VERSION ""

NS_ :

BS_:

BU_: PowertrainControlModule AtmosphericSensor SafetyRestraintSystem2 Aftertreatment_2_GasOutlet Aftertreatment_2_GasIntake DieselParticulateFilterControl Turbocharger SafetyRestraintSystem1 CabDisplay2 Aftertreatment_1_GasOutlet Aftertreatment_1_GasIntake OnBoardDataLogger OffBoardDiagnosticTool2 OffBoardDiagnosticTool1 FileServer ParkingBrakeController SeatController2 FanDriveController SteeringColumnUnit CommunicationUnitRadio CommunicationUnitSatellite CommunicationUnitCellular PropulsionBatteryCharger ChassisController2 ChassisController1 EngineValveControl AuxiliaryHeater2 AuxiliaryHeater1 ClutchUnit RampControl InformationSystem1 SuspensionSystemController2 OilSensor VehicleDynamicStability ExhaustEmissionController TransmissionDisplay2 TransmissionDisplay1 ClimateControl2 WaterPumpController RearAxleSteeringController LightingOperatorControl SeatController1 IgnitionController2 IgnitionController1 TirePressureController CabController2 CabController1 PneumaticSystemController SuspensionSystemController1 HydraulicPumpController EnduranceBrakingSystem RetarderExhaustEngine2 OnBoardDiagnosticUnit HeadwayController RetarderExhaustEngine1 CabDisplay1 ManagementComputer VirtualTerminal OffVehicleGateway PowerTakeOffFront HitchControl AuxiliaryValveControl BodyController TractorTrailerBridge1 StarterSystem ElectricalSystem VehicleSecurity VehicleNavigation AerodynamicControl ElectricalChargingSystem ClimateControl1 TripRecorder InstrumentCluster SuspensionDriveAxle2 SuspensionDriveAxle1 SuspensionSteerAxle SteeringController FuelSystem CruiseControl RetarderDriveline RetarderEngine BrakesDriveAxle2 BrakesDriveAxle1 BrakesSystemController BrakesSteerAxle AxleDrive2 AxleDrive1 AxleSteering PowerTakeOff ShiftConsoleSecondary ShiftConsolePrimary Transmission2 Transmission1 Engine2 Engine1

BO_ 2566588926 NTEEV: 68 Vector__XXX
 SG_ Bin17 : 512|32@1+ (1,0) [0|4211081215] "kWh" Vector__XXX
 SG_ Bin16 : 480|32@1+ (1,0) [0|4211081215] "kWh" Vector__XXX
 SG_ Bin15 : 448|32@1+ (1,0) [0|4211081215] "kWh" Vector__XXX
 SG_ Bin14 : 416|32@1+ (1,0) [0|4211081215] "kWh" Vector__XXX
 SG_ Bin13 : 384|32@1+ (1,0) [0|4211081215] "kWh" Vector__XXX
 SG_ Bin12 : 352|32@1+ (1,0) [0|4211081215] "kWh" Vector__XXX
 SG_ Bin11 : 320|32@1+ (1,0) [0|4211081215] "kWh" Vector__XXX
 SG_ Bin10 : 288|32@1+ (1,0) [0|4211081215] "kWh" Vector__XXX
 SG_ Bin9 : 256|32@1+ (1,0) [0|4211081215] "kWh" Vector__XXX
 SG_ Bin8 : 224|32@1+ (1,0) [0|4211081215] "kWh" Vector__XXX
 SG_ Bin7 : 192|32@1+ (1,0) [0|4211081215] "kWh" Vector__XXX
 SG_ Bin6 : 160|32@1+ (1,0) [0|4211081215] "kWh" Vector__XXX
 SG_ Bin5 : 128|32@1+ (1,0) [0|4211081215] "kWh" Vector__XXX
 SG_ Bin4 : 96|32@1+ (1,0) [0|4211081215] "kWh" Vector__XXX
 SG_ Bin3 : 64|32@1+ (1,0) [0|4211081215] "kWh" Vector__XXX
 SG_ Bin2 : 32|32@1+ (1,0) [0|4211081215] "kWh" Vector__XXX
 SG_ Bin1 : 0|32@1+ (1,0) [0|4211081215] "kWh" Vector__XXX

BO_ 2566588670 NTVMV: 68 Vector__XXX
 SG_ Bin17 : 512|32@1+ (5,0) [0|21055406075] "m" Vector__XXX
 SG_ Bin16 : 480|32@1+ (5,0) [0|21055406075] "m" Vector__XXX
 SG_ Bin15 : 448|32@1+ (5,0) [0|21055406075] "m" Vector__XXX
 SG_ Bin14 : 416|32@1+ (5,0) [0|21055406075] "m" Vector__XXX
 SG_ Bin13 : 384|32@1+ (5,0) [0|21055406075] "m" Vector__XXX
 SG_ Bin12 : 352|32@1+ (5,0) [0|21055406075] "m" Vector__XXX
 SG_ Bin11 : 320|32@1+ (5,0) [0|21055406075] "m" Vector__XXX
 SG_ Bin10 : 288|32@1+ (5,0) [0|21055406075] "m" Vector__XXX
 SG_ Bin9 : 256|32@1+ (5,0) [0|21055406075] "m" Vector__XXX
 SG_ Bin8 : 224|32@1+ (5,0) [0|21055406075] "m" Vector__XXX
 SG_ Bin7 : 192|32@1+ (5,0) [0|21055406075] "m" Vector__XXX
 SG_ Bin6 : 160|32@1+ (5,0) [0|21055406075] "m" Vector__XXX
 SG_ Bin5 : 128|32@1+ (5,0) [0|21055406075] "m" Vector__XXX
 SG_ Bin4 : 96|32@1+ (5,0) [0|21055406075] "m" Vector__XXX
 SG_ Bin3 : 64|32@1+ (5,0) [0|21055406075] "m" Vector__XXX
 SG_ Bin2 : 32|32@1+ (5,0) [0|21055406075] "m" Vector__XXX
 SG_ Bin1 : 0|32@1+ (5,0) [0|21055406075] "m" Vector__XXX

BO_ 2566588414 NTEHV: 68 Vector__XXX
 SG_ Bin17 : 512|32@1+ (1,0) [0|4211081215] "s" Vector__XXX
 SG_ Bin16 : 480|32@1+ (1,0) [0|4211081215] "s" Vector__XXX
 SG_ Bin15 : 448|32@1+ (1,0) [0|4211081215] "s" Vector__XXX
 SG_ Bin14 : 416|32@1+ (1,0) [0|4211081215] "s" Vector__XXX
 SG_ Bin13 : 384|32@1+ (1,0) [0|4211081215] "s" Vector__XXX
 SG_ Bin12 : 352|32@1+ (1,0) [0|4211081215] "s" Vector__XXX
 SG_ Bin11 : 320|32@1+ (1,0) [0|4211081215] "s" Vector__XXX
 SG_ Bin10 : 288|32@1+ (1,0) [0|4211081215] "s" Vector__XXX
 SG_ Bin9 : 256|32@1+ (1,0) [0|4211081215] "s" Vector__XXX
 SG_ Bin8 : 224|32@1+ (1,0) [0|4211081215] "s" Vector__XXX
 SG_ Bin7 : 192|32@1+ (1,0) [0|4211081215] "s" Vector__XXX
 SG_ Bin6 : 160|32@1+ (1,0) [0|4211081215] "s" Vector__XXX
 SG_ Bin5 : 128|32@1+ (1,0) [0|4211081215] "s" Vector__XXX
 SG_ Bin4 : 96|32@1+ (1,0) [0|4211081215] "s" Vector__XXX
 SG_ Bin3 : 64|32@1+ (1,0) [0|4211081215] "s" Vector__XXX
 SG_ Bin2 : 32|32@1+ (1,0) [0|4211081215] "s" Vector__XXX
 SG_ Bin1 : 0|32@1+ (1,0) [0|4211081215] "s" Vector__XXX

BO_ 2566588158 NTFCV: 68 Vector__XXX
 SG_ Bin17 : 512|32@1+ (0.05,0) [0|210554060.75] "l" Vector__XXX
 SG_ Bin16 : 480|32@1+ (0.05,0) [0|210554060.75] "l" Vector__XXX
 SG_ Bin15 : 448|32@1+ (0.05,0) [0|210554060.75] "l" Vector__XXX
 SG_ Bin14 : 416|32@1+ (0.05,0) [0|210554060.75] "l" Vector__XXX
 SG_ Bin13 : 384|32@1+ (0.05,0) [0|210554060.75] "l" Vector__XXX
 SG_ Bin12 : 352|32@1+ (0.05,0) [0|210554060.75] "l" Vector__XXX
 SG_ Bin11 : 320|32@1+ (0.05,0) [0|210554060.75] "l" Vector__XXX
 SG_ Bin10 : 288|32@1+ (0.05,0) [0|210554060.75] "l" Vector__XXX
 SG_ Bin9 : 256|32@1+ (0.05,0) [0|210554060.75] "l" Vector__XXX
 SG_ Bin8 : 224|32@1+ (0.05,0) [0|210554060.75] "l" Vector__XXX
 SG_ Bin7 : 192|32@1+ (0.05,0) [0|210554060.75] "l" Vector__XXX
 SG_ Bin6 : 160|32@1+ (0.05,0) [0|210554060.75] "l" Vector__XXX
 SG_ Bin5 : 128|32@1+ (0.05,0) [0|210554060.75] "l" Vector__XXX
 SG_ Bin4 : 96|32@1+ (0.05,0) [0|210554060.75] "l" Vector__XXX
 SG_ Bin3 : 64|32@1+ (0.05,0) [0|210554060.75] "l" Vector__XXX
 SG_ Bin2 : 32|32@1+ (0.05,0) [0|210554060.75] "l" Vector__XXX
 SG_ Bin1 : 0|32@1+ (0.05,0) [0|210554060.75] "l" Vector__XXX

BO_ 2566587902 NTEEEA: 68 Vector__XXX
 SG_ Bin17 : 512|32@1+ (1,0) [0|4211081215] "kWh" Vector__XXX
 SG_ Bin16 : 480|32@1+ (1,0) [0|4211081215] "kWh" Vector__XXX
 SG_ Bin15 : 448|32@1+ (1,0) [0|4211081215] "kWh" Vector__XXX
 SG_ Bin14 : 416|32@1+ (1,0) [0|4211081215] "kWh" Vector__XXX
 SG_ Bin13 : 384|32@1+ (1,0) [0|4211081215] "kWh" Vector__XXX
 SG_ Bin12 : 352|32@1+ (1,0) [0|4211081215] "kWh" Vector__XXX
 SG_ Bin11 : 320|32@1+ (1,0) [0|4211081215] "kWh" Vector__XXX
 SG_ Bin10 : 288|32@1+ (1,0) [0|4211081215] "kWh" Vector__XXX
 SG_ Bin9 : 256|32@1+ (1,0) [0|4211081215] "kWh" Vector__XXX
 SG_ Bin8 : 224|32@1+ (1,0) [0|4211081215] "kWh" Vector__XXX
 SG_ Bin7 : 192|32@1+ (1,0) [0|4211081215] "kWh" Vector__XXX
 SG_ Bin6 : 160|32@1+ (1,0) [0|4211081215] "kWh" Vector__XXX
 SG_ Bin5 : 128|32@1+ (1,0) [0|4211081215] "kWh" Vector__XXX
 SG_ Bin4 : 96|32@1+ (1,0) [0|4211081215] "kWh" Vector__XXX
 SG_ Bin3 : 64|32@1+ (1,0) [0|4211081215] "kWh" Vector__XXX
 SG_ Bin2 : 32|32@1+ (1,0) [0|4211081215] "kWh" Vector__XXX
 SG_ Bin1 : 0|32@1+ (1,0) [0|4211081215] "kWh" Vector__XXX

BO_ 2566587646 NTVMEA: 68 Vector__XXX
 SG_ Bin17 : 512|32@1+ (5,0) [0|21055406075] "m" Vector__XXX
 SG_ Bin16 : 480|32@1+ (5,0) [0|21055406075] "m" Vector__XXX
 SG_ Bin15 : 448|32@1+ (5,0) [0|21055406075] "m" Vector__XXX
 SG_ Bin14 : 416|32@1+ (5,0) [0|21055406075] "m" Vector__XXX
 SG_ Bin13 : 384|32@1+ (5,0) [0|21055406075] "m" Vector__XXX
 SG_ Bin12 : 352|32@1+ (5,0) [0|21055406075] "m" Vector__XXX
 SG_ Bin11 : 320|32@1+ (5,0) [0|21055406075] "m" Vector__XXX
 SG_ Bin10 : 288|32@1+ (5,0) [0|21055406075] "m" Vector__XXX
 SG_ Bin9 : 256|32@1+ (5,0) [0|21055406075] "m" Vector__XXX
 SG_ Bin8 : 224|32@1+ (5,0) [0|21055406075] "m" Vector__XXX
 SG_ Bin7 : 192|32@1+ (5,0) [0|21055406075] "m" Vector__XXX
 SG_ Bin6 : 160|32@1+ (5,0) [0|21055406075] "m" Vector__XXX
 SG_ Bin5 : 128|32@1+ (5,0) [0|21055406075] "m" Vector__XXX
 SG_ Bin4 : 96|32@1+ (5,0) [0|21055406075] "m" Vector__XXX
 SG_ Bin3 : 64|32@1+ (5,0) [0|21055406075] "m" Vector__XXX
 SG_ Bin2 : 32|32@1+ (5,0) [0|21055406075] "m" Vector__XXX
 SG_ Bin1 : 0|32@1+ (5,0) [0|21055406075] "m" Vector__XXX

BO_ 2566587390 NTEHEA: 68 Vector__XXX
 SG_ Bin17 : 512|32@1+ (1,0) [0|4211081215] "s" Vector__XXX
 SG_ Bin16 : 480|32@1+ (1,0) [0|4211081215] "s" Vector__XXX
 SG_ Bin15 : 448|32@1+ (1,0) [0|4211081215] "s" Vector__XXX
 SG_ Bin14 : 416|32@1+ (1,0) [0|4211081215] "s" Vector__XXX
 SG_ Bin13 : 384|32@1+ (1,0) [0|4211081215] "s" Vector__XXX
 SG_ Bin12 : 352|32@1+ (1,0) [0|4211081215] "s" Vector__XXX
 SG_ Bin11 : 320|32@1+ (1,0) [0|4211081215] "s" Vector__XXX
 SG_ Bin10 : 288|32@1+ (1,0) [0|4211081215] "s" Vector__XXX
 SG_ Bin9 : 256|32@1+ (1,0) [0|4211081215] "s" Vector__XXX
 SG_ Bin8 : 224|32@1+ (1,0) [0|4211081215] "s" Vector__XXX
 SG_ Bin7 : 192|32@1+ (1,0) [0|4211081215] "s" Vector__XXX
 SG_ Bin6 : 160|32@1+ (1,0) [0|4211081215] "s" Vector__XXX
 SG_ Bin5 : 128|32@1+ (1,0) [0|4211081215] "s" Vector__XXX
 SG_ Bin4 : 96|32@1+ (1,0) [0|4211081215] "s" Vector__XXX
 SG_ Bin3 : 64|32@1+ (1,0) [0|4211081215] "s" Vector__XXX
 SG_ Bin2 : 32|32@1+ (1,0) [0|4211081215] "s" Vector__XXX
 SG_ Bin1 : 0|32@1+ (1,0) [0|4211081215] "s" Vector__XXX

BO_ 2566587134 NTFCEA: 68 Vector__XXX
 SG_ Bin17 : 512|32@1+ (0.05,0) [0|210554060.75] "l" Vector__XXX
 SG_ Bin16 : 480|32@1+ (0.05,0) [0|210554060.75] "l" Vector__XXX
 SG_ Bin15 : 448|32@1+ (0.05,0) [0|210554060.75] "l" Vector__XXX
 SG_ Bin14 : 416|32@1+ (0.05,0) [0|210554060.75] "l" Vector__XXX
 SG_ Bin13 : 384|32@1+ (0.05,0) [0|210554060.75] "l" Vector__XXX
 SG_ Bin12 : 352|32@1+ (0.05,0) [0|210554060.75] "l" Vector__XXX
 SG_ Bin11 : 320|32@1+ (0.05,0) [0|210554060.75] "l" Vector__XXX
 SG_ Bin10 : 288|32@1+ (0.05,0) [0|210554060.75] "l" Vector__XXX
 SG_ Bin9 : 256|32@1+ (0.05,0) [0|210554060.75] "l" Vector__XXX
 SG_ Bin8 : 224|32@1+ (0.05,0) [0|210554060.75] "l" Vector__XXX
 SG_ Bin7 : 192|32@1+ (0.05,0) [0|210554060.75] "l" Vector__XXX
 SG_ Bin6 : 160|32@1+ (0.05,0) [0|210554060.75] "l" Vector__XXX
 SG_ Bin5 : 128|32@1+ (0.05,0) [0|210554060.75] "l" Vector__XXX
 SG_ Bin4 : 96|32@1+ (0.05,0) [0|210554060.75] "l" Vector__XXX
 SG_ Bin3 : 64|32@1+ (0.05,0) [0|210554060.75] "l" Vector__XXX
 SG_ Bin2 : 32|32@1+ (0.05,0) [0|210554060.75] "l" Vector__XXX
 SG_ Bin1 : 0|32@1+ (0.05,0) [0|210554060.75] "l" Vector__XXX

BO_ 2566586878 GHGTTL: 8 Vector__XXX
 SG_ GHGTrackingActiveTechVehDist : 16|32@1+ (5,0) [0|21055406075] "m" Vector__XXX
 SG_ GHGTrackingActiveTechTime : 8|32@1+ (1,0) [0|4211081215] "s" Vector__XXX
 SG_ GHGTrackingActiveTechIndex : 0|8@1+ (1,0) [0|255] "" Vector__XXX

BO_ 2566586622 GHGTTA: 8 Vector__XXX
 SG_ GHGTrackingActiveTechVehDist : 16|16@1+ (0.25,0) [0|16063.75] "km" Vector__XXX
 SG_ GHGTrackingActiveTechTime : 8|16@1+ (10,0) [0|642550] "s" Vector__XXX
 SG_ GHGTrackingActiveTechIndex : 0|8@1+ (1,0) [0|255] "" Vector__XXX

BO_ 2566586366 GHGTTS: 8 Vector__XXX
 SG_ GHGTrackingActiveTechVehDist : 16|16@1+ (0.25,0) [0|16063.75] "km" Vector__XXX
 SG_ GHGTrackingActiveTechTime : 8|16@1+ (10,0) [0|642550] "s" Vector__XXX
 SG_ GHGTrackingActiveTechIndex : 0|8@1+ (1,0) [0|255] "" Vector__XXX

BO_ 2566586110 GHGTA: 28 Vector__XXX
 SG_ StopStartTechRunTime : 208|16@1+ (10,0) [0|642550] "s" Vector__XXX
 SG_ AutoEngShutdownTechActCount : 192|16@1+ (1,0) [0|64255] "" Vector__XXX
 SG_ EngPwrTakeOffFuelConsumption : 176|16@1+ (0.5,0) [0|32127.5] "l" Vector__XXX
 SG_ EngPwrTakeOffRunTime : 160|16@1+ (10,0) [0|642550] "s" Vector__XXX
 SG_ EngIdleFuelConsumption : 144|16@1+ (0.5,0) [0|32127.5] "l" Vector__XXX
 SG_ IdleRunTime : 128|16@1+ (10,0) [0|642550] "s" Vector__XXX
 SG_ UrbanSpdRunTime : 112|16@1+ (10,0) [0|642550] "s" Vector__XXX
 SG_ PosKineticEnergyNumerator : 80|32@1+ (1,0) [0|4211081215] "km²/h²" Vector__XXX
 SG_ EngOutEnergy : 64|16@1+ (1,0) [0|64255] "kWh" Vector__XXX
 SG_ EngFuelConsumption : 48|16@1+ (0.5,0) [0|32127.5] "l" Vector__XXX
 SG_ VehFuelConsumption : 32|16@1+ (0.5,0) [0|32127.5] "l" Vector__XXX
 SG_ VehDist : 16|16@1+ (0.25,0) [0|16063.75] "km" Vector__XXX
 SG_ EngRunTime : 0|16@1+ (10,0) [0|642550] "s" Vector__XXX

BO_ 2566585854 GHGTS: 28 Vector__XXX
 SG_ StopStartTechRunTime : 208|16@1+ (10,0) [0|642550] "s" Vector__XXX
 SG_ AutoEngShutdownTechActCount : 192|16@1+ (1,0) [0|64255] "" Vector__XXX
 SG_ EngPwrTakeOffFuelConsumption : 176|16@1+ (0.5,0) [0|32127.5] "l" Vector__XXX
 SG_ EngPwrTakeOffRunTime : 160|16@1+ (10,0) [0|642550] "s" Vector__XXX
 SG_ EngIdleFuelConsumption : 144|16@1+ (0.5,0) [0|32127.5] "l" Vector__XXX
 SG_ IdleRunTime : 128|16@1+ (10,0) [0|642550] "s" Vector__XXX
 SG_ UrbanSpdRunTime : 112|16@1+ (10,0) [0|642550] "s" Vector__XXX
 SG_ PosKineticEnergyNumerator : 80|32@1+ (1,0) [0|4211081215] "km²/h²" Vector__XXX
 SG_ EngOutEnergy : 64|16@1+ (1,0) [0|64255] "kWh" Vector__XXX
 SG_ EngFuelConsumption : 48|16@1+ (0.5,0) [0|32127.5] "l" Vector__XXX
 SG_ VehFuelConsumption : 32|16@1+ (0.5,0) [0|32127.5] "l" Vector__XXX
 SG_ VehDist : 16|16@1+ (0.25,0) [0|16063.75] "km" Vector__XXX
 SG_ EngRunTime : 0|16@1+ (10,0) [0|642550] "s" Vector__XXX

BO_ 2566585598 GHGTL: 52 Vector__XXX
 SG_ StopStartTechRunTime : 384|32@1+ (1,0) [0|4211081215] "s" Vector__XXX
 SG_ AutoEngShutdownTechActCount : 352|32@1+ (1,0) [0|4294967295] "" Vector__XXX
 SG_ EngPwrTakeOffFuelConsumption : 320|32@1+ (0.05,0) [0|210554060.75] "l" Vector__XXX
 SG_ EngPwrTakeOffRunTime : 288|32@1+ (1,0) [0|4211081215] "s" Vector__XXX
 SG_ EngIdleFuelConsumption : 256|32@1+ (0.05,0) [0|210554060.75] "l" Vector__XXX
 SG_ IdleRunTime : 224|32@1+ (1,0) [0|4211081215] "s" Vector__XXX
 SG_ UrbanSpdRunTime : 192|32@1+ (1,0) [0|4211081215] "s" Vector__XXX
 SG_ PosKineticEnergyNumerator : 160|32@1+ (5,0) [0|21055406075] "km²/h²" Vector__XXX
 SG_ EngOutEnergy : 128|32@1+ (1,0) [0|4211081215] "kWh" Vector__XXX
 SG_ EngFuelConsumption : 96|32@1+ (0.05,0) [0|210554060.75] "l" Vector__XXX
 SG_ VehFuelConsumption : 64|32@1+ (0.05,0) [0|210554060.75] "l" Vector__XXX
 SG_ VehDist : 32|32@1+ (5,0) [0|21055406075] "m" Vector__XXX
 SG_ EngRunTime : 0|32@1+ (1,0) [0|4211081215] "s" Vector__XXX

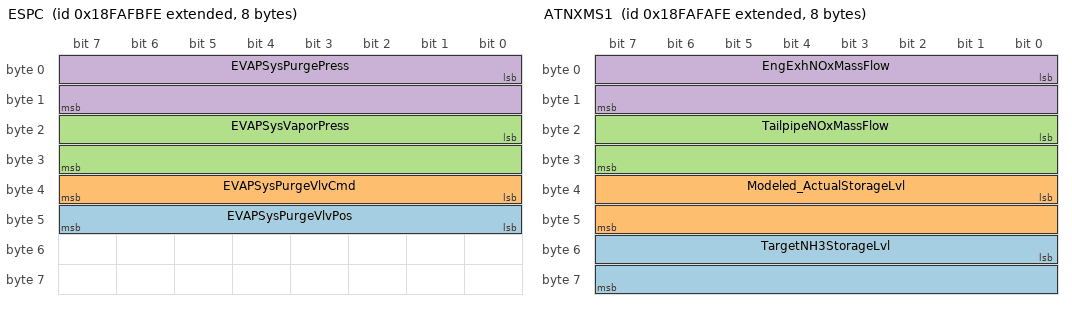
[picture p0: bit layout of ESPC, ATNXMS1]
BO_ 2566585342 ESPC: 8 Vector__XXX
 SG_ EVAPSysPurgeVlvPos : 40|8@1+ (0.4,0) [0|100] "%" Vector__XXX
 SG_ EVAPSysPurgeVlvCmd : 32|8@1+ (0.4,0) [0|100] "%" Vector__XXX
 SG_ EVAPSysVaporPress : 16|16@1+ (4,0) [0|257020] "Pa" Vector__XXX
 SG_ EVAPSysPurgePress : 0|16@1+ (4,0) [0|257020] "Pa" Vector__XXX

BO_ 2566585086 ATNXMS1: 8 Vector__XXX
 SG_ TargetNH3StorageLvl : 48|16@1+ (1,0) [0|64255] "mg/l" Vector__XXX
 SG_ Modeled_ActualStorageLvl : 32|16@1+ (1,0) [0|64255] "mg/l" Vector__XXX
 SG_ TailpipeNOxMassFlow : 16|16@1+ (0.0001,0) [0|6.4255] "g/s" Vector__XXX
 SG_ EngExhNOxMassFlow : 0|16@1+ (0.0001,0) [0|6.4255] "g/s" Vector__XXX

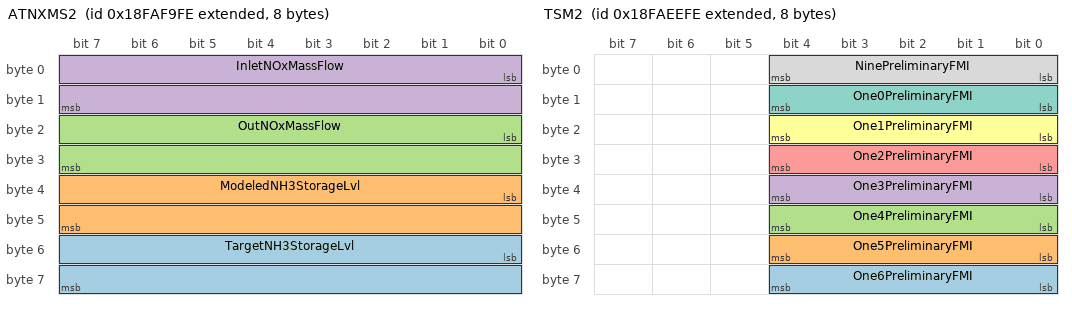
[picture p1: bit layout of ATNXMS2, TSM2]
BO_ 2566584830 ATNXMS2: 8 Vector__XXX
 SG_ TargetNH3StorageLvl : 48|16@1+ (1,0) [0|64255] "mg/l" Vector__XXX
 SG_ ModeledNH3StorageLvl : 32|16@1+ (1,0) [0|64255] "mg/l" Vector__XXX
 SG_ OutNOxMassFlow : 16|16@1+ (0.0001,0) [0|6.4255] "g/s" Vector__XXX
 SG_ InletNOxMassFlow : 0|16@1+ (0.0001,0) [0|6.4255] "g/s" Vector__XXX

BO_ 2566584318 AT1HI3: 32 Vector__XXX
 SG_ TotalTimeSCRInletTempBelow200Cel : 224|32@1+ (1,0) [0|4211081215] "s" Vector__XXX
 SG_ TotalEngRuntimeWithNoDEFDel : 192|32@1+ (1,0) [0|4211081215] "s" Vector__XXX
 SG_ EndingEngVehDist3 : 160|32@1+ (5,0) [0|21055406075] "m" Vector__XXX
 SG_ StartingEngVehDist3 : 128|32@1+ (5,0) [0|21055406075] "m" Vector__XXX
 SG_ EndingEngVehDist2 : 96|32@1+ (0.125,0) [0|526385151.875] "km" Vector__XXX
 SG_ StartingEngVehDist2 : 64|32@1+ (5,0) [0|21055406075] "m" Vector__XXX
 SG_ EndingEngVehDist1 : 32|32@1+ (5,0) [0|21055406075] "m" Vector__XXX
 SG_ StartingEngVehDist1 : 0|32@1+ (5,0) [0|21055406075] "m" Vector__XXX

BO_ 2566584062 HCDIOA: 16 Vector__XXX
 SG_ GridEnergyIntoTheBat : 112|16@1+ (1,0) [0|64255] "kWh" Vector__XXX
 SG_ GridEnergyChargeDepletingEngRun : 96|16@1+ (1,0) [0|64255] "kWh" Vector__XXX
 SG_ GridEnergyChargeDepletingEngOff : 80|16@1+ (1,0) [0|64255] "kWh" Vector__XXX
 SG_ FuelInDriverSelChargeIncOp : 64|16@1+ (0.5,0) [0|32127.5] "l" Vector__XXX
 SG_ FuelInChargeDepletingOp : 48|16@1+ (0.5,0) [0|32127.5] "l" Vector__XXX
 SG_ DistInDriverSelChargeIncOp : 32|16@1+ (0.25,0) [0|16063.75] "km" Vector__XXX
 SG_ DistInChargeDepletingEngRun : 16|16@1+ (0.25,0) [0|16063.75] "km" Vector__XXX
 SG_ DistInChargeDepletingEngOff : 0|16@1+ (0.25,0) [0|16063.75] "km" Vector__XXX

BO_ 2566583806 HCDIOS: 16 Vector__XXX
 SG_ GridEnergyIntoTheBat : 112|16@1+ (1,0) [0|64255] "kWh" Vector__XXX
 SG_ GridEnergyChargeDepletingEngRun : 96|16@1+ (1,0) [0|64255] "kWh" Vector__XXX
 SG_ GridEnergyChargeDepletingEngOff : 80|16@1+ (1,0) [0|64255] "kWh" Vector__XXX
 SG_ FuelInDriverSelChargeIncOp : 64|16@1+ (0.5,0) [0|32127.5] "l" Vector__XXX
 SG_ FuelInChargeDepletingOp : 48|16@1+ (0.5,0) [0|32127.5] "l" Vector__XXX
 SG_ DistInDriverSelChargeIncOp : 32|16@1+ (0.25,0) [0|16063.75] "km" Vector__XXX
 SG_ DistInChargeDepletingEngRun : 16|16@1+ (0.25,0) [0|16063.75] "km" Vector__XXX
 SG_ DistInChargeDepletingEngOff : 0|16@1+ (0.25,0) [0|16063.75] "km" Vector__XXX

BO_ 2566583550 HCDIOL: 32 Vector__XXX
 SG_ GridEnergyIntoTheBat : 224|32@1+ (1,0) [0|4211081215] "kWh" Vector__XXX
 SG_ GridEnergyChargeDepletingEngRun : 192|32@1+ (1,0) [0|4211081215] "kWh" Vector__XXX
 SG_ GridEnergyChargeDepletingEngOff : 160|32@1+ (1,0) [0|4211081215] "kWh" Vector__XXX
 SG_ FuelInDriverSelChargeIncOp : 128|32@1+ (0.5,0) [0|2105540607.5] "l" Vector__XXX
 SG_ FuelInChargeDepletingOp : 96|32@1+ (0.5,0) [0|2105540607.5] "l" Vector__XXX
 SG_ DistInDriverSelChargeIncOp : 64|32@1+ (5,0) [0|21055406075] "m" Vector__XXX
 SG_ DistInChargeDepletingEngRun : 32|32@1+ (5,0) [0|21055406075] "m" Vector__XXX
 SG_ DistInChargeDepletingEngOff : 0|32@1+ (5,0) [0|21055406075] "m" Vector__XXX

BO_ 2566583294 PSATA: 8 Vector__XXX
 SG_ UrbanPropulsionSysActiveTime : 32|16@1+ (10,0) [0|642550] "s" Vector__XXX
 SG_ IdlePropulsionSysActiveTime : 16|16@1+ (10,0) [0|642550] "s" Vector__XXX
 SG_ PropulsionSysActiveTime : 0|16@1+ (10,0) [0|642550] "s" Vector__XXX

BO_ 2566583038 PSATS: 8 Vector__XXX
 SG_ UrbanPropulsionSysActiveTime : 32|16@1+ (10,0) [0|642550] "s" Vector__XXX
 SG_ IdlePropulsionSysActiveTime : 16|16@1+ (10,0) [0|642550] "s" Vector__XXX
 SG_ RecentPropulsionSysActiveTime : 0|16@1+ (10,0) [0|642550] "s" Vector__XXX

BO_ 2566582782 PSATL: 12 Vector__XXX
 SG_ UrbanPropulsionSysActiveTime : 64|32@1+ (1,0) [0|4211081215] "s" Vector__XXX
 SG_ IdlePropulsionSysActiveTime : 32|32@1+ (1,0) [0|4211081215] "s" Vector__XXX
 SG_ PropulsionSysActiveTime : 0|32@1+ (1,0) [0|4211081215] "s" Vector__XXX

BO_ 2566582526 A1SCRSI3: 8 Vector__XXX
 SG_ DEFUsedThisOperatingCycle : 8|16@1+ (0.1,0) [0|6425.5] "l" Vector__XXX
 SG_ NormalizedConversionEfficiency : 0|8@1+ (0.4,0) [0|100] "%" Vector__XXX

BO_ 2566582270 A2SCRSI3: 8 Vector__XXX
 SG_ NormalizedConversionEfficiency : 0|8@1+ (0.4,0) [0|100] "%" Vector__XXX

BO_ 2566582014 TSM2: 8 Vector__XXX
 SG_ One6PreliminaryFMI : 56|5@1+ (1,0) [0|31] "" Vector__XXX
 SG_ One5PreliminaryFMI : 48|5@1+ (1,0) [0|31] "" Vector__XXX
 SG_ One4PreliminaryFMI : 40|5@1+ (1,0) [0|31] "" Vector__XXX
 SG_ One3PreliminaryFMI : 32|5@1+ (1,0) [0|31] "" Vector__XXX
 SG_ One2PreliminaryFMI : 24|5@1+ (1,0) [0|31] "" Vector__XXX
 SG_ One1PreliminaryFMI : 16|5@1+ (1,0) [0|31] "" Vector__XXX
 SG_ One0PreliminaryFMI : 8|5@1+ (1,0) [0|31] "" Vector__XXX
 SG_ NinePreliminaryFMI : 0|5@1+ (1,0) [0|31] "" Vector__XXX

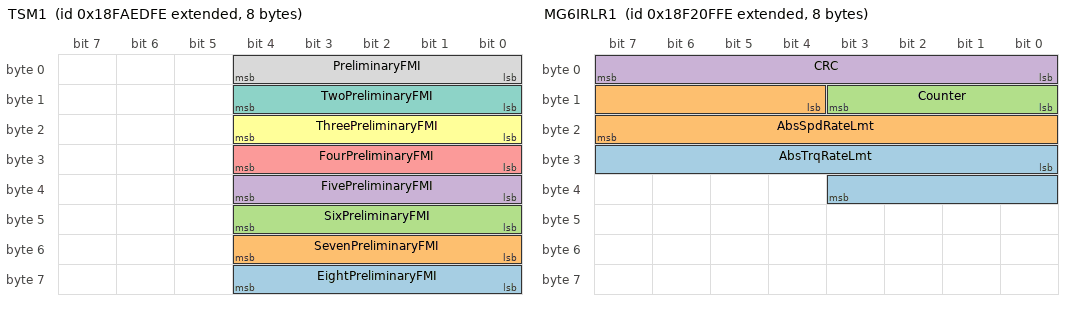
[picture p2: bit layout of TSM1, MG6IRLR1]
BO_ 2566581758 TSM1: 8 Vector__XXX
 SG_ EightPreliminaryFMI : 56|5@1+ (1,0) [0|31] "" Vector__XXX
 SG_ SevenPreliminaryFMI : 48|5@1+ (1,0) [0|31] "" Vector__XXX
 SG_ SixPreliminaryFMI : 40|5@1+ (1,0) [0|31] "" Vector__XXX
 SG_ FivePreliminaryFMI : 32|5@1+ (1,0) [0|31] "" Vector__XXX
 SG_ FourPreliminaryFMI : 24|5@1+ (1,0) [0|31] "" Vector__XXX
 SG_ ThreePreliminaryFMI : 16|5@1+ (1,0) [0|31] "" Vector__XXX
 SG_ TwoPreliminaryFMI : 8|5@1+ (1,0) [0|31] "" Vector__XXX
 SG_ PreliminaryFMI : 0|5@1+ (1,0) [0|31] "" Vector__XXX

BO_ 2566000638 MG6IRLR1: 8 Vector__XXX
 SG_ AbsTrqRateLmt : 24|12@1+ (2,0) [0|8030] "%/s" Vector__XXX
 SG_ AbsSpdRateLmt : 12|12@1+ (0.25,0) [0|1003.75] "%/s" Vector__XXX
 SG_ Counter : 8|4@1+ (1,0) [0|15] "" Vector__XXX
 SG_ CRC : 0|8@1+ (1,0) [0|255] "" Vector__XXX

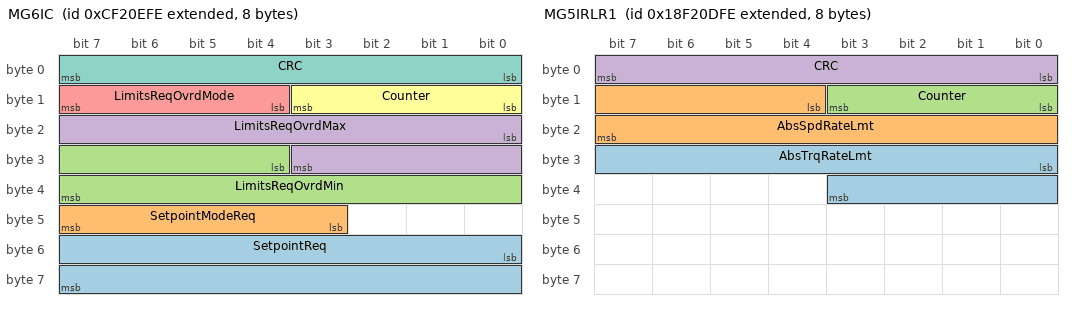
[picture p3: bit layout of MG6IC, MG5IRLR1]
BO_ 2364673790 MG6IC: 8 Vector__XXX
 SG_ SetpointReq : 48|16@1+ (0.00390625,-125) [-125|125.99609375] "%" Vector__XXX
 SG_ SetpointModeReq : 43|5@1+ (1,0) [0|31] "" Vector__XXX
 SG_ LimitsReqOvrdMin : 28|12@1+ (0.0625,-125) [-125|125.9375] "%" Vector__XXX
 SG_ LimitsReqOvrdMax : 16|12@1+ (0.0625,-125) [-125|125.9375] "%" Vector__XXX
 SG_ LimitsReqOvrdMode : 12|4@1+ (1,0) [0|15] "" Vector__XXX
 SG_ Counter : 8|4@1+ (1,0) [0|15] "" Vector__XXX
 SG_ CRC : 0|8@1+ (1,0) [0|255] "" Vector__XXX

BO_ 2566000126 MG5IRLR1: 8 Vector__XXX
 SG_ AbsTrqRateLmt : 24|12@1+ (2,0) [0|8030] "%/s" Vector__XXX
 SG_ AbsSpdRateLmt : 12|12@1+ (0.25,0) [0|1003.75] "%/s" Vector__XXX
 SG_ Counter : 8|4@1+ (1,0) [0|15] "" Vector__XXX
 SG_ CRC : 0|8@1+ (1,0) [0|255] "" Vector__XXX

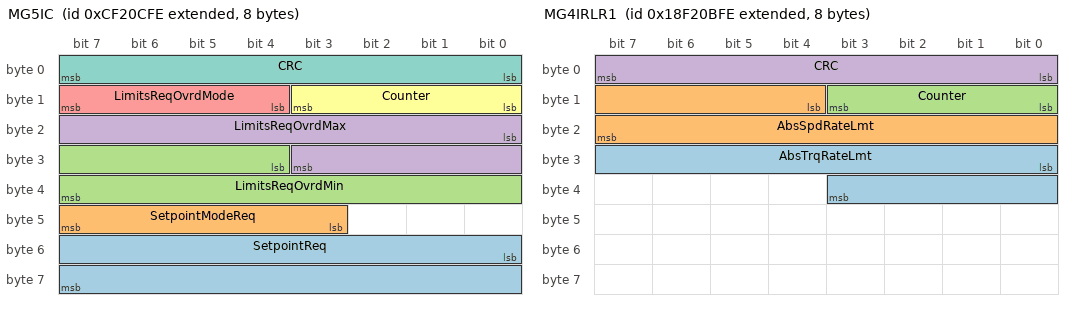
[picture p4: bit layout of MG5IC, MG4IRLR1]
BO_ 2364673278 MG5IC: 8 Vector__XXX
 SG_ SetpointReq : 48|16@1+ (0.00390625,-125) [-125|125.99609375] "%" Vector__XXX
 SG_ SetpointModeReq : 43|5@1+ (1,0) [0|31] "" Vector__XXX
 SG_ LimitsReqOvrdMin : 28|12@1+ (0.0625,-125) [-125|125.9375] "%" Vector__XXX
 SG_ LimitsReqOvrdMax : 16|12@1+ (0.0625,-125) [-125|125.9375] "%" Vector__XXX
 SG_ LimitsReqOvrdMode : 12|4@1+ (1,0) [0|15] "" Vector__XXX
 SG_ Counter : 8|4@1+ (1,0) [0|15] "" Vector__XXX
 SG_ CRC : 0|8@1+ (1,0) [0|255] "" Vector__XXX

BO_ 2565999614 MG4IRLR1: 8 Vector__XXX
 SG_ AbsTrqRateLmt : 24|12@1+ (2,0) [0|8030] "%/s" Vector__XXX
 SG_ AbsSpdRateLmt : 12|12@1+ (0.25,0) [0|1003.75] "%/s" Vector__XXX
 SG_ Counter : 8|4@1+ (1,0) [0|15] "" Vector__XXX
 SG_ CRC : 0|8@1+ (1,0) [0|255] "" Vector__XXX

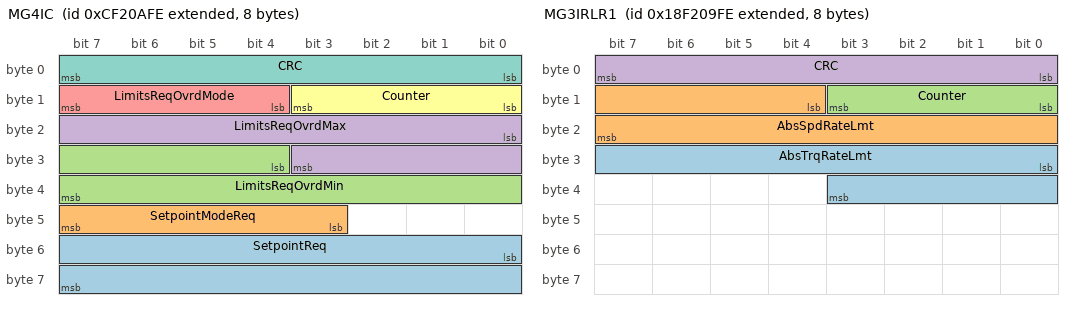
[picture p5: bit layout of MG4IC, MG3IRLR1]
BO_ 2364672766 MG4IC: 8 Vector__XXX
 SG_ SetpointReq : 48|16@1+ (0.00390625,-125) [-125|125.99609375] "%" Vector__XXX
 SG_ SetpointModeReq : 43|5@1+ (1,0) [0|31] "" Vector__XXX
 SG_ LimitsReqOvrdMin : 28|12@1+ (0.0625,-125) [-125|125.9375] "%" Vector__XXX
 SG_ LimitsReqOvrdMax : 16|12@1+ (0.0625,-125) [-125|125.9375] "%" Vector__XXX
 SG_ LimitsReqOvrdMode : 12|4@1+ (1,0) [0|15] "" Vector__XXX
 SG_ Counter : 8|4@1+ (1,0) [0|15] "" Vector__XXX
 SG_ CRC : 0|8@1+ (1,0) [0|255] "" Vector__XXX

BO_ 2565999102 MG3IRLR1: 8 Vector__XXX
 SG_ AbsTrqRateLmt : 24|12@1+ (2,0) [0|8030] "%/s" Vector__XXX
 SG_ AbsSpdRateLmt : 12|12@1+ (0.25,0) [0|1003.75] "%/s" Vector__XXX
 SG_ Counter : 8|4@1+ (1,0) [0|15] "" Vector__XXX
 SG_ CRC : 0|8@1+ (1,0) [0|255] "" Vector__XXX

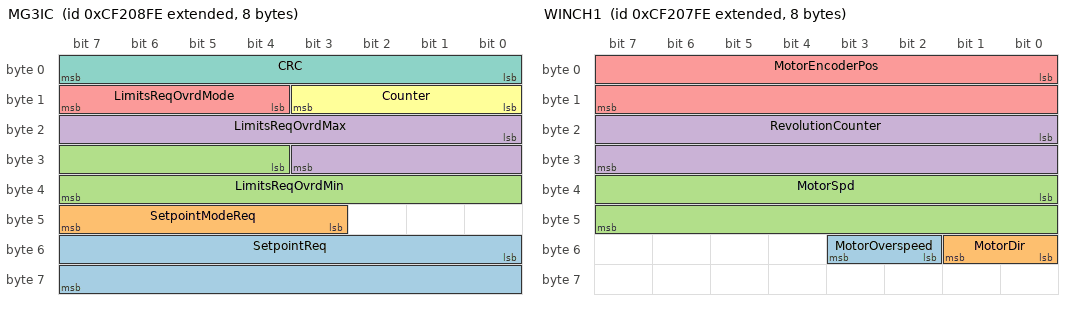
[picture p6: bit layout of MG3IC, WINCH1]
BO_ 2364672254 MG3IC: 8 Vector__XXX
 SG_ SetpointReq : 48|16@1+ (0.00390625,-125) [-125|125.99609375] "%" Vector__XXX
 SG_ SetpointModeReq : 43|5@1+ (1,0) [0|31] "" Vector__XXX
 SG_ LimitsReqOvrdMin : 28|12@1+ (0.0625,-125) [-125|125.9375] "%" Vector__XXX
 SG_ LimitsReqOvrdMax : 16|12@1+ (0.0625,-125) [-125|125.9375] "%" Vector__XXX
 SG_ LimitsReqOvrdMode : 12|4@1+ (1,0) [0|15] "" Vector__XXX
 SG_ Counter : 8|4@1+ (1,0) [0|15] "" Vector__XXX
 SG_ CRC : 0|8@1+ (1,0) [0|255] "" Vector__XXX

BO_ 2364671998 WINCH1: 8 Vector__XXX
 SG_ MotorOverspeed : 50|2@1+ (1,0) [0|3] "" Vector__XXX
 SG_ MotorDir : 48|2@1+ (1,0) [0|3] "" Vector__XXX
 SG_ MotorSpd : 32|16@1+ (0.125,0) [0|8031.875] "rpm" Vector__XXX
 SG_ RevolutionCounter : 16|16@1+ (1,-32128) [-32128|32127] "" Vector__XXX
 SG_ MotorEncoderPos : 0|16@1+ (1,0) [0|32767] "" Vector__XXX

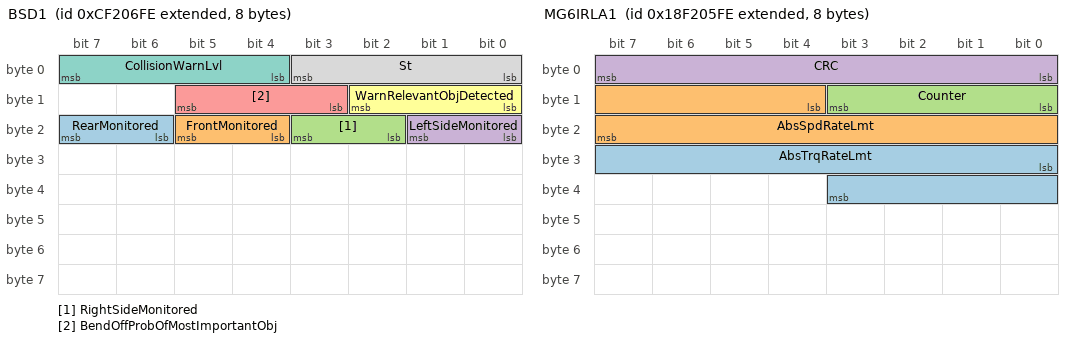
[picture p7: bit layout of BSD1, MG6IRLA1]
BO_ 2364671742 BSD1: 8 Vector__XXX
 SG_ RearMonitored : 22|2@1+ (1,0) [0|3] "" Vector__XXX
 SG_ FrontMonitored : 20|2@1+ (1,0) [0|3] "" Vector__XXX
 SG_ RightSideMonitored : 18|2@1+ (1,0) [0|3] "" Vector__XXX
 SG_ LeftSideMonitored : 16|2@1+ (1,0) [0|3] "" Vector__XXX
 SG_ BendOffProbOfMostImportantObj : 11|3@1+ (1,0) [0|7] "" Vector__XXX
 SG_ WarnRelevantObjDetected : 8|3@1+ (1,0) [0|7] "" Vector__XXX
 SG_ CollisionWarnLvl : 4|4@1+ (1,0) [0|15] "" Vector__XXX
 SG_ St : 0|4@1+ (1,0) [0|15] "" Vector__XXX

BO_ 2565998078 MG6IRLA1: 8 Vector__XXX
 SG_ AbsTrqRateLmt : 24|12@1+ (2,0) [0|8030] "%/s" Vector__XXX
 SG_ AbsSpdRateLmt : 12|12@1+ (0.25,0) [0|1003.75] "%/s" Vector__XXX
 SG_ Counter : 8|4@1+ (1,0) [0|15] "" Vector__XXX
 SG_ CRC : 0|8@1+ (1,0) [0|255] "" Vector__XXX

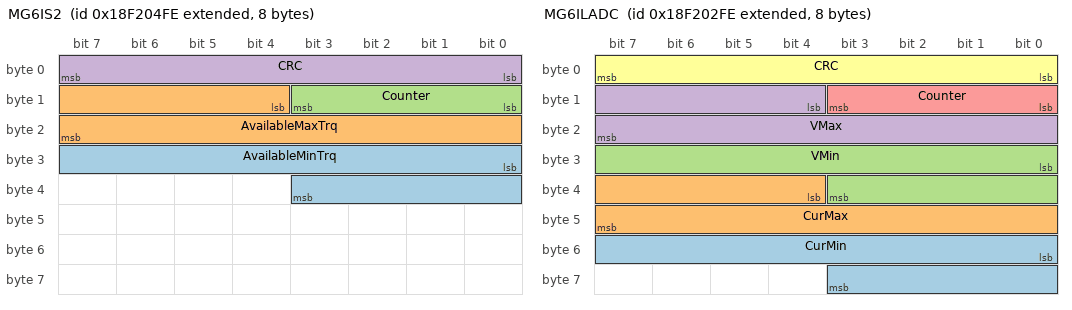
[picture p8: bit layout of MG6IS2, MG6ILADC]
BO_ 2565997822 MG6IS2: 8 Vector__XXX
 SG_ AvailableMinTrq : 24|12@1+ (0.0625,-125) [-125|125.9375] "%" Vector__XXX
 SG_ AvailableMaxTrq : 12|12@1+ (0.0625,-125) [-125|125.9375] "%" Vector__XXX
 SG_ Counter : 8|4@1+ (1,0) [0|15] "" Vector__XXX
 SG_ CRC : 0|8@1+ (1,0) [0|255] "" Vector__XXX

BO_ 2565997566 MG6ILV: 8 Vector__XXX
 SG_ UnswitchedSLIV : 16|16@1+ (0.05,0) [0|3212.75] "V" Vector__XXX
 SG_ SwitchedIgntV : 0|16@1+ (0.05,0) [0|3212.75] "V" Vector__XXX

BO_ 2565997310 MG6ILADC: 8 Vector__XXX
 SG_ CurMin : 48|12@1+ (0.0625,-125) [-125|125.9375] "%" Vector__XXX
 SG_ CurMax : 36|12@1+ (0.0625,-125) [-125|125.9375] "%" Vector__XXX
 SG_ VMin : 24|12@1+ (0.0625,-125) [-125|125.9375] "%" Vector__XXX
 SG_ VMax : 12|12@1+ (0.0625,-125) [-125|125.9375] "%" Vector__XXX
 SG_ Counter : 8|4@1+ (1,0) [0|15] "" Vector__XXX
 SG_ CRC : 0|8@1+ (1,0) [0|255] "" Vector__XXX

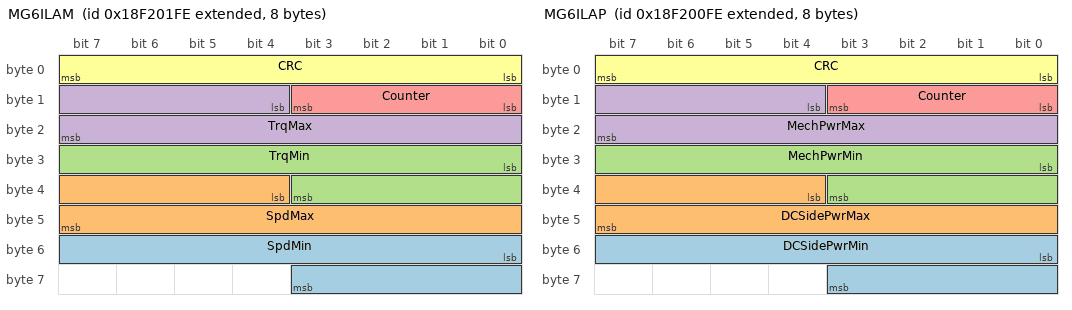
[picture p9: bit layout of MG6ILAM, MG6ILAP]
BO_ 2565997054 MG6ILAM: 8 Vector__XXX
 SG_ SpdMin : 48|12@1+ (0.0625,-125) [-125|125.9375] "%" Vector__XXX
 SG_ SpdMax : 36|12@1+ (0.0625,-125) [-125|125.9375] "%" Vector__XXX
 SG_ TrqMin : 24|12@1+ (0.0625,-125) [-125|125.9375] "%" Vector__XXX
 SG_ TrqMax : 12|12@1+ (0.0625,-125) [-125|125.9375] "%" Vector__XXX
 SG_ Counter : 8|4@1+ (1,0) [0|15] "" Vector__XXX
 SG_ CRC : 0|8@1+ (1,0) [0|255] "" Vector__XXX

BO_ 2565996798 MG6ILAP: 8 Vector__XXX
 SG_ DCSidePwrMin : 48|12@1+ (0.0625,-125) [-125|125.9375] "%" Vector__XXX
 SG_ DCSidePwrMax : 36|12@1+ (0.0625,-125) [-125|125.9375] "%" Vector__XXX
 SG_ MechPwrMin : 24|12@1+ (0.0625,-125) [-125|125.9375] "%" Vector__XXX
 SG_ MechPwrMax : 12|12@1+ (0.0625,-125) [-125|125.9375] "%" Vector__XXX
 SG_ Counter : 8|4@1+ (1,0) [0|15] "" Vector__XXX
 SG_ CRC : 0|8@1+ (1,0) [0|255] "" Vector__XXX

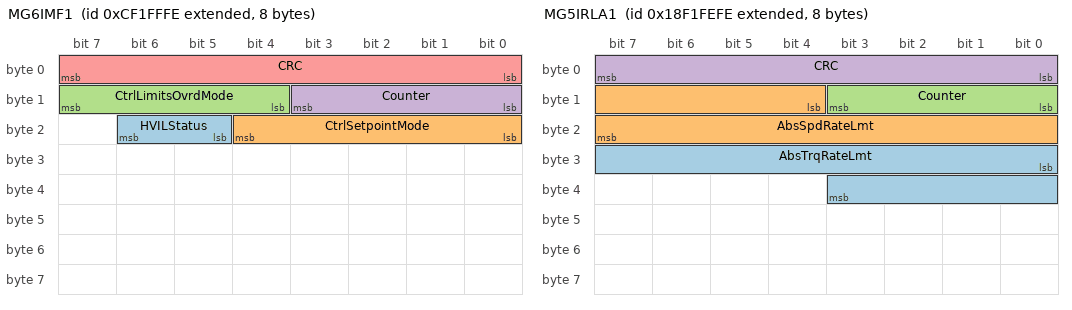
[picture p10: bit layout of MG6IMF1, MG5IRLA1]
BO_ 2364669950 MG6IMF1: 8 Vector__XXX
 SG_ HVILStatus : 21|2@1+ (1,0) [0|3] "" Vector__XXX
 SG_ CtrlSetpointMode : 16|5@1+ (1,0) [0|31] "" Vector__XXX
 SG_ CtrlLimitsOvrdMode : 12|4@1+ (1,0) [0|15] "" Vector__XXX
 SG_ Counter : 8|4@1+ (1,0) [0|15] "" Vector__XXX
 SG_ CRC : 0|8@1+ (1,0) [0|255] "" Vector__XXX

BO_ 2565996286 MG5IRLA1: 8 Vector__XXX
 SG_ AbsTrqRateLmt : 24|12@1+ (2,0) [0|8030] "%/s" Vector__XXX
 SG_ AbsSpdRateLmt : 12|12@1+ (0.25,0) [0|1003.75] "%/s" Vector__XXX
 SG_ Counter : 8|4@1+ (1,0) [0|15] "" Vector__XXX
 SG_ CRC : 0|8@1+ (1,0) [0|255] "" Vector__XXX

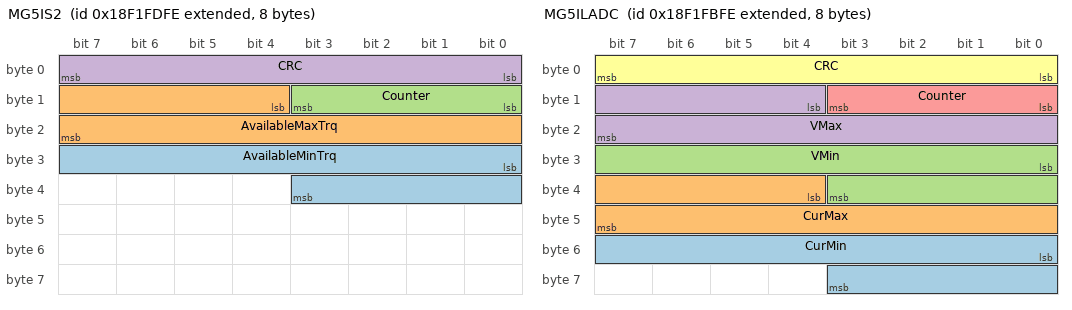
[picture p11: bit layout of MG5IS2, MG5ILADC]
BO_ 2565996030 MG5IS2: 8 Vector__XXX
 SG_ AvailableMinTrq : 24|12@1+ (0.0625,-125) [-125|125.9375] "%" Vector__XXX
 SG_ AvailableMaxTrq : 12|12@1+ (0.0625,-125) [-125|125.9375] "%" Vector__XXX
 SG_ Counter : 8|4@1+ (1,0) [0|15] "" Vector__XXX
 SG_ CRC : 0|8@1+ (1,0) [0|255] "" Vector__XXX

BO_ 2565995774 MG5ILV: 8 Vector__XXX
 SG_ UnswitchedSLIV : 16|16@1+ (0.05,0) [0|3212.75] "V" Vector__XXX
 SG_ SwitchedIgntV : 0|16@1+ (0.05,0) [0|3212.75] "V" Vector__XXX

BO_ 2565995518 MG5ILADC: 8 Vector__XXX
 SG_ CurMin : 48|12@1+ (0.0625,-125) [-125|125.9375] "%" Vector__XXX
 SG_ CurMax : 36|12@1+ (0.0625,-125) [-125|125.9375] "%" Vector__XXX
 SG_ VMin : 24|12@1+ (0.0625,-125) [-125|125.9375] "%" Vector__XXX
 SG_ VMax : 12|12@1+ (0.0625,-125) [-125|125.9375] "%" Vector__XXX
 SG_ Counter : 8|4@1+ (1,0) [0|15] "" Vector__XXX
 SG_ CRC : 0|8@1+ (1,0) [0|255] "" Vector__XXX

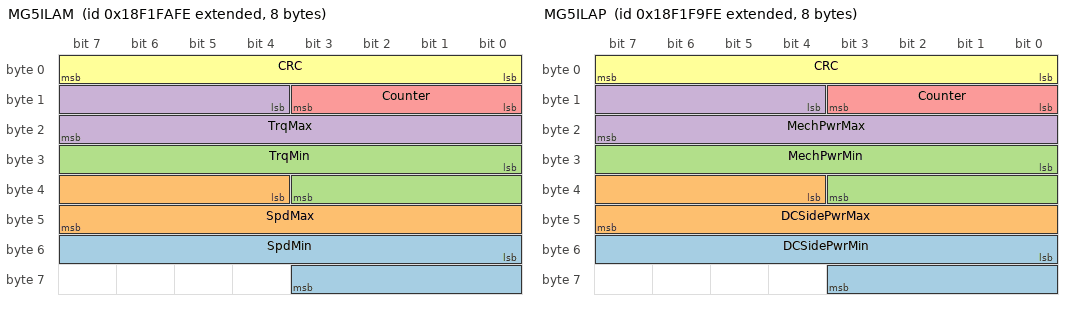
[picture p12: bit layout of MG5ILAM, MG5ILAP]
BO_ 2565995262 MG5ILAM: 8 Vector__XXX
 SG_ SpdMin : 48|12@1+ (0.0625,-125) [-125|125.9375] "%" Vector__XXX
 SG_ SpdMax : 36|12@1+ (0.0625,-125) [-125|125.9375] "%" Vector__XXX
 SG_ TrqMin : 24|12@1+ (0.0625,-125) [-125|125.9375] "%" Vector__XXX
 SG_ TrqMax : 12|12@1+ (0.0625,-125) [-125|125.9375] "%" Vector__XXX
 SG_ Counter : 8|4@1+ (1,0) [0|15] "" Vector__XXX
 SG_ CRC : 0|8@1+ (1,0) [0|255] "" Vector__XXX

BO_ 2565995006 MG5ILAP: 8 Vector__XXX
 SG_ DCSidePwrMin : 48|12@1+ (0.0625,-125) [-125|125.9375] "%" Vector__XXX
 SG_ DCSidePwrMax : 36|12@1+ (0.0625,-125) [-125|125.9375] "%" Vector__XXX
 SG_ MechPwrMin : 24|12@1+ (0.0625,-125) [-125|125.9375] "%" Vector__XXX
 SG_ MechPwrMax : 12|12@1+ (0.0625,-125) [-125|125.9375] "%" Vector__XXX
 SG_ Counter : 8|4@1+ (1,0) [0|15] "" Vector__XXX
 SG_ CRC : 0|8@1+ (1,0) [0|255] "" Vector__XXX

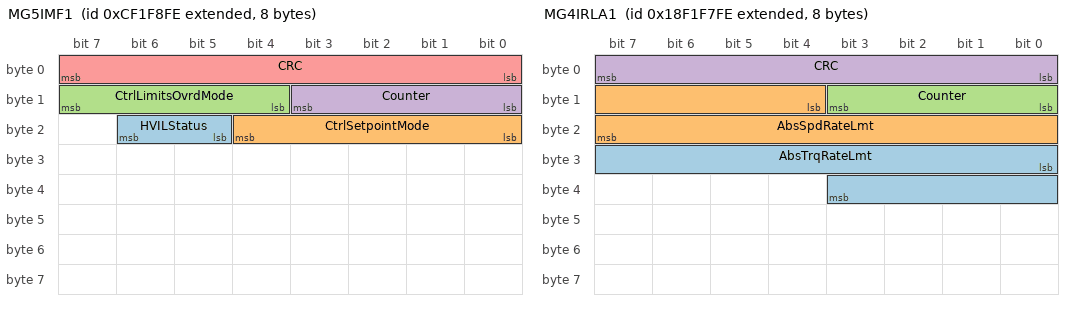
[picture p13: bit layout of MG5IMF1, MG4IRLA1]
BO_ 2364668158 MG5IMF1: 8 Vector__XXX
 SG_ HVILStatus : 21|2@1+ (1,0) [0|3] "" Vector__XXX
 SG_ CtrlSetpointMode : 16|5@1+ (1,0) [0|31] "" Vector__XXX
 SG_ CtrlLimitsOvrdMode : 12|4@1+ (1,0) [0|15] "" Vector__XXX
 SG_ Counter : 8|4@1+ (1,0) [0|15] "" Vector__XXX
 SG_ CRC : 0|8@1+ (1,0) [0|255] "" Vector__XXX

BO_ 2565994494 MG4IRLA1: 8 Vector__XXX
 SG_ AbsTrqRateLmt : 24|12@1+ (2,0) [0|8030] "%/s" Vector__XXX
 SG_ AbsSpdRateLmt : 12|12@1+ (0.25,0) [0|1003.75] "%/s" Vector__XXX
 SG_ Counter : 8|4@1+ (1,0) [0|15] "" Vector__XXX
 SG_ CRC : 0|8@1+ (1,0) [0|255] "" Vector__XXX

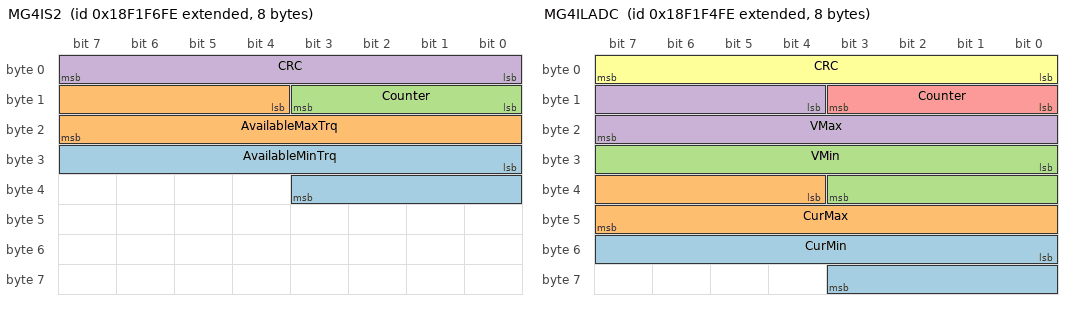
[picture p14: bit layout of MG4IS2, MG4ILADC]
BO_ 2565994238 MG4IS2: 8 Vector__XXX
 SG_ AvailableMinTrq : 24|12@1+ (0.0625,-125) [-125|125.9375] "%" Vector__XXX
 SG_ AvailableMaxTrq : 12|12@1+ (0.0625,-125) [-125|125.9375] "%" Vector__XXX
 SG_ Counter : 8|4@1+ (1,0) [0|15] "" Vector__XXX
 SG_ CRC : 0|8@1+ (1,0) [0|255] "" Vector__XXX

BO_ 2565993982 MG4ILV: 8 Vector__XXX
 SG_ UnswitchedSLIV : 16|16@1+ (0.05,0) [0|3212.75] "V" Vector__XXX
 SG_ SwitchedIgntV : 0|16@1+ (0.05,0) [0|3212.75] "V" Vector__XXX

BO_ 2565993726 MG4ILADC: 8 Vector__XXX
 SG_ CurMin : 48|12@1+ (0.0625,-125) [-125|125.9375] "%" Vector__XXX
 SG_ CurMax : 36|12@1+ (0.0625,-125) [-125|125.9375] "%" Vector__XXX
 SG_ VMin : 24|12@1+ (0.0625,-125) [-125|125.9375] "%" Vector__XXX
 SG_ VMax : 12|12@1+ (0.0625,-125) [-125|125.9375] "%" Vector__XXX
 SG_ Counter : 8|4@1+ (1,0) [0|15] "" Vector__XXX
 SG_ CRC : 0|8@1+ (1,0) [0|255] "" Vector__XXX

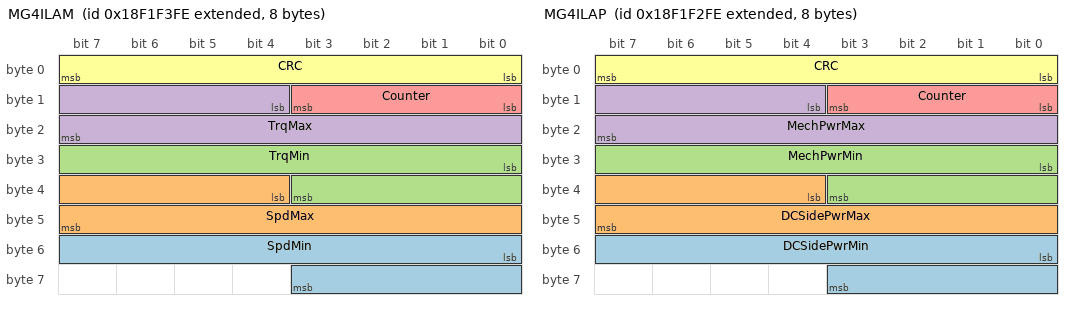
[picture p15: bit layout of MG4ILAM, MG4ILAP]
BO_ 2565993470 MG4ILAM: 8 Vector__XXX
 SG_ SpdMin : 48|12@1+ (0.0625,-125) [-125|125.9375] "%" Vector__XXX
 SG_ SpdMax : 36|12@1+ (0.0625,-125) [-125|125.9375] "%" Vector__XXX
 SG_ TrqMin : 24|12@1+ (0.0625,-125) [-125|125.9375] "%" Vector__XXX
 SG_ TrqMax : 12|12@1+ (0.0625,-125) [-125|125.9375] "%" Vector__XXX
 SG_ Counter : 8|4@1+ (1,0) [0|15] "" Vector__XXX
 SG_ CRC : 0|8@1+ (1,0) [0|255] "" Vector__XXX

BO_ 2565993214 MG4ILAP: 8 Vector__XXX
 SG_ DCSidePwrMin : 48|12@1+ (0.0625,-125) [-125|125.9375] "%" Vector__XXX
 SG_ DCSidePwrMax : 36|12@1+ (0.0625,-125) [-125|125.9375] "%" Vector__XXX
 SG_ MechPwrMin : 24|12@1+ (0.0625,-125) [-125|125.9375] "%" Vector__XXX
 SG_ MechPwrMax : 12|12@1+ (0.0625,-125) [-125|125.9375] "%" Vector__XXX
 SG_ Counter : 8|4@1+ (1,0) [0|15] "" Vector__XXX
 SG_ CRC : 0|8@1+ (1,0) [0|255] "" Vector__XXX

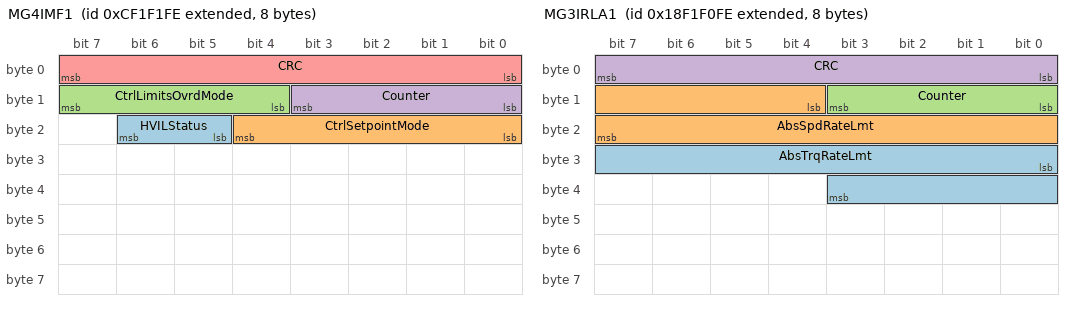
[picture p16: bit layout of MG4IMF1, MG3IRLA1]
BO_ 2364666366 MG4IMF1: 8 Vector__XXX
 SG_ HVILStatus : 21|2@1+ (1,0) [0|3] "" Vector__XXX
 SG_ CtrlSetpointMode : 16|5@1+ (1,0) [0|31] "" Vector__XXX
 SG_ CtrlLimitsOvrdMode : 12|4@1+ (1,0) [0|15] "" Vector__XXX
 SG_ Counter : 8|4@1+ (1,0) [0|15] "" Vector__XXX
 SG_ CRC : 0|8@1+ (1,0) [0|255] "" Vector__XXX

BO_ 2565992702 MG3IRLA1: 8 Vector__XXX
 SG_ AbsTrqRateLmt : 24|12@1+ (2,0) [0|8030] "%/s" Vector__XXX
 SG_ AbsSpdRateLmt : 12|12@1+ (0.25,0) [0|1003.75] "%/s" Vector__XXX
 SG_ Counter : 8|4@1+ (1,0) [0|15] "" Vector__XXX
 SG_ CRC : 0|8@1+ (1,0) [0|255] "" Vector__XXX

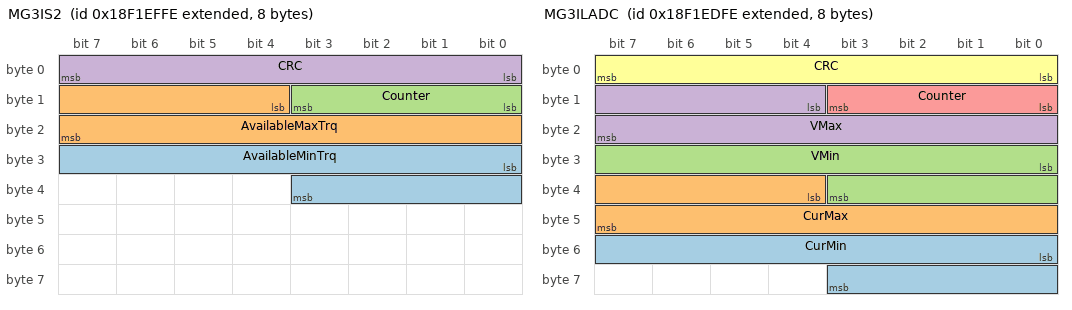
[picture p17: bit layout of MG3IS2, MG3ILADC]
BO_ 2565992446 MG3IS2: 8 Vector__XXX
 SG_ AvailableMinTrq : 24|12@1+ (0.0625,-125) [-125|125.9375] "%" Vector__XXX
 SG_ AvailableMaxTrq : 12|12@1+ (0.0625,-125) [-125|125.9375] "%" Vector__XXX
 SG_ Counter : 8|4@1+ (1,0) [0|15] "" Vector__XXX
 SG_ CRC : 0|8@1+ (1,0) [0|255] "" Vector__XXX

BO_ 2565992190 MG3ILV: 8 Vector__XXX
 SG_ UnswitchedSLIV : 16|16@1+ (0.05,0) [0|3212.75] "V" Vector__XXX
 SG_ SwitchedIgntV : 0|16@1+ (0.05,0) [0|3212.75] "V" Vector__XXX

BO_ 2565991934 MG3ILADC: 8 Vector__XXX
 SG_ CurMin : 48|12@1+ (0.0625,-125) [-125|125.9375] "%" Vector__XXX
 SG_ CurMax : 36|12@1+ (0.0625,-125) [-125|125.9375] "%" Vector__XXX
 SG_ VMin : 24|12@1+ (0.0625,-125) [-125|125.9375] "%" Vector__XXX
 SG_ VMax : 12|12@1+ (0.0625,-125) [-125|125.9375] "%" Vector__XXX
 SG_ Counter : 8|4@1+ (1,0) [0|15] "" Vector__XXX
 SG_ CRC : 0|8@1+ (1,0) [0|255] "" Vector__XXX

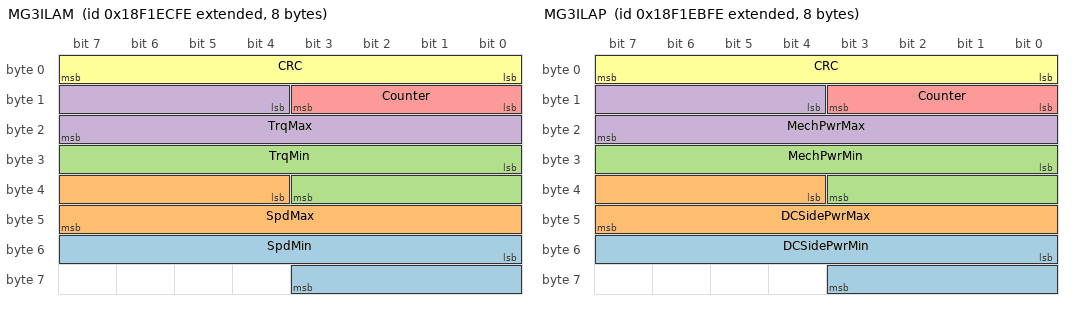
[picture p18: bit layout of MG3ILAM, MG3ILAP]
BO_ 2565991678 MG3ILAM: 8 Vector__XXX
 SG_ SpdMin : 48|12@1+ (0.0625,-125) [-125|125.9375] "%" Vector__XXX
 SG_ SpdMax : 36|12@1+ (0.0625,-125) [-125|125.9375] "%" Vector__XXX
 SG_ TrqMin : 24|12@1+ (0.0625,-125) [-125|125.9375] "%" Vector__XXX
 SG_ TrqMax : 12|12@1+ (0.0625,-125) [-125|125.9375] "%" Vector__XXX
 SG_ Counter : 8|4@1+ (1,0) [0|15] "" Vector__XXX
 SG_ CRC : 0|8@1+ (1,0) [0|255] "" Vector__XXX

BO_ 2565991422 MG3ILAP: 8 Vector__XXX
 SG_ DCSidePwrMin : 48|12@1+ (0.0625,-125) [-125|125.9375] "%" Vector__XXX
 SG_ DCSidePwrMax : 36|12@1+ (0.0625,-125) [-125|125.9375] "%" Vector__XXX
 SG_ MechPwrMin : 24|12@1+ (0.0625,-125) [-125|125.9375] "%" Vector__XXX
 SG_ MechPwrMax : 12|12@1+ (0.0625,-125) [-125|125.9375] "%" Vector__XXX
 SG_ Counter : 8|4@1+ (1,0) [0|15] "" Vector__XXX
 SG_ CRC : 0|8@1+ (1,0) [0|255] "" Vector__XXX

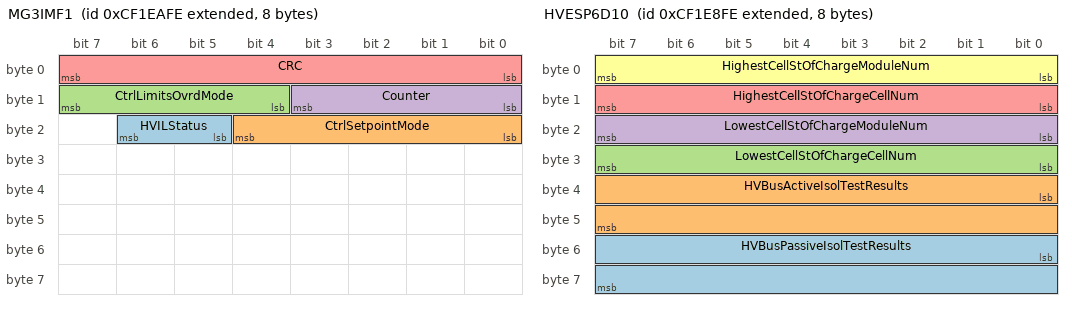
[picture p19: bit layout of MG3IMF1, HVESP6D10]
BO_ 2364664574 MG3IMF1: 8 Vector__XXX
 SG_ HVILStatus : 21|2@1+ (1,0) [0|3] "" Vector__XXX
 SG_ CtrlSetpointMode : 16|5@1+ (1,0) [0|31] "" Vector__XXX
 SG_ CtrlLimitsOvrdMode : 12|4@1+ (1,0) [0|15] "" Vector__XXX
 SG_ Counter : 8|4@1+ (1,0) [0|15] "" Vector__XXX
 SG_ CRC : 0|8@1+ (1,0) [0|255] "" Vector__XXX

BO_ 2364664318 HVESP6D11: 8 Vector__XXX
 SG_ ActualChargeRate : 32|16@1+ (0.05,0) [0|3212.75] "kW" Vector__XXX
 SG_ LvlNegToChassisGroundV : 16|16@1+ (0.05,0) [0|3212.75] "V" Vector__XXX
 SG_ BusVNegToChassisGroundV : 0|16@1+ (0.05,0) [0|3212.75] "V" Vector__XXX

BO_ 2364664062 HVESP6D10: 8 Vector__XXX
 SG_ HVBusPassiveIsolTestResults : 48|16@1+ (0.1,0) [0|6425.5] "Ohm/V" Vector__XXX
 SG_ HVBusActiveIsolTestResults : 32|16@1+ (0.1,0) [0|6425.5] "Ohm/V" Vector__XXX
 SG_ LowestCellStOfChargeCellNum : 24|8@1+ (1,0) [0|250] "" Vector__XXX
 SG_ LowestCellStOfChargeModuleNum : 16|8@1+ (1,0) [0|250] "" Vector__XXX
 SG_ HighestCellStOfChargeCellNum : 8|8@1+ (1,0) [0|250] "" Vector__XXX
 SG_ HighestCellStOfChargeModuleNum : 0|8@1+ (1,0) [0|250] "" Vector__XXX

CM_ BO_ 2566588926 "NOx Tracking Valid NOx Lifetime Engine Output Energy Bins 
Cumulative Engine Output Energy sorted into bins over the lifetime of the vehicle while the NOx sensors are Valid";
CM_ SG_ 2566588926 Bin17 "Accumulated Engine output energy while all NOx sensors are active over the lifetime of the vehicle for Bin 17 [Note Bin 17 is the MIL On Bin]";
CM_ SG_ 2566588926 Bin16 "Accumulated Engine output energy while all NOx sensors are active over the lifetime of the vehicle for Bin 16 [Note Bin 16 is the Regen Bin]";
CM_ SG_ 2566588926 Bin15 "Accumulated Engine output energy while all NOx sensors are active over the lifetime of the vehicle for Bin 15 [Note Bin 15 is the NTE Bin]";
CM_ SG_ 2566588926 Bin14 "Accumulated Engine output energy while all NOx sensors are active over the lifetime of the vehicle for Bin 14";
CM_ SG_ 2566588926 Bin13 "Accumulated Engine output energy while all NOx sensors are active over the lifetime of the vehicle for Bin 13";
CM_ SG_ 2566588926 Bin12 "Accumulated Engine output energy while all NOx sensors are active over the lifetime of the vehicle for Bin 12";
CM_ SG_ 2566588926 Bin11 "Accumulated Engine output energy while all NOx sensors are active over the lifetime of the vehicle for Bin 11";
CM_ SG_ 2566588926 Bin10 "Accumulated Engine output energy while all NOx sensors are active over the lifetime of the vehicle for Bin 10";
CM_ SG_ 2566588926 Bin9 "Accumulated Engine output energy while all NOx sensors are active over the lifetime of the vehicle for Bin 9";
CM_ SG_ 2566588926 Bin8 "Accumulated Engine output energy while all NOx sensors are active over the lifetime of the vehicle for Bin 8.";
CM_ SG_ 2566588926 Bin7 "Accumulated Engine output energy while all NOx sensors are active over the lifetime of the vehicle for Bin 7.";
CM_ SG_ 2566588926 Bin6 "Accumulated Engine output energy while all NOx sensors are active over the lifetime of the vehicle for Bin 6.";
CM_ SG_ 2566588926 Bin5 "Accumulated Engine output energy while all NOx sensors are active over the lifetime of the vehicle for Bin 5.";
CM_ SG_ 2566588926 Bin4 "Accumulated Engine output energy while all NOx sensors are active over the lifetime of the vehicle for Bin 4.";
CM_ SG_ 2566588926 Bin3 "Accumulated Engine output energy while all NOx sensors are active over the lifetime of the vehicle for Bin 3.";
CM_ SG_ 2566588926 Bin2 "Accumulated Engine output energy while all NOx sensors are active over the lifetime of the vehicle for Bin 2 [Note Bin 2 is the 'idle' bin]";
CM_ SG_ 2566588926 Bin1 "Accumulated Engine output energy while all NOx sensors are active over the lifetime of the vehicle for Bin 1 [Note Bin 1 is the total of Bins 2-14]";
CM_ BO_ 2566588670 "NOx Tracking Valid NOx Lifetime Vehicle Distance Bins 
Cumulative Vehicle Distance sorted into bins over the lifetime of the vehicle while the NOx sensors are Valid";
CM_ SG_ 2566588670 Bin17 "Accumulated Vehicle distance while all NOx sensors are active over the lifetime of the vehicle for Bin 17 [Note Bin 17 is the MIL On Bin]";
CM_ SG_ 2566588670 Bin16 "Accumulated Vehicle distance while all NOx sensors are active over the lifetime of the vehicle for Bin 16 [Note Bin 16 is the Regen Bin]";
CM_ SG_ 2566588670 Bin15 "Accumulated Vehicle distance while all NOx sensors are active over the lifetime of the vehicle for Bin 15 [Note Bin 15 is the NTE Bin]";
CM_ SG_ 2566588670 Bin14 "Accumulated Vehicle distance while all NOx sensors are active over the lifetime of the vehicle for Bin 14";
CM_ SG_ 2566588670 Bin13 "Accumulated Vehicle distance while all NOx sensors are active over the lifetime of the vehicle for Bin 13";
CM_ SG_ 2566588670 Bin12 "Accumulated Vehicle distance while all NOx sensors are active over the lifetime of the vehicle for Bin 12";
CM_ SG_ 2566588670 Bin11 "Accumulated Vehicle distance while all NOx sensors are active over the lifetime of the vehicle for Bin 11";
CM_ SG_ 2566588670 Bin10 "Accumulated Vehicle distance while all NOx sensors are active over the lifetime of the vehicle for Bin 10";
CM_ SG_ 2566588670 Bin9 "Accumulated Vehicle distance while all NOx sensors are active over the lifetime of the vehicle for Bin 9";
CM_ SG_ 2566588670 Bin8 "Accumulated Vehicle distance while all NOx sensors are active over the lifetime of the vehicle for Bin 8.";
CM_ SG_ 2566588670 Bin7 "Accumulated Vehicle distance while all NOx sensors are active over the lifetime of the vehicle for Bin 7.";
CM_ SG_ 2566588670 Bin6 "Accumulated Vehicle distance while all NOx sensors are active over the lifetime of the vehicle for Bin 6.";
CM_ SG_ 2566588670 Bin5 "Accumulated Vehicle distance while all NOx sensors are active over the lifetime of the vehicle for Bin 5.";
CM_ SG_ 2566588670 Bin4 "Accumulated Vehicle distance while all NOx sensors are active over the lifetime of the vehicle for Bin 4.";
CM_ SG_ 2566588670 Bin3 "Accumulated Vehicle distance while all NOx sensors are active over the lifetime of the vehicle for Bin 3.";
CM_ SG_ 2566588670 Bin2 "Accumulated Vehicle distance while all NOx sensors are active over the lifetime of the vehicle for Bin 2 [Note Bin 2 is the 'idle' bin]";
CM_ SG_ 2566588670 Bin1 "Accumulated Vehicle distance while all NOx sensors are active over the lifetime of the vehicle for Bin 1 [Note Bin 1 is the total of Bins 2-14]";
CM_ BO_ 2566588414 "NOx Tracking Valid NOx Lifetime Engine Run Time Bins 
Cumulative Engine Hours sorted into bins over the lifetime of the vehicle while the NOx sensors are Valid";
CM_ SG_ 2566588414 Bin17 "Accumulated Engine run time while all NOx sensors are active over the lifetime of the vehicle for Bin 17 [Note Bin 17 is the MIL On Bin]";
CM_ SG_ 2566588414 Bin16 "Accumulated Engine run time while all NOx sensors are active over the lifetime of the vehicle for Bin 16 [Note Bin 16 is the Regen Bin]";
CM_ SG_ 2566588414 Bin15 "Accumulated Engine run time while all NOx sensors are active over the lifetime of the vehicle for Bin 15 [Note Bin 15 is the NTE Bin]";
CM_ SG_ 2566588414 Bin14 "Accumulated Engine run time while all NOx sensors are active over the lifetime of the vehicle for Bin 14";
CM_ SG_ 2566588414 Bin13 "Accumulated Engine run time while all NOx sensors are active over the lifetime of the vehicle for Bin 13";
CM_ SG_ 2566588414 Bin12 "Accumulated Engine run time while all NOx sensors are active over the lifetime of the vehicle for Bin 12";
CM_ SG_ 2566588414 Bin11 "Accumulated Engine run time while all NOx sensors are active over the lifetime of the vehicle for Bin 11";
CM_ SG_ 2566588414 Bin10 "Accumulated Engine run time while all NOx sensors are active over the lifetime of the vehicle for Bin 10";
CM_ SG_ 2566588414 Bin9 "Accumulated Engine run time while all NOx sensors are active over the lifetime of the vehicle for Bin 9";
CM_ SG_ 2566588414 Bin8 "Accumulated Engine run time while all NOx sensors are active over the lifetime of the vehicle for Bin 8.";
CM_ SG_ 2566588414 Bin7 "Accumulated Engine run time while all NOx sensors are active over the lifetime of the vehicle for Bin 7.";
CM_ SG_ 2566588414 Bin6 "Accumulated Engine run time while all NOx sensors are active over the lifetime of the vehicle for Bin 6.";
CM_ SG_ 2566588414 Bin5 "Accumulated Engine run time while all NOx sensors are active over the lifetime of the vehicle for Bin 5.";
CM_ SG_ 2566588414 Bin4 "Accumulated Engine run time while all NOx sensors are active over the lifetime of the vehicle for Bin 4.";
CM_ SG_ 2566588414 Bin3 "Accumulated Engine run time while all NOx sensors are active over the lifetime of the vehicle for Bin 3.";
CM_ SG_ 2566588414 Bin2 "Accumulated Engine run time while all NOx sensors are active over the lifetime of the vehicle for Bin 2 [Note Bin 2 is the 'idle' bin]";
CM_ SG_ 2566588414 Bin1 "Accumulated Engine run time while all NOx sensors are active over the lifetime of the vehicle for Bin 1 [Note Bin 1 is the total of Bins 2-14]";
CM_ BO_ 2566588158 "NOx Tracking Valid NOx Lifetime Fuel Consumption Bins 
Cumulative Fuel Consumption sorted into bins over the lifetime of the vehicle while the NOx sensors are Valid";
CM_ SG_ 2566588158 Bin17 "Accumulated Fuel consumption while all NOx sensors are active over the lifetime of the vehicle for Bin 17 [Note Bin 17 is the MIL On Bin]";
CM_ SG_ 2566588158 Bin16 "Accumulated Fuel consumption while all NOx sensors are active over the lifetime of the vehicle for Bin 16 [Note Bin 16 is the Regen Bin]";
CM_ SG_ 2566588158 Bin15 "Accumulated Fuel consumption while all NOx sensors are active over the lifetime of the vehicle for Bin 15 [Note Bin 15 is the NTE Bin]";
CM_ SG_ 2566588158 Bin14 "Accumulated Fuel consumption while all NOx sensors are active over the lifetime of the vehicle for Bin 14";
CM_ SG_ 2566588158 Bin13 "Accumulated Fuel consumption while all NOx sensors are active over the lifetime of the vehicle for Bin 13";
CM_ SG_ 2566588158 Bin12 "Accumulated Fuel consumption while all NOx sensors are active over the lifetime of the vehicle for Bin 12";
CM_ SG_ 2566588158 Bin11 "Accumulated Fuel consumption while all NOx sensors are active over the lifetime of the vehicle for Bin 11";
CM_ SG_ 2566588158 Bin10 "Accumulated Fuel consumption while all NOx sensors are active over the lifetime of the vehicle for Bin 10";
CM_ SG_ 2566588158 Bin9 "Accumulated Fuel consumption while all NOx sensors are active over the lifetime of the vehicle for Bin 9";
CM_ SG_ 2566588158 Bin8 "Accumulated Fuel consumption while all NOx sensors are active over the lifetime of the vehicle for Bin 8.";
CM_ SG_ 2566588158 Bin7 "Accumulated Fuel consumption while all NOx sensors are active over the lifetime of the vehicle for Bin 7.";
CM_ SG_ 2566588158 Bin6 "Accumulated Fuel consumption while all NOx sensors are active over the lifetime of the vehicle for Bin 6.";
CM_ SG_ 2566588158 Bin5 "Accumulated Fuel consumption while all NOx sensors are active over the lifetime of the vehicle for Bin 5.";
CM_ SG_ 2566588158 Bin4 "Accumulated Fuel consumption while all NOx sensors are active over the lifetime of the vehicle for Bin 4.";
CM_ SG_ 2566588158 Bin3 "Accumulated Fuel consumption while all NOx sensors are active over the lifetime of the vehicle for Bin 3.";
CM_ SG_ 2566588158 Bin2 "Accumulated Fuel consumption while all NOx sensors are active over the lifetime of the vehicle for Bin 2 [Note Bin 2 is the 'idle' bin]";
CM_ SG_ 2566588158 Bin1 "Accumulated Fuel consumption while all NOx sensors are active over the lifetime of the vehicle for Bin 1 [Note Bin 1 is the total of Bins 2-14]";
CM_ BO_ 2566587902 "NOx Tracking Engine Activity Lifetime Engine Output Energy Bins 
Cumulative Engine Output Energy sorted into bins over the lifetime of the vehicle independent of NOx sensor status";
CM_ SG_ 2566587902 Bin17 "Accumulated Engine output energy regardless of NOx sensor status over the lifetime of the vehicle for Bin 17 [Note Bin 17 is the MIL On Bin].";
CM_ SG_ 2566587902 Bin16 "Accumulated Engine output energy regardless of NOx sensor status over the lifetime of the vehicle for Bin 16 [Note Bin 16 is the Regen Bin]";
CM_ SG_ 2566587902 Bin15 "Accumulated Engine output energy regardless of NOx sensor status over the lifetime of the vehicle for Bin 15 [Note Bin 15 is the NTE Bin]";
CM_ SG_ 2566587902 Bin14 "Accumulated Engine output energy regardless of NOx sensor status over the lifetime of the vehicle for Bin 14";
CM_ SG_ 2566587902 Bin13 "Accumulated Engine output energy regardless of NOx sensor status over the lifetime of the vehicle for Bin 13";
CM_ SG_ 2566587902 Bin12 "Accumulated Engine output energy regardless of NOx sensor status over the lifetime of the vehicle for Bin 12";
CM_ SG_ 2566587902 Bin11 "Accumulated Engine output energy regardless of NOx sensor status over the lifetime of the vehicle for Bin 11";
CM_ SG_ 2566587902 Bin10 "Accumulated Engine output energy regardless of NOx sensor status over the lifetime of the vehicle for Bin 10";
CM_ SG_ 2566587902 Bin9 "Accumulated Engine output energy regardless of NOx sensor status over the lifetime of the vehicle for Bin 9";
CM_ SG_ 2566587902 Bin8 "Accumulated Engine output energy regardless of NOx sensor status over the lifetime of the vehicle for Bin 8.";
CM_ SG_ 2566587902 Bin7 "Accumulated Engine output energy regardless of NOx sensor status over the lifetime of the vehicle for Bin 7.";
CM_ SG_ 2566587902 Bin6 "Accumulated Engine output energy regardless of NOx sensor status over the lifetime of the vehicle for Bin 6.";
CM_ SG_ 2566587902 Bin5 "Accumulated Engine output energy regardless of NOx sensor status over the lifetime of the vehicle for Bin 5.";
CM_ SG_ 2566587902 Bin4 "Accumulated Engine output energy regardless of NOx sensor status over the lifetime of the vehicle for Bin 4.";
CM_ SG_ 2566587902 Bin3 "Accumulated Engine output energy regardless of NOx sensor status over the lifetime of the vehicle for Bin 3.";
CM_ SG_ 2566587902 Bin2 "Accumulated Engine output energy regardless of NOx sensor status over the lifetime of the vehicle for Bin 2 [Note Bin 2 is the 'idle' bin]";
CM_ SG_ 2566587902 Bin1 "Accumulated Engine output energy regardless of NOx sensor status over the lifetime of the vehicle for Bin 1 [Note Bin 1 is the total of bins 2-14]";
CM_ BO_ 2566587646 "NOx Tracking Engine Activity Lifetime Vehicle Distance Bins 
Cumulative Vehicle Distance sorted into bins over the lifetime of the vehicle independent of NOx sensor status";
CM_ SG_ 2566587646 Bin17 "Accumulated Vehicle distance regardless of NOx sensor status over the lifetime of the vehicle for Bin 17 [Note Bin 17 is the MIL On Bin].";
CM_ SG_ 2566587646 Bin16 "Accumulated Vehicle distance regardless of NOx sensor status over the lifetime of the vehicle for Bin 16 [Note Bin 16 is the Regen Bin]";
CM_ SG_ 2566587646 Bin15 "Accumulated Vehicle distance regardless of NOx sensor status over the lifetime of the vehicle for Bin 15 [Note Bin 15 is the NTE Bin]";
CM_ SG_ 2566587646 Bin14 "Accumulated Vehicle distance regardless of NOx sensor status over the lifetime of the vehicle for Bin 14";
CM_ SG_ 2566587646 Bin13 "Accumulated Vehicle distance regardless of NOx sensor status over the lifetime of the vehicle for Bin 13";
CM_ SG_ 2566587646 Bin12 "Accumulated Vehicle distance regardless of NOx sensor status over the lifetime of the vehicle for Bin 12";
CM_ SG_ 2566587646 Bin11 "Accumulated Vehicle distance regardless of NOx sensor status over the lifetime of the vehicle for Bin 11";
CM_ SG_ 2566587646 Bin10 "Accumulated Vehicle distance regardless of NOx sensor status over the lifetime of the vehicle for Bin 10";
CM_ SG_ 2566587646 Bin9 "Accumulated Vehicle distance regardless of NOx sensor status over the lifetime of the vehicle for Bin 9";
CM_ SG_ 2566587646 Bin8 "Accumulated Vehicle distance regardless of NOx sensor status over the lifetime of the vehicle for Bin 8.";
CM_ SG_ 2566587646 Bin7 "Accumulated Vehicle distance regardless of NOx sensor status over the lifetime of the vehicle for Bin 7.";
CM_ SG_ 2566587646 Bin6 "Accumulated Vehicle distance regardless of NOx sensor status over the lifetime of the vehicle for Bin 6.";
CM_ SG_ 2566587646 Bin5 "Accumulated Vehicle distance regardless of NOx sensor status over the lifetime of the vehicle for Bin 5.";
CM_ SG_ 2566587646 Bin4 "Accumulated Vehicle distance regardless of NOx sensor status over the lifetime of the vehicle for Bin 4.";
CM_ SG_ 2566587646 Bin3 "Accumulated Vehicle distance regardless of NOx sensor status over the lifetime of the vehicle for Bin 3.";
CM_ SG_ 2566587646 Bin2 "Accumulated Vehicle distance regardless of NOx sensor status over the lifetime of the vehicle for Bin 2 [Note Bin 2 is the 'idle' bin]";
CM_ SG_ 2566587646 Bin1 "Accumulated Vehicle distance regardless of NOx sensor status over the lifetime of the vehicle for Bin 1 [Note Bin 1 is the total of Bins 2-14]";
CM_ BO_ 2566587390 "NOx Tracking Engine Activity Lifetime Engine Run Time Bins 
Cumulative Engine Hours sorted into bins over the lifetime of the vehicle independent of NOx sensor status";
CM_ SG_ 2566587390 Bin17 "Accumulated Engine run time regardless of NOx sensor status over the lifetime of the vehicle for Bin 17 [Note Bin 17 is the MIL On Bin].";
CM_ SG_ 2566587390 Bin16 "Accumulated Engine run time regardless of NOx sensor status over the lifetime of the vehicle for Bin 16 [Note Bin 16 is the Regen Bin]";
CM_ SG_ 2566587390 Bin15 "Accumulated Engine run time regardless of NOx sensor status over the lifetime of the vehicle for Bin 15 [Note Bin 15 is the NTE Bin]";
CM_ SG_ 2566587390 Bin14 "Accumulated Engine run time regardless of NOx sensor status over the lifetime of the vehicle for Bin 14";
CM_ SG_ 2566587390 Bin13 "Accumulated Engine run time regardless of NOx sensor status over the lifetime of the vehicle for Bin 13";
CM_ SG_ 2566587390 Bin12 "Accumulated Engine run time regardless of NOx sensor status over the lifetime of the vehicle for Bin 12";
CM_ SG_ 2566587390 Bin11 "Accumulated Engine run time regardless of NOx sensor status over the lifetime of the vehicle for Bin 11";
CM_ SG_ 2566587390 Bin10 "Accumulated Engine run time regardless of NOx sensor status over the lifetime of the vehicle for Bin 10";
CM_ SG_ 2566587390 Bin9 "Accumulated Engine run time regardless of NOx sensor status over the lifetime of the vehicle for Bin 9";
CM_ SG_ 2566587390 Bin8 "Accumulated Engine run time regardless of NOx sensor status over the lifetime of the vehicle for Bin 8.";
CM_ SG_ 2566587390 Bin7 "Accumulated Engine run time regardless of NOx sensor status over the lifetime of the vehicle for Bin 7.";
CM_ SG_ 2566587390 Bin6 "Accumulated Engine run time regardless of NOx sensor status over the lifetime of the vehicle for Bin 6.";
CM_ SG_ 2566587390 Bin5 "Accumulated Engine run time regardless of NOx sensor status over the lifetime of the vehicle for Bin 5.";
CM_ SG_ 2566587390 Bin4 "Accumulated Engine run time regardless of NOx sensor status over the lifetime of the vehicle for Bin 4.";
CM_ SG_ 2566587390 Bin3 "Accumulated Engine run time regardless of NOx sensor status over the lifetime of the vehicle for Bin 3.";
CM_ SG_ 2566587390 Bin2 "Accumulated Engine run time regardless of NOx sensor status over the lifetime of the vehicle for Bin 2 [Note Bin 2 is the 'idle' bin]";
CM_ SG_ 2566587390 Bin1 "Accumulated Engine run time regardless of NOx sensor status over the lifetime of the vehicle for Bin 1 [Note Bin 1 is the total of Bins 2-14]";
CM_ BO_ 2566587134 "NOx Tracking Engine Activity Lifetime Fuel Consumption Bins 
Cumulative Fuel Consumption sorted into bins over the lifetime of the vehicle independent of NOx sensor status";
CM_ SG_ 2566587134 Bin17 "Accumulated Fuel consumption regardless of NOx sensor status over the lifetime of the vehicle for Bin 17 [Note Bin 17 is the MIL On  bin].";
CM_ SG_ 2566587134 Bin16 "Accumulated Fuel consumption regardless of NOx sensor status over the lifetime of the vehicle for Bin 16 [Note Bin 16 is the Regen Bin]";
CM_ SG_ 2566587134 Bin15 "Accumulated Fuel consumption regardless of NOx sensor status over the lifetime of the vehicle for Bin 15 [Note Bin 15 is the NTE Bin]";
CM_ SG_ 2566587134 Bin14 "Accumulated Fuel consumption regardless of NOx sensor status over the lifetime of the vehicle for Bin 14";
CM_ SG_ 2566587134 Bin13 "Accumulated Fuel consumption regardless of NOx sensor status over the lifetime of the vehicle for Bin 13";
CM_ SG_ 2566587134 Bin12 "Accumulated Fuel consumption regardless of NOx sensor status over the lifetime of the vehicle for Bin 12";
CM_ SG_ 2566587134 Bin11 "Accumulated Fuel consumption regardless of NOx sensor status over the lifetime of the vehicle for Bin 11";
CM_ SG_ 2566587134 Bin10 "Accumulated Fuel consumption regardless of NOx sensor status over the lifetime of the vehicle for Bin 10";
CM_ SG_ 2566587134 Bin9 "Accumulated Fuel consumption regardless of NOx sensor status over the lifetime of the vehicle for Bin 9";
CM_ SG_ 2566587134 Bin8 "Accumulated Fuel consumption regardless of NOx sensor status over the lifetime of the vehicle for Bin 8.";
CM_ SG_ 2566587134 Bin7 "Accumulated Fuel consumption regardless of NOx sensor status over the lifetime of the vehicle for Bin 7.";
CM_ SG_ 2566587134 Bin6 "Accumulated Fuel consumption regardless of NOx sensor status over the lifetime of the vehicle for Bin 6.";
CM_ SG_ 2566587134 Bin5 "Accumulated Fuel consumption regardless of NOx sensor status over the lifetime of the vehicle for Bin 5.";
CM_ SG_ 2566587134 Bin4 "Accumulated Fuel consumption regardless of NOx sensor status over the lifetime of the vehicle for Bin 4.";
CM_ SG_ 2566587134 Bin3 "Accumulated Fuel consumption regardless of NOx sensor status over the lifetime of the vehicle for Bin 3.";
CM_ SG_ 2566587134 Bin2 "Accumulated Fuel consumption regardless of NOx sensor status over the lifetime of the vehicle for Bin 2 [Note Bin 2 is the 'idle' bin]";
CM_ SG_ 2566587134 Bin1 "Accumulated Fuel consumption regardless of NOx sensor status over the lifetime of the vehicle for Bin 1 [Note Bin 1 is the total of Bins 2-14]";
CM_ BO_ 2566586878 "Green House Gas Lifetime Active Technology Tracking 
Green House Gas [GHG] Tracking Lifetime utilization time and distance by indexed technology catagories.";
CM_ SG_ 2566586878 GHGTrackingActiveTechVehDist "Green house gas active technology utilization in kilometers for the preceding active technology index";
CM_ SG_ 2566586878 GHGTrackingActiveTechTime "Green house gas active technology utilization in hours for the preceding active technology index";
CM_ SG_ 2566586878 GHGTrackingActiveTechIndex "Green house gas active technology index number for the lifetime hours and distance in the next two SPs of this message.";
CM_ BO_ 2566586622 "Green House Gas Active 100 Hour Active Technology Tracking 
Green House Gas [GHG] Tracking Active 100 hour utilization time and distance by indexed technology catagories.";
CM_ SG_ 2566586622 GHGTrackingActiveTechVehDist "Green house gas active 100 hour active technology utilization in kilometers for the preceding active technology index";
CM_ SG_ 2566586622 GHGTrackingActiveTechTime "Green house gas active 100 hour active technology utilization in hours for the preceding active technology index";
CM_ SG_ 2566586622 GHGTrackingActiveTechIndex "Green house gas active 100 hour technology index number for the hours and distance in the next two SPs of this message.";
CM_ BO_ 2566586366 "Green House Gas Stored 100 Hour Active Technology Tracking 
Green House Gas [GHG] Tracking Stored 100 hour utilization time and distance by indexed technology catagories.";
CM_ SG_ 2566586366 GHGTrackingActiveTechVehDist "Green house gas stored 100 hour active technology utilization in kilometers for the preceding active technology index";
CM_ SG_ 2566586366 GHGTrackingActiveTechTime "Green house gas stored 100 hour active technology utilization in hours for the preceding active technology index";
CM_ SG_ 2566586366 GHGTrackingActiveTechIndex "Green house gas stored 100 hour technology index number for the hours and distance in the next two SPs of this message.";
CM_ BO_ 2566586110 "GHG Tracking Active 100 Hour Array Data
Green House Gas [GHG] Tracking cumulative data for the current 100 hour period";
CM_ SG_ 2566586110 StopStartTechRunTime "Accumulated time where the stop start system is commanding the engine off over the current 100 hour period for GHG Tracking.";
CM_ SG_ 2566586110 AutoEngShutdownTechActCount "Accumulated activation counts of the automatic engine [idle] shutdown (AES) system over the current 100 hour period for GHG Tracking.";
CM_ SG_ 2566586110 EngPwrTakeOffFuelConsumption "Accumulated fuel consumption under power take off [PTO] governor control over the current 100 hour period for GHG Tracking.";
CM_ SG_ 2566586110 EngPwrTakeOffRunTime "Accumulated engine runtime under power take off [PTO] governor control over the current 100 hour period for GHG Tracking.";
CM_ SG_ 2566586110 EngIdleFuelConsumption "Accumulated fuel consumption under idle conditions (v <= 1.6 km/h) over the current 100 hour period for GHG Tracking.";
CM_ SG_ 2566586110 IdleRunTime "Accumulated engine run time under idle conditions (v <= 1.6 km/h) over the current 100 hour period for GHG Tracking.";
CM_ SG_ 2566586110 UrbanSpdRunTime "Accumulated time at urban vehicle speeds (1.6 km/h < v <= 60 km/h) over the current 100 hour period for GHG Tracking.";
CM_ SG_ 2566586110 PosKineticEnergyNumerator "Accumulated positive kinetic energy numerator (as delta-V-squared) over the current 100 hour period for GHG Tracking.  The PKE denominator is GHG Tracking Active 100 Hour Vehicle Distance";
CM_ SG_ 2566586110 EngOutEnergy "Accumulated engine output energy over the current 100 hour period for GHG Tracking.";
CM_ SG_ 2566586110 EngFuelConsumption "Accumulated engine fuel consumption over the current 100 hour period for GHG Tracking.";
CM_ SG_ 2566586110 VehFuelConsumption "Accumulated vehicle fuel consumption over the current 100 hour period for GHG Tracking.";
CM_ SG_ 2566586110 VehDist "Accumulated vehicle distance over the current 100 hour period for GHG Tracking.";
CM_ SG_ 2566586110 EngRunTime "Accumulated engine run time over the current 100 hour period for GHG Tracking.";
CM_ BO_ 2566585854 "GHG Tracking Stored 100 Hour Array Data
Green House Gas [GHG] Tracking cumulative data for the prior 100 hour period";
CM_ SG_ 2566585854 StopStartTechRunTime "Accumulated time where the stop start system is commanding the engine off over the prior 100 hour period for GHG Tracking.";
CM_ SG_ 2566585854 AutoEngShutdownTechActCount "Accumulated activation counts of the automatic engine [idle] shutdown (AES) system over the prior 100 hour period for GHG Tracking.";
CM_ SG_ 2566585854 EngPwrTakeOffFuelConsumption "Accumulated fuel consumption under power take off [PTO] governor control over the prior 100 hour period for GHG Tracking.";
CM_ SG_ 2566585854 EngPwrTakeOffRunTime "Accumulated engine runtime under power take off [PTO] governor control over the prior 100 hour period for GHG Tracking.";
CM_ SG_ 2566585854 EngIdleFuelConsumption "Accumulated fuel consumption under idle conditions (v <= 1.6 km/h) over the prior 100 hour period for GHG Tracking.";
CM_ SG_ 2566585854 IdleRunTime "Accumulated engine run time under idle conditions (v <= 1.6 km/h) over the prior 100 hour period for GHG Tracking.";
CM_ SG_ 2566585854 UrbanSpdRunTime "Accumulated time at urban vehicle speeds (1.6 km/h < v <= 60 km/h) over the prior 100 hour period for GHG Tracking.";
CM_ SG_ 2566585854 PosKineticEnergyNumerator "Accumulated positive kinetic energy numerator (as delta-V-squared) over the prior 100 hour period for GHG Tracking.  The PKE denominator is GHG Tracking Stored 100 Hour Vehicle Distance.";
CM_ SG_ 2566585854 EngOutEnergy "Accumulated engine output energy over the prior 100 hour period for GHG Tracking.";
CM_ SG_ 2566585854 EngFuelConsumption "Accumulated engine fuel consumption over the prior 100 hour period for GHG Tracking.";
CM_ SG_ 2566585854 VehFuelConsumption "Accumulated vehicle fuel consumption over the prior 100 hour period for GHG Tracking.";
CM_ SG_ 2566585854 VehDist "Accumulated vehicle distance over the prior 100 hour period for GHG Tracking.";
CM_ SG_ 2566585854 EngRunTime "Accumulated engine run time over the prior 100 hour period for GHG Tracking.";
CM_ BO_ 2566585598 "GHG Tracking Lifetime Array Data
Green House Gas [GHG] Tracking cumulative data for the lifetime of the vehicle";
CM_ SG_ 2566585598 StopStartTechRunTime "Accumulated time where the stop start system is commanding the engine off over the lifetime of the vehicle for GHG Tracking.";
CM_ SG_ 2566585598 AutoEngShutdownTechActCount "Accumulated activation counts of the automatic engine [idle] shutdown (AES) system over the lifetime of the vehicle for GHG Tracking.  

[Ed note:  Change SLOT to SAEct07; PGN is correct]";
CM_ SG_ 2566585598 EngPwrTakeOffFuelConsumption "Accumulated fuel consumption under power take off [PTO] governor control over the lifetime of the vehicle for GHG Tracking.";
CM_ SG_ 2566585598 EngPwrTakeOffRunTime "Accumulated engine runtime under power take off [PTO] governor control over the lifetime of the vehicle for GHG Tracking.";
CM_ SG_ 2566585598 EngIdleFuelConsumption "Accumulated fuel consumption under idle conditions (v <= 1.6 km/h) over the lifetime of the vehicle for GHG Tracking.";
CM_ SG_ 2566585598 IdleRunTime "Accumulated engine run time under idle conditions (v <= 1.6 km/h) over the lifetime of the vehicle for GHG Tracking.";
CM_ SG_ 2566585598 UrbanSpdRunTime "Accumulated time at urban vehicle speeds (1.6 km/h < v <= 60 km/h) over the lifetime of the vehicle for GHG Tracking.";
CM_ SG_ 2566585598 PosKineticEnergyNumerator "Accumulated positive kinetic energy numerator (as delta-V-squared) over the lifetime of the vehicle for GHG Tracking.    The PKE Denominator is provided by GHG Tracking Lifetime Vehicle Distance";
CM_ SG_ 2566585598 EngOutEnergy "Accumulated engine output energy over the lifetime of the vehicle for GHG Tracking.";
CM_ SG_ 2566585598 EngFuelConsumption "Accumulated engine fuel consumption over the lifetime of the vehicle for GHG Tracking.";
CM_ SG_ 2566585598 VehFuelConsumption "Accumulated vehicle fuel consumption over the lifetime of the vehicle for GHG Tracking.";
CM_ SG_ 2566585598 VehDist "Accumulated vehicle distance over the lifetime of the vehicle for GHG Tracking.";
CM_ SG_ 2566585598 EngRunTime "Accumulated engine run time over the lifetime of the vehicle for GHG Tracking.";
CM_ BO_ 2566585342 "Evaporative System Pressure and Control
Evap Canister System Pressures and Purge Control Data";
CM_ SG_ 2566585342 EVAPSysPurgeVlvPos "Relative position of the EVAP System Purge Valve";
CM_ SG_ 2566585342 EVAPSysPurgeVlvCmd "Commanded relative position of the EVAP System Purge Valve";
CM_ SG_ 2566585342 EVAPSysVaporPress "Absolute pressure of the fuel vapor measured in the EVAP System.";
CM_ SG_ 2566585342 EVAPSysPurgePress "Absolute pressure of the purge element measured in the EVAP System.";
CM_ BO_ 2566585086 "Aftertreatment 1 SCR 1 NOx Mass and NH3 Storage
Aftertreatment 1 SCR 1 NOx Mass and NH3 Storage";
CM_ SG_ 2566585086 TargetNH3StorageLvl "The target NH3 storage level in the first SCR catalyst in aftertreatment 1.";
CM_ SG_ 2566585086 Modeled_ActualStorageLvl "The modeled or actual NH3 storage level in the first SCR catalyst in aftertreatment 1.";
CM_ SG_ 2566585086 TailpipeNOxMassFlow "The mass flow of the NOx in the engine exhaust stream after all NOx converting catalysts in aftertreatment 1.
For systems with a second, parallel flow SCR catalyst, SPN 12755 shall be used to provide the second tailpipe NOx mass flow, which shall ...";
CM_ SG_ 2566585086 EngExhNOxMassFlow "The mass flow of the NOx in the engine exhaust stream before the NOx converting catalyst in aftertreatment 1.
If there is only one sensor that provides the engine outlet NOx mass flow in a system with parallel flow SCR catalysts, it shall be ...";
CM_ BO_ 2566584830 "Aftertreatment 1 SCR 2 NOx Mass and NH3 Storage
Aftertreatment 1 SCR 2 NOx Mass and NH3 Storage";
CM_ SG_ 2566584830 TargetNH3StorageLvl "The target NH3 storage level in the second SCR catalyst in aftertreatment 1.";
CM_ SG_ 2566584830 ModeledNH3StorageLvl "The modeled or actual NH3 storage level in the second SCR catalyst in aftertreatment 1.";
CM_ SG_ 2566584830 OutNOxMassFlow "The mass flow of the NOx in the engine exhaust stream after the NOx converting catalyst in aftertreatment 1.
This SP shall be omitted for aftertreatment systems with exhaust flow through sequential SCR catalysts.  It shall be used for the outlet ...";
CM_ SG_ 2566584830 InletNOxMassFlow "The mass flow of the NOx in the engine exhaust stream before the second NOx converting catalyst in aftertreatment 1.
This SP provides the NOx mass flow for the outlet of the first SCR catalyst for systems with sequential SCR catalysts.  When ...";
CM_ BO_ 2566584318 "Aftertreatment 1 Historical Information 3
Contains information about the history of the aftertreatment 1 system";
CM_ SG_ 2566584318 TotalTimeSCRInletTempBelow200Cel "Total engine run time with exhaust temperature below 200 degrees Celsius as measured just upstream of the NOx converting catalyst.
Note: If an engine has more than one NOx converting catalyst, tracking shall be based on the temperature upstream of ...";
CM_ SG_ 2566584318 TotalEngRuntimeWithNoDEFDel "Total engine run time with no delivery of reductant (e.g., diesel exhaust fluid) used to control NOx emissions due to insufficient exhaust temperature.
Note: For dual SCR catalyst systems, time shall accumulate only when both catalysts are not ...";
CM_ SG_ 2566584318 EndingEngVehDist3 "The engine vehicle distance for the completion of instance three of the last 3 complete DPF regenerations.
Note: Engine vehicle distance data need not be presented in ascending order by starting engine vehicle distance.  The three instances may be ...";
CM_ SG_ 2566584318 StartingEngVehDist3 "The engine vehicle distance for the initiation of instance three of the last 3 complete DPF regenerations.
Note: Engine vehicle distance data need not be presented in ascending order by starting engine vehicle distance.  The three instances may be ...";
CM_ SG_ 2566584318 EndingEngVehDist2 "The engine vehicle distance for the completion of instance two of the last 3 complete DPF regenerations.
Note: Engine vehicle distance data need not be presented in ascending order by starting engine vehicle distance.  The three instances may be ...";
CM_ SG_ 2566584318 StartingEngVehDist2 "The engine vehicle distance for the initiation of instance two of the last 3 complete DPF regenerations.
Note: Engine vehicle distance data need not be presented in ascending order by starting engine vehicle distance.  The three instances may be ...";
CM_ SG_ 2566584318 EndingEngVehDist1 "The engine vehicle distance for the completion of instance one of the last 3 complete DPF regenerations.
Note: Engine vehicle distance data need not be presented in ascending order by starting engine vehicle distance.  The three instances may be ...";
CM_ SG_ 2566584318 StartingEngVehDist1 "The engine vehicle distance for the initiation of instance one of the last 3 complete DPF regenerations.
Note: Engine vehicle distance data need not be presented in ascending order by starting engine vehicle distance.  The three instances may be ...";
CM_ BO_ 2566584062 "Hybrid Charge Depleting or Increasing Operation Active 100 Hours
Cumulative distance traveled, fuel consumed, and energy dispositioned during the active <100 hour period. OBD requires hybrids that are plugin vehicles to support this message.";
CM_ SG_ 2566584062 GridEnergyIntoTheBat "Cumulative grid energy into the battery during recent operation (time < 100 hours). OBD requires hybrids that are plugin vehicles to support this parameter.";
CM_ SG_ 2566584062 GridEnergyChargeDepletingEngRun "Cumulative grid energy supplied by the battery pack in charge depleting operation with engine running during recent operation (time < 100 hours). OBD requires hybrids that are plugin vehicles to support this parameter.";
CM_ SG_ 2566584062 GridEnergyChargeDepletingEngOff "Cumulative grid energy supplied by the battery pack in charge depleting operation with engine off during recent operation (time < 100 hours). OBD requires hybrids that are plugin vehicles to support this parameter.";
CM_ SG_ 2566584062 FuelInDriverSelChargeIncOp "Cumulative fuel consumption during driver-selectable charge increasing operation during recent operation (time < 100 hours). OBD requires hybrids that are plugin vehicles to support this parameter.";
CM_ SG_ 2566584062 FuelInChargeDepletingOp "Cumulative fuel consumption during charge-depleting operation during recent operation (time < 100 hours). OBD requires hybrids that are plugin vehicles to support this parameter.";
CM_ SG_ 2566584062 DistInDriverSelChargeIncOp "Cumulative distance traveled while in driver-selectable charge increasing operation during recent operation (time < 100 hours). OBD requires hybrids that are plugin vehicles to support this parameter.";
CM_ SG_ 2566584062 DistInChargeDepletingEngRun "Cumulative distance traveled while in charge depleting operation with engine running during recent operation (time < 100 hours). OBD requires hybrids that are plugin vehicles to support this parameter.";
CM_ SG_ 2566584062 DistInChargeDepletingEngOff "Cumulative distance traveled while in charge depleting operation with engine off during recent operation (time < 100 hours). OBD requires hybrids that are plugin vehicles to support this parameter.";
CM_ BO_ 2566583806 "Hybrid Charge Depleting or Increasing Operation Stored 100 Hours
Cumulative distance traveled, fuel consumed, and energy dispositioned during the stored 100 hour period. OBD requires hybrids that are plugin vehicles to support this message.";
CM_ SG_ 2566583806 GridEnergyIntoTheBat "Most recent stored 100-hour cumulative grid energy into the Battery. OBD requires hybrids that are plugin vehicles to support this parameter.";
CM_ SG_ 2566583806 GridEnergyChargeDepletingEngRun "Most recent stored 100-hour cumulative grid energy consumed during charge depleting operation with engine running. OBD requires hybrids that are plugin vehicles to support this parameter.";
CM_ SG_ 2566583806 GridEnergyChargeDepletingEngOff "Most recent stored 100-hour cumulative grid energy consumed during charge depleting operation with engine off. OBD requires hybrids that are plugin vehicles to support this parameter.";
CM_ SG_ 2566583806 FuelInDriverSelChargeIncOp "Most recent stored 100-hour cumulative fuel consumed during charge-depleting operation. OBD requires hybrids that are plugin vehicles to support this parameter.";
CM_ SG_ 2566583806 FuelInChargeDepletingOp "Most recent stored 100-hour cumulative fuel consumed during charge-depleting operation. OBD requires hybrids that are plugin vehicles to support this parameter.";
CM_ SG_ 2566583806 DistInDriverSelChargeIncOp "Most recent stored 100-hour cumulative distance traveled while in driver-selectable charge increasing operation. OBD requires hybrids that are plugin vehicles to support this parameter.";
CM_ SG_ 2566583806 DistInChargeDepletingEngRun "Most recent stored 100-hour cumulative distance traveled while in charge depleting operation with engine running. OBD requires hybrids that are plugin vehicles to support this parameter.";
CM_ SG_ 2566583806 DistInChargeDepletingEngOff "Most recent stored 100-hour cumulative distance traveled while in charge depleting operation with engine off. OBD requires hybrids that are plugin vehicles to support this parameter.";
CM_ BO_ 2566583550 "Hybrid Charge Depleting or Increasing Operation Lifetime Hours
Cumulative distance traveled, fuel consumed, and energy dispositioned during the vehicle lifetime. OBD requires hybrids that are plugin vehicles to support this message.";
CM_ SG_ 2566583550 GridEnergyIntoTheBat "Total grid energy into the battery during the lifetime of the vehicle. OBD requires hybrids that are plugin vehicles to support this parameter.";
CM_ SG_ 2566583550 GridEnergyChargeDepletingEngRun "Total grid energy supplied by the battery pack in charge depleting operation with engine running during the lifetime of the vehicle. OBD requires hybrids that are plugin vehicles to support this parameter.";
CM_ SG_ 2566583550 GridEnergyChargeDepletingEngOff "Total grid energy supplied by the battery pack in charge depleting operation with engine off during the lifetime of the vehicle. OBD requires hybrids that are plugin vehicles to support this parameter.";
CM_ SG_ 2566583550 FuelInDriverSelChargeIncOp "Total fuel consumption during driver-selectable charge increasing operation during the lifetime of the vehicle. OBD requires hybrids that are plugin vehicles to support this parameter.";
CM_ SG_ 2566583550 FuelInChargeDepletingOp "Total fuel consumption during charge-depleting operation during the lifetime of the vehicle. OBD requires hybrids that are plugin vehicles to support this parameter.";
CM_ SG_ 2566583550 DistInDriverSelChargeIncOp "Total distance traveled while in driver-selectable charge increasing operation during the lifetime of the vehicle. OBD requires hybrids that are plugin vehicles to support this parameter.";
CM_ SG_ 2566583550 DistInChargeDepletingEngRun "Total distance traveled while in charge depleting operation with engine running during the lifetime of the vehicle. OBD requires hybrids that are plugin vehicles to support this parameter.";
CM_ SG_ 2566583550 DistInChargeDepletingEngOff "Total distance traveled while in charge depleting operation with engine off during the lifetime of the vehicle. OBD requires hybrids that are plugin vehicles to support this parameter.";
CM_ BO_ 2566583294 "PSA Times Active 100 Hours
Cumulative propulsion system active time during recent operation, active 100 hours (time < 100 hours). OBD requires all hybrids to support this message.";
CM_ SG_ 2566583294 UrbanPropulsionSysActiveTime "Cumulative urban  (1.6 km/h < v <= 60 km/h) propulsion system active time during recent operation (time < 100 hours). OBD requires all hybrids to support this parameter.";
CM_ SG_ 2566583294 IdlePropulsionSysActiveTime "Cumulative idle (v <= 1.6 km/h) propulsion system active time during recent operation (time < 100 hours). OBD requires all hybrids to support this parameter.";
CM_ SG_ 2566583294 PropulsionSysActiveTime "Cumulative propulsion system active time during recent operation (time < 100 hours). OBD requires all hybrids to support this parameter.";
CM_ BO_ 2566583038 "PSA Times Stored 100 Hours
Most recent stored cumulative propulsion system active time during 100 hours of vehicle operation (i.e. stored 100 hours). OBD requires all hybrids to support this message.";
CM_ SG_ 2566583038 UrbanPropulsionSysActiveTime "Most recent stored cumulative urban (1.6 km/h < v <= 60 km/h) propulsion system active time during 100 hours of vehicle operation. OBD requires all hybrids to support this parameter.";
CM_ SG_ 2566583038 IdlePropulsionSysActiveTime "Most recent stored cumulative idle (v <= 1.6 km/h) propulsion system active time during 100 hours of vehicle operation. OBD requires all hybrids to support this parameter.";
CM_ SG_ 2566583038 RecentPropulsionSysActiveTime "Most recent stored cumulative propulsion system active time during 100 hours of vehicle operation. OBD requires all hybrids to support this parameter.";
CM_ BO_ 2566582782 "PSA Times Lifetime Hours
Total propulsion system active time during the lifetime of the vehicle (i.e. lifetime hours). OBD requires all hybrids to support this message.";
CM_ SG_ 2566582782 UrbanPropulsionSysActiveTime "Total urban (1.6 km/h < v <= 60 km/h) propulsion system active time during the lifetime of the vehicle. OBD requires all hybrids to support this parameter.";
CM_ SG_ 2566582782 IdlePropulsionSysActiveTime "Total idle propulsion system active time (v <= 1.6 km/h) during the lifetime of the vehicle. OBD requires all hybrids to support this parameter.";
CM_ SG_ 2566582782 PropulsionSysActiveTime "Total propulsion system active time during the lifetime of the vehicle. OBD requires all hybrids to support this parameter.";
CM_ BO_ 2566582526 "Aftertreatment 1 SCR Service Information 3
This message contains SCR service information for aftertreatment system 1 (or bank 1).";
CM_ SG_ 2566582526 DEFUsedThisOperatingCycle "Total amount of DEF used by aftertreatment device 1 over the current operating cycle (from engine start to engine start).
Note: See SPN 12748 for total accumulation of aftertreatment device 1 and 2.  See SPN 5963 for total accumulation of ...";
CM_ SG_ 2566582526 NormalizedConversionEfficiency "The ratio of measured SCR Catalyst conversion efficiency to the estimated nominal SCR Catalyst conversion efficiency, represented as a percentage.";
CM_ BO_ 2566582270 "Aftertreatment 2 SCR Service Information 3
This message contains SCR service information for aftertreatment system 2 (or bank 2).";
CM_ SG_ 2566582270 NormalizedConversionEfficiency "The ratio of measured SCR Catalyst conversion efficiency to the estimated nominal SCR Catalyst conversion efficiency, represented as a percentage.";
CM_ BO_ 2566582014 "Temperature Sensing Module 2
Transmits information about the temperature sensing module on an engine or aftertreatment system.";
CM_ SG_ 2566582014 One6PreliminaryFMI "Used to identify the applicable J1939-73 FMI detected in the Temperature Sensing Module 16 by the manufacturer's software. When there are multiple failures, the most severe is transmitted.
A value of 31 is sent to indicate that no failure has been ...";
CM_ SG_ 2566582014 One5PreliminaryFMI "Used to identify the applicable J1939-73 FMI detected in the Temperature Sensing Module 15 by the manufacturer's software. When there are multiple failures, the most severe is transmitted.
A value of 31 is sent to indicate that no failure has been ...";
CM_ SG_ 2566582014 One4PreliminaryFMI "Used to identify the applicable J1939-73 FMI detected in the Temperature Sensing Module 14 by the manufacturer's software. When there are multiple failures, the most severe is transmitted.
A value of 31 is sent to indicate that no failure has been ...";
CM_ SG_ 2566582014 One3PreliminaryFMI "Used to identify the applicable J1939-73 FMI detected in the Temperature Sensing Module 13 by the manufacturer's software. When there are multiple failures, the most severe is transmitted.
A value of 31 is sent to indicate that no failure has been ...";
CM_ SG_ 2566582014 One2PreliminaryFMI "Used to identify the applicable J1939-73 FMI detected in the Temperature Sensing Module 12 by the manufacturer's software. When there are multiple failures, the most severe is transmitted.
A value of 31 is sent to indicate that no failure has been ...";
CM_ SG_ 2566582014 One1PreliminaryFMI "Used to identify the applicable J1939-73 FMI detected in the Temperature Sensing Module 11 by the manufacturer's software. When there are multiple failures, the most severe is transmitted.
A value of 31 is sent to indicate that no failure has been ...";
CM_ SG_ 2566582014 One0PreliminaryFMI "Used to identify the applicable J1939-73 FMI detected in the Temperature Sensing Module 10 by the manufacturer's software. When there are multiple failures, the most severe is transmitted.
A value of 31 is sent to indicate that no failure has been ...";
CM_ SG_ 2566582014 NinePreliminaryFMI "Used to identify the applicable J1939-73 FMI detected in the Temperature Sensing Module 9 by the manufacturer's software. When there are multiple failures, the most severe is transmitted.
A value of 31 is sent to indicate that no failure has been ...";
CM_ BO_ 2566581758 "Temperature Sensing Module 1
Transmits information about the temperature sensing module on an engine or aftertreatment system.";
CM_ SG_ 2566581758 EightPreliminaryFMI "Used to identify the applicable J1939-73 FMI detected in the Temperature Sensing Module 8 by the manufacturer's software. When there are multiple failures, the most severe is transmitted.
A value of 31 is sent to indicate that no failure has been ...";
CM_ SG_ 2566581758 SevenPreliminaryFMI "Used to identify the applicable J1939-73 FMI detected in the Temperature Sensing Module 7 by the manufacturer's software. When there are multiple failures, the most severe is transmitted.
A value of 31 is sent to indicate that no failure has been ...";
CM_ SG_ 2566581758 SixPreliminaryFMI "Used to identify the applicable J1939-73 FMI detected in the Temperature Sensing Module 6 by the manufacturer's software. When there are multiple failures, the most severe is transmitted.
A value of 31 is sent to indicate that no failure has been ...";
CM_ SG_ 2566581758 FivePreliminaryFMI "Used to identify the applicable J1939-73 FMI detected in the Temperature Sensing Module 5 by the manufacturer's software. When there are multiple failures, the most severe is transmitted.
A value of 31 is sent to indicate that no failure has been ...";
CM_ SG_ 2566581758 FourPreliminaryFMI "Used to identify the applicable J1939-73 FMI detected in the Temperature Sensing Module 4 by the manufacturer's software. When there are multiple failures, the most severe is transmitted.
A value of 31 is sent to indicate that no failure has been ...";
CM_ SG_ 2566581758 ThreePreliminaryFMI "Used to identify the applicable J1939-73 FMI detected in the Temperature Sensing Module 3 by the manufacturer's software. When there are multiple failures, the most severe is transmitted.
A value of 31 is sent to indicate that no failure has been ...";
CM_ SG_ 2566581758 TwoPreliminaryFMI "Used to identify the applicable J1939-73 FMI detected in the Temperature Sensing Module 2 by the manufacturer's software. When there are multiple failures, the most severe is transmitted.
A value of 31 is sent to indicate that no failure has been ...";
CM_ SG_ 2566581758 PreliminaryFMI "Used to identify the applicable J1939-73 FMI detected in the Temperature Sensing Module 1 by the manufacturer's software. When there are multiple failures, the most severe is transmitted.
A value of 31 is sent to indicate that no failure has been ...";
CM_ BO_ 2566000638 "Motor/Generator 6 Inverter Rate Limits Request 1
Requests the rate limits for this instance of inverter being controlled. Some examples of use would be for a hybrid or electric vehicle propulsion motor or generator.";
CM_ SG_ 2566000638 AbsTrqRateLmt "The maximum rate of change for the absolute motor torque (i.e. |d(torque)|/dt) in all control modes.
Refer to SPN 12175 [Reference Torque] to convert %/sec to Nm/sec.
Request a value of FBFh to instruct the inverter to use its default values.
 ...";
CM_ SG_ 2566000638 AbsSpdRateLmt "The maximum rate of change for the absolute motor speed  (i.e. |d(speed)|/dt) in all control modes.
This limit shall solely lead to reducing the absolute torque, not increasing it nor changing the torque direction. Therefore, when limits are ...";
CM_ SG_ 2566000638 Counter "The message counter is used to detect situations where the transmitting ECU malfunction repeats the same frame all the time. The receiver of the information may use the counter parameter to detect this situation. The transmitting device will ...";
CM_ SG_ 2566000638 CRC "The CRC is defined as follows:
• Length: 8 bits
• Polynomial: x^8+x^5+x^3+x^2+x+1
• Initial Value: FFh
• Input Data Reflection: Not reflected
• Result Data Reflection: Not reflected
• XOR value: FFh
SAE makes no claim of the functional safety ...";
CM_ BO_ 2364673790 "Motor/Generator 6 Inverter Control
Primary Control Message from this instance of Inverter.  Some examples of use would be for a hybrid or electric vehicle propulsion motor or generator.";
CM_ SG_ 2364673790 SetpointReq "Requests the set point for this inverter.  The type of set point requested by this parameter depends on the value of SPN 12167 [Control Setpoint Mode Request] as follows:
Passive Modes:
In any Passive Mode, a bit value of FBFFh shall be set.
 ...";
CM_ SG_ 2364673790 SetpointModeReq "Requests the modes for this instance of the inverter.  See SPN 12172 [Control Setpoint Mode] for the feedback to this request.
Passive modes:  Modes where the inverter does not actively control the motor torque, for example.
0 = Power On - the ...";
CM_ SG_ 2364673790 LimitsReqOvrdMin "The Minimum limit requested by this parameter depends on the value of SPN 12164 [Control Limits Request Override Mode].
In normal operating conditions, the inverter operating limits are based on internal settings or Limits Request parameters as ...";
CM_ SG_ 2364673790 LimitsReqOvrdMax "The Maximum limit requested by this parameter depends on the value of SPN 12164 [Control Limits Request Override Mode].
In normal operating conditions, the inverter operating limits are based on internal settings or Limits Request parameters as ...";
CM_ SG_ 2364673790 LimitsReqOvrdMode "This parameter provides a way to temporarily override limits that are being received by the inverter in other messages.  It allows a specific type of limit to be transmitted at a high rate or at the same moment as the set point for synchronization ...";
CM_ SG_ 2364673790 Counter "The message counter is used to detect situations where the transmitting ECU malfunction repeats the same frame all the time. The receiver of the information may use the counter parameter to detect this situation. The transmitting device will ...";
CM_ SG_ 2364673790 CRC "The CRC is defined as follows:
• Length: 8 bits
• Polynomial: x^8+x^5+x^3+x^2+x+1
• Initial Value: FFh
• Input Data Reflection: Not reflected
• Result Data Reflection: Not reflected
• XOR value: FFh
SAE makes no claim of the functional safety ...";
CM_ BO_ 2566000126 "Motor/Generator 5 Inverter Rate Limits Request 1
Requests the rate limits for this instance of inverter being controlled. Some examples of use would be for a hybrid or electric vehicle propulsion motor or generator.";
CM_ SG_ 2566000126 AbsTrqRateLmt "The maximum rate of change for the absolute motor torque (i.e. |d(torque)|/dt) in all control modes.
Refer to SPN 12057 [Reference Torque] to convert %/sec to Nm/sec.
Request a value of FBFh to instruct the inverter to use its default values.
 ...";
CM_ SG_ 2566000126 AbsSpdRateLmt "The maximum rate of change for the absolute motor speed  (i.e. |d(speed)|/dt) in all control modes.
This limit shall solely lead to reducing the absolute torque, not increasing it nor changing the torque direction. Therefore, when limits are ...";
CM_ SG_ 2566000126 Counter "The message counter is used to detect situations where the transmitting ECU malfunction repeats the same frame all the time. The receiver of the information may use the counter parameter to detect this situation. The transmitting device will ...";
CM_ SG_ 2566000126 CRC "The CRC is defined as follows:
• Length: 8 bits
• Polynomial: x^8+x^5+x^3+x^2+x+1
• Initial Value: FFh
• Input Data Reflection: Not reflected
• Result Data Reflection: Not reflected
• XOR value: FFh
SAE makes no claim of the functional safety ...";
CM_ BO_ 2364673278 "Motor/Generator 5 Inverter Control
Primary Control Message from this instance of Inverter.  Some examples of use would be for a hybrid or electric vehicle propulsion motor or generator.";
CM_ SG_ 2364673278 SetpointReq "Requests the set point for this inverter.  The type of set point requested by this parameter depends on the value of SPN 12049 [Control Setpoint Mode Request] as follows:
Passive Modes:
In any Passive Mode, a bit value of FBFFh shall be set.
 ...";
CM_ SG_ 2364673278 SetpointModeReq "Requests the modes for this instance of the inverter.  See SPN 12054 [Control Setpoint Mode] for the feedback to this request.
Passive modes:  Modes where the inverter does not actively control the motor torque, for example.
0 = Power On - the ...";
CM_ SG_ 2364673278 LimitsReqOvrdMin "The Minimum limit requested by this parameter depends on the value of SPN 12046 [Control Limits Request Override Mode].
In normal operating conditions, the inverter operating limits are based on internal settings or Limits Request parameters as ...";
CM_ SG_ 2364673278 LimitsReqOvrdMax "The Maximum limit requested by this parameter depends on the value of SPN 12046 [Control Limits Request Override Mode].
In normal operating conditions, the inverter operating limits are based on internal settings or Limits Request parameters as ...";
CM_ SG_ 2364673278 LimitsReqOvrdMode "This parameter provides a way to temporarily override limits that are being received by the inverter in other messages.  It allows a specific type of limit to be transmitted at a high rate or at the same moment as the set point for synchronization ...";
CM_ SG_ 2364673278 Counter "The message counter is used to detect situations where the transmitting ECU malfunction repeats the same frame all the time. The receiver of the information may use the counter parameter to detect this situation. The transmitting device will ...";
CM_ SG_ 2364673278 CRC "The CRC is defined as follows:
• Length: 8 bits
• Polynomial: x^8+x^5+x^3+x^2+x+1
• Initial Value: FFh
• Input Data Reflection: Not reflected
• Result Data Reflection: Not reflected
• XOR value: FFh
SAE makes no claim of the functional safety ...";
CM_ BO_ 2565999614 "Motor/Generator 4 Inverter Rate Limits Request 1
Requests the rate limits for this instance of inverter being controlled. Some examples of use would be for a hybrid or electric vehicle propulsion motor or generator.";
CM_ SG_ 2565999614 AbsTrqRateLmt "The maximum rate of change for the absolute motor torque (i.e. |d(torque)|/dt) in all control modes.
Refer to SPN 11939 [Reference Torque] to convert %/sec to Nm/sec.
Request a value of FBFh to instruct the inverter to use its default values.
 ...";
CM_ SG_ 2565999614 AbsSpdRateLmt "The maximum rate of change for the absolute motor speed  (i.e. |d(speed)|/dt) in all control modes.
This limit shall solely lead to reducing the absolute torque, not increasing it nor changing the torque direction. Therefore, when limits are ...";
CM_ SG_ 2565999614 Counter "The message counter is used to detect situations where the transmitting ECU malfunction repeats the same frame all the time. The receiver of the information may use the counter parameter to detect this situation. The transmitting device will ...";
CM_ SG_ 2565999614 CRC "The CRC is defined as follows:
• Length: 8 bits
• Polynomial: x^8+x^5+x^3+x^2+x+1
• Initial Value: FFh
• Input Data Reflection: Not reflected
• Result Data Reflection: Not reflected
• XOR value: FFh
SAE makes no claim of the functional safety ...";
CM_ BO_ 2364672766 "Motor/Generator 4 Inverter Control
Primary Control Message from this instance of Inverter.  Some examples of use would be for a hybrid or electric vehicle propulsion motor or generator.";
CM_ SG_ 2364672766 SetpointReq "Requests the set point for this inverter.  The type of set point requested by this parameter depends on the value of SPN 11931 [Control Setpoint Mode Request] as follows:
Passive Modes:
In any Passive Mode, a bit value of FBFFh shall be set.
 ...";
CM_ SG_ 2364672766 SetpointModeReq "Requests the modes for this instance of the inverter.  See SPN 11936 [Control Setpoint Mode] for the feedback to this request.
Passive modes:  Modes where the inverter does not actively control the motor torque, for example.
0 = Power On - the ...";
CM_ SG_ 2364672766 LimitsReqOvrdMin "The Minimum limit requested by this parameter depends on the value of SPN 11928 [Control Limits Request Override Mode].
In normal operating conditions, the inverter operating limits are based on internal settings or Limits Request parameters as ...";
CM_ SG_ 2364672766 LimitsReqOvrdMax "The Maximum limit requested by this parameter depends on the value of SPN 11928 [Control Limits Request Override Mode].
In normal operating conditions, the inverter operating limits are based on internal settings or Limits Request parameters as ...";
CM_ SG_ 2364672766 LimitsReqOvrdMode "This parameter provides a way to temporarily override limits that are being received by the inverter in other messages.  It allows a specific type of limit to be transmitted at a high rate or at the same moment as the set point for synchronization ...";
CM_ SG_ 2364672766 Counter "The message counter is used to detect situations where the transmitting ECU malfunction repeats the same frame all the time. The receiver of the information may use the counter parameter to detect this situation. The transmitting device will ...";
CM_ SG_ 2364672766 CRC "The CRC is defined as follows:
• Length: 8 bits
• Polynomial: x^8+x^5+x^3+x^2+x+1
• Initial Value: FFh
• Input Data Reflection: Not reflected
• Result Data Reflection: Not reflected
• XOR value: FFh
SAE makes no claim of the functional safety ...";
CM_ BO_ 2565999102 "Motor/Generator 3 Inverter Rate Limits Request 1
Requests the rate limits for this instance of inverter being controlled. Some examples of use would be for a hybrid or electric vehicle propulsion motor or generator.";
CM_ SG_ 2565999102 AbsTrqRateLmt "The maximum rate of change for the absolute motor torque (i.e. |d(torque)|/dt) in all control modes.
Refer to SPN 11821 [Reference Torque] to convert %/sec to Nm/sec.
Request a value of FBFh to instruct the inverter to use its default values.
 ...";
CM_ SG_ 2565999102 AbsSpdRateLmt "The maximum rate of change for the absolute motor speed  (i.e. |d(speed)|/dt) in all control modes.
This limit shall solely lead to reducing the absolute torque, not increasing it nor changing the torque direction. Therefore, when limits are ...";
CM_ SG_ 2565999102 Counter "The message counter is used to detect situations where the transmitting ECU malfunction repeats the same frame all the time. The receiver of the information may use the counter parameter to detect this situation. The transmitting device will ...";
CM_ SG_ 2565999102 CRC "The CRC is defined as follows:
• Length: 8 bits
• Polynomial: x^8+x^5+x^3+x^2+x+1
• Initial Value: FFh
• Input Data Reflection: Not reflected
• Result Data Reflection: Not reflected
• XOR value: FFh
SAE makes no claim of the functional safety ...";
CM_ BO_ 2364672254 "Motor/Generator 3 Inverter Control
Primary Control Message from this instance of Inverter.  Some examples of use would be for a hybrid or electric vehicle propulsion motor or generator.";
CM_ SG_ 2364672254 SetpointReq "Requests the set point for this inverter.  The type of set point requested by this parameter depends on the value of SPN 11813 [Control Setpoint Mode Request] as follows:
Passive Modes:
In any Passive Mode, a bit value of FBFFh shall be set.
 ...";
CM_ SG_ 2364672254 SetpointModeReq "Requests the modes for this instance of the inverter.  See SPN 11818 [Control Setpoint Mode] for the feedback to this request.
Passive modes:  Modes where the inverter does not actively control the motor torque, for example.
0 = Power On - the ...";
CM_ SG_ 2364672254 LimitsReqOvrdMin "The Minimum limit requested by this parameter depends on the value of SPN 11810 [Control Limits Request Override Mode].
In normal operating conditions, the inverter operating limits are based on internal settings or Limits Request parameters as ...";
CM_ SG_ 2364672254 LimitsReqOvrdMax "The Maximum limit requested by this parameter depends on the value of SPN 11810 [Control Limits Request Override Mode].
In normal operating conditions, the inverter operating limits are based on internal settings or Limits Request parameters as ...";
CM_ SG_ 2364672254 LimitsReqOvrdMode "This parameter provides a way to temporarily override limits that are being received by the inverter in other messages.  It allows a specific type of limit to be transmitted at a high rate or at the same moment as the set point for synchronization ...";
CM_ SG_ 2364672254 Counter "The message counter is used to detect situations where the transmitting ECU malfunction repeats the same frame all the time. The receiver of the information may use the counter parameter to detect this situation. The transmitting device will ...";
CM_ SG_ 2364672254 CRC "The CRC is defined as follows:
• Length: 8 bits
• Polynomial: x^8+x^5+x^3+x^2+x+1
• Initial Value: FFh
• Input Data Reflection: Not reflected
• Result Data Reflection: Not reflected
• XOR value: FFh
SAE makes no claim of the functional safety ...";
CM_ BO_ 2364671998 "Winch Information 1
Message provides status information for a winch";
CM_ SG_ 2364671998 MotorOverspeed "Indicates whether the winch motor is exceeding the recommended maximum speed.

00b = No overspeed
01b = Overspeed
10b = Error
11b = Not available";
CM_ SG_ 2364671998 MotorDir "Direction of rotation of the winch motor as viewed from the motor end of the winch looking into the gearbox/drum.
00b = CounterClockWise (CCW)
01b = ClockWise (CW)
10b = Unknown (Rotation Direction Unknown)
11b = Not Available
Note:  When the ...";
CM_ SG_ 2364671998 MotorSpd "Rotational speed of the winch motor.";
CM_ SG_ 2364671998 RevolutionCounter "Count of complete revolutions since reset. Value increments in forward direction and decrements in reverse direction.";
CM_ SG_ 2364671998 MotorEncoderPos "Angular position of the winch motor shaft where 0 represents the initial position, with the value incrementing up to 32767 before rolling over to 0 at one complete revolution.  Likewise, the value decrements for reverse rotation, rolling to 32767 ...";
CM_ BO_ 2364671742 "Blind Spot Detection 1
The Blind Spot Detection 1 message includes the function state and required warning for systems that are monitoring zone around the vehicle.";
CM_ SG_ 2364671742 RearMonitored "Indicates if rear area is monitored by the blind spot detection system. This signal can be used to trigger the correct warning(s) in the human machine interface (HMI).
00b = Not being monitored
01b = Monitored
10b = Error indication
11b = Not ...";
CM_ SG_ 2364671742 FrontMonitored "Indicates if front area is monitored by the blind spot detection system. This signal can be used to trigger the correct warning(s) in the human machine interface (HMI).
00b = Not being monitored
01b = Monitored
10b = Error indication
11b = Not ...";
CM_ SG_ 2364671742 RightSideMonitored "Indicates if right side area is monitored by the blind spot detection system. This signal can be used to trigger the correct warning(s) in the human machine interface (HMI).
00b = Not being monitored
01b = Monitored
10b = Error indication
11b = ...";
CM_ SG_ 2364671742 LeftSideMonitored "Indicates if left side area is monitored by the blind spot detection system. This signal can be used to trigger the correct warning(s) in the human machine interface (HMI).
00b = Not being monitored
01b = Monitored
10b = Error indication
11b = ...";
CM_ SG_ 2364671742 BendOffProbOfMostImportantObj "Probabilty if the most important monitored relevant object might start a bend-off maneuver (e.g. turning), which could clear the travelling path of the host vehicle.
000b = no indication for a bend-off maneuver of the object
001b = low probability ...";
CM_ SG_ 2364671742 WarnRelevantObjDetected "Indication if the blind spot detection system (BSD) is monitoring a relevant object.
000b = No relevant object monitored
001b = Single relevant object is being monitored
010b = Multiple relevant objects are being monitored
011b - 100b = Reserved
 ...";
CM_ SG_ 2364671742 CollisionWarnLvl "To implement different human machine interface (HMI) concepts, e.g. visual only, visual/audible, different warning tones etc., the object detection provides different levels of collision warning.
0000b = no warning
0001b = warning level 1 - lowest ...";
CM_ SG_ 2364671742 St "Current operational state of the blind spot detection function.
0000b = system is not ready (initialization not finished)
0001b = system is temporarily not available (e.g. due to boundary conditions necessary for operation)
0010b = system is ...";
CM_ BO_ 2565998078 "Motor/Generator 6 Inverter Rate Limits Active 1
Reports the active rate limits for this instance of inverter being controlled. Some examples of use would be for a hybrid or electric vehicle propulsion motor or generator.";
CM_ SG_ 2565998078 AbsTrqRateLmt "The active maximum rate of change for the absolute motor torque (i.e. |d(torque)|/dt) in all control modes of this motor/generator inverter instance.
Refer to SPN 12175 [Reference Torque] to convert %/sec to Nm/sec.
(Torque Rate Limit in Nm/sec) = ...";
CM_ SG_ 2565998078 AbsSpdRateLmt "The active maximum rate of change for the absolute motor speed  (i.e. |d(speed)|/dt) in all control modes of this motor/generator inverter instance.
Refer to SPN 12176 [Reference Speed] to convert %/sec to RPM/sec.
(Speed Rate Limit in rpm/sec) = ...";
CM_ SG_ 2565998078 Counter "The message counter is used to detect situations where the transmitting ECU malfunction repeats the same frame all the time. The receiver of the information may use the counter parameter to detect this situation. The transmitting device will ...";
CM_ SG_ 2565998078 CRC "The CRC is defined as follows:
• Length: 8 bits
• Polynomial: x^8+x^5+x^3+x^2+x+1
• Initial Value: FFh
• Input Data Reflection: Not reflected
• Result Data Reflection: Not reflected
• XOR value: FFh
SAE makes no claim of the functional safety ...";
CM_ BO_ 2565997822 "Motor/Generator 6 Inverter Status 2
Second Status Message from the Inverter.  Some examples of use would be for a hybrid or electric vehicle propulsion motor or generator.";
CM_ SG_ 2565997822 AvailableMinTrq "This is an estimate of the minimum available motor torque including active deratings at the present motor speed.  This refers to the motor rotor output and excludes any gearbox that may be attached to the motor.
Refer to SPN 12175 [Reference ...";
CM_ SG_ 2565997822 AvailableMaxTrq "This is an estimate of the maximum available motor torque including active deratings at the present motor speed.  This refers to the motor rotor output and excludes any gearbox that may be attached to the motor.
Refer to SPN 12175 [Reference ...";
CM_ SG_ 2565997822 Counter "The message counter is used to detect situations where the transmitting ECU malfunction repeats the same frame all the time. The receiver of the information may use the counter parameter to detect this situation. The transmitting device will ...";
CM_ SG_ 2565997822 CRC "The CRC is defined as follows:
• Length: 8 bits
• Polynomial: x^8+x^5+x^3+x^2+x+1
• Initial Value: FFh
• Input Data Reflection: Not reflected
• Result Data Reflection: Not reflected
• XOR value: FFh
SAE makes no claim of the functional safety ...";
CM_ BO_ 2565997566 "Motor/Generator 6 Inverter Low Voltage
Low Voltage data from this Motor/Generator Inverter.";
CM_ SG_ 2565997566 UnswitchedSLIV "Continuously supplied SLI power to this instance of the inverter controller.";
CM_ SG_ 2565997566 SwitchedIgntV "Switched Ignition voltage supplied to this instance of the inverter controller.";
CM_ BO_ 2565997310 "Motor/Generator 6 Inverter Limits Active DC Side
The DC side electrical limits the inverter is actually using.  These may differ from the requested limits.";
CM_ SG_ 2565997310 CurMin "The inverter keeps the DC side current above this value.  This limit may be set in response to a Limits Request or determined by the inverter based on operating conditions.
Refer to SPN 12207 [Reference Current] to convert % to Amps.
While ...";
CM_ SG_ 2565997310 CurMax "The inverter keeps the DC side current below this value.  This limit may be set in response to a Limits Request or determined by the inverter based on operating conditions.
Refer to SPN 12207 [Reference Current] to convert % to Amps.
While ...";
CM_ SG_ 2565997310 VMin "The inverter keeps the DC side voltage above this value.  This limit may be set in response to a Limits Request or determined by the inverter based on operating conditions.
Refer to SPN 12208 [Reference Voltage] to convert % to Volts.
While DC ...";
CM_ SG_ 2565997310 VMax "The inverter keeps the DC side voltage below this value.  This limit may be set in response to a Limits Request or determined by the inverter based on operating conditions.
Refer to SPN 12208 [Reference Voltage] to convert % to Volts.
While DC ...";
CM_ SG_ 2565997310 Counter "The message counter is used to detect situations where the transmitting ECU malfunction repeats the same frame all the time. The receiver of the information may use the counter parameter to detect this situation. The transmitting device will ...";
CM_ SG_ 2565997310 CRC "The CRC is defined as follows:
• Length: 8 bits
• Polynomial: x^8+x^5+x^3+x^2+x+1
• Initial Value: FFh
• Input Data Reflection: Not reflected
• Result Data Reflection: Not reflected
• XOR value: FFh
SAE makes no claim of the functional safety ...";
CM_ BO_ 2565997054 "Motor/Generator 6 Inverter Limits Active Mechanical
The Torque and Speed limits the inverter is actually using.  These may differ from the requested limits.";
CM_ SG_ 2565997054 SpdMin "The inverter keeps the motor Speed above this value.  This limit may be set in response to a Limits Request or determined by the inverter based on operating conditions.

Refer to SPN 12176 [Reference Speed] to convert % to rpm.";
CM_ SG_ 2565997054 SpdMax "The inverter keeps the motor speed below this value.  This limit may be set in response to a Limits Request or determined by the inverter based on operating conditions.

Refer to SPN 12176 [Reference Speed] to convert % to rpm.";
CM_ SG_ 2565997054 TrqMin "The inverter keeps the motor torque above this value.  This limit may be set in response to a Limits Request or determined by the inverter based on operating conditions.

Refer to SPN 12175 [Reference Torque] to convert % to Nm.";
CM_ SG_ 2565997054 TrqMax "The inverter keeps the motor torque below this value.  This limit may be set in response to a Limits Request or determined by the inverter based on operating conditions.

Refer to SPN 12175 [Reference Torque] to convert % to Nm.";
CM_ SG_ 2565997054 Counter "The message counter is used to detect situations where the transmitting ECU malfunction repeats the same frame all the time. The receiver of the information may use the counter parameter to detect this situation. The transmitting device will ...";
CM_ SG_ 2565997054 CRC "The CRC is defined as follows:
• Length: 8 bits
• Polynomial: x^8+x^5+x^3+x^2+x+1
• Initial Value: FFh
• Input Data Reflection: Not reflected
• Result Data Reflection: Not reflected
• XOR value: FFh
SAE makes no claim of the functional safety ...";
CM_ BO_ 2565996798 "Motor/Generator 6 Inverter Limits Active Power
The electrical and mechanical power limits the inverter is actually using.  These may differ from the requested limits.";
CM_ SG_ 2565996798 DCSidePwrMin "The inverter keeps the DC side power above this value.   This limit may be set in response to a Limits Request or determined by the inverter based on operating conditions.
Refer to SPN 12177 [Reference Power] to convert % to kW.
For example, in a ...";
CM_ SG_ 2565996798 DCSidePwrMax "The inverter keeps the DC Side power below this value.   This limit may be set in response to a Limits Request or determined by the inverter based on operating conditions.
Refer to SPN 12177 [Reference Power] to convert % to kW.
For example, in a ...";
CM_ SG_ 2565996798 MechPwrMin "The inverter keeps the mechanical motor power above this value.   This limit may be set in response to a Limits Request or determined by the inverter based on operating conditions.
Refer to SPN 12177 [Reference Power] to convert % to kW.
For ...";
CM_ SG_ 2565996798 MechPwrMax "The inverter keeps the mechanical motor power below this value.   This limit may be set in response to a Limits Request or determined by the inverter based on operating conditions.
Refer to SPN 12177 [Reference Power] to convert % to kW.
For ...";
CM_ SG_ 2565996798 Counter "The message counter is used to detect situations where the transmitting ECU malfunction repeats the same frame all the time. The receiver of the information may use the counter parameter to detect this situation. The transmitting device will ...";
CM_ SG_ 2565996798 CRC "The CRC is defined as follows:
• Length: 8 bits
• Polynomial: x^8+x^5+x^3+x^2+x+1
• Initial Value: FFh
• Input Data Reflection: Not reflected
• Result Data Reflection: Not reflected
• XOR value: FFh
SAE makes no claim of the functional safety ...";
CM_ BO_ 2364669950 "Motor/Generator 6 Inverter Mode Feedback 1
The first mode feedback message from the inverter.";
CM_ SG_ 2364669950 HVILStatus "Reports the High Voltage Interlock Loop (HVIL) state.

00b = HVIL Closed
01b = HVIL Open
10b = Error
11b = Not Available";
CM_ SG_ 2364669950 CtrlSetpointMode "Reports the inverter mode (See SPN 12167 [Control Setpoint Mode Request] for requested mode).
Passive modes:
0 = Powered On - the inverter is commanded to be powered on and able to communicate, but the Power Stage is disabled e.g. no switching or ...";
CM_ SG_ 2364669950 CtrlLimitsOvrdMode "During normal operation this will have the same value as SPN 12164 [Control Limits Request Override Mode].
0 = Operating limits are not overridden.  If a limit was previously active, then it has reverted to its normal value as defined by its ...";
CM_ SG_ 2364669950 Counter "The message counter is used to detect situations where the transmitting ECU malfunction repeats the same frame all the time. The receiver of the information may use the counter parameter to detect this situation. The transmitting device will ...";
CM_ SG_ 2364669950 CRC "The CRC is defined as follows:
• Length: 8 bits
• Polynomial: x^8+x^5+x^3+x^2+x+1
• Initial Value: FFh
• Input Data Reflection: Not reflected
• Result Data Reflection: Not reflected
• XOR value: FFh
SAE makes no claim of the functional safety ...";
CM_ BO_ 2565996286 "Motor/Generator 5 Inverter Rate Limits Active 1
Reports the active rate limits for this instance of inverter being controlled. Some examples of use would be for a hybrid or electric vehicle propulsion motor or generator.";
CM_ SG_ 2565996286 AbsTrqRateLmt "The active maximum rate of change for the absolute motor torque (i.e. |d(torque)|/dt) in all control modes of this motor/generator inverter instance.
Refer to SPN 12057 [Reference Torque] to convert %/sec to Nm/sec.
(Torque Rate Limit in Nm/sec) = ...";
CM_ SG_ 2565996286 AbsSpdRateLmt "The active maximum rate of change for the absolute motor speed  (i.e. |d(speed)|/dt) in all control modes of this motor/generator inverter instance.
Refer to SPN 12058 [Reference Speed] to convert %/sec to RPM/sec.
(Speed Rate Limit in rpm/sec) = ...";
CM_ SG_ 2565996286 Counter "The message counter is used to detect situations where the transmitting ECU malfunction repeats the same frame all the time. The receiver of the information may use the counter parameter to detect this situation. The transmitting device will ...";
CM_ SG_ 2565996286 CRC "The CRC is defined as follows:
• Length: 8 bits
• Polynomial: x^8+x^5+x^3+x^2+x+1
• Initial Value: FFh
• Input Data Reflection: Not reflected
• Result Data Reflection: Not reflected
• XOR value: FFh
SAE makes no claim of the functional safety ...";
CM_ BO_ 2565996030 "Motor/Generator 5 Inverter Status 2
Second Status Message from the Inverter.  Some examples of use would be for a hybrid or electric vehicle propulsion motor or generator.";
CM_ SG_ 2565996030 AvailableMinTrq "This is an estimate of the minimum available motor torque including active deratings at the present motor speed.  This refers to the motor rotor output and excludes any gearbox that may be attached to the motor.
Refer to SPN 12057 [Reference ...";
CM_ SG_ 2565996030 AvailableMaxTrq "This is an estimate of the maximum available motor torque including active deratings at the present motor speed.  This refers to the motor rotor output and excludes any gearbox that may be attached to the motor.
Refer to SPN 12057 [Reference ...";
CM_ SG_ 2565996030 Counter "The message counter is used to detect situations where the transmitting ECU malfunction repeats the same frame all the time. The receiver of the information may use the counter parameter to detect this situation. The transmitting device will ...";
CM_ SG_ 2565996030 CRC "The CRC is defined as follows:
• Length: 8 bits
• Polynomial: x^8+x^5+x^3+x^2+x+1
• Initial Value: FFh
• Input Data Reflection: Not reflected
• Result Data Reflection: Not reflected
• XOR value: FFh
SAE makes no claim of the functional safety ...";
CM_ BO_ 2565995774 "Motor/Generator 5 Inverter Low Voltage
Low Voltage data from this Motor/Generator Inverter.";
CM_ SG_ 2565995774 UnswitchedSLIV "Continuously supplied SLI power to this instance of the inverter controller.";
CM_ SG_ 2565995774 SwitchedIgntV "Switched Ignition voltage supplied to this instance of the inverter controller.";
CM_ BO_ 2565995518 "Motor/Generator 5 Inverter Limits Active DC Side
The DC side electrical limits the inverter is actually using.  These may differ from the requested limits.";
CM_ SG_ 2565995518 CurMin "The inverter keeps the DC side current above this value.  This limit may be set in response to a Limits Request or determined by the inverter based on operating conditions.
Refer to SPN 12089 [Reference Current] to convert % to Amps.
While ...";
CM_ SG_ 2565995518 CurMax "The inverter keeps the DC side current below this value.  This limit may be set in response to a Limits Request or determined by the inverter based on operating conditions.
Refer to SPN 12089 [Reference Current] to convert % to Amps.
While ...";
CM_ SG_ 2565995518 VMin "The inverter keeps the DC side voltage above this value.  This limit may be set in response to a Limits Request or determined by the inverter based on operating conditions.
Refer to SPN 12090 [Reference Voltage] to convert % to Volts.
While DC ...";
CM_ SG_ 2565995518 VMax "The inverter keeps the DC side voltage below this value.  This limit may be set in response to a Limits Request or determined by the inverter based on operating conditions.
Refer to SPN 12090 [Reference Voltage] to convert % to Volts.
While DC ...";
CM_ SG_ 2565995518 Counter "The message counter is used to detect situations where the transmitting ECU malfunction repeats the same frame all the time. The receiver of the information may use the counter parameter to detect this situation. The transmitting device will ...";
CM_ SG_ 2565995518 CRC "The CRC is defined as follows:
• Length: 8 bits
• Polynomial: x^8+x^5+x^3+x^2+x+1
• Initial Value: FFh
• Input Data Reflection: Not reflected
• Result Data Reflection: Not reflected
• XOR value: FFh
SAE makes no claim of the functional safety ...";
CM_ BO_ 2565995262 "Motor/Generator 5 Inverter Limits Active Mechanical
The Torque and Speed limits the inverter is actually using.  These may differ from the requested limits.";
CM_ SG_ 2565995262 SpdMin "The inverter keeps the motor Speed above this value.  This limit may be set in response to a Limits Request or determined by the inverter based on operating conditions.

Refer to SPN 12058 [Reference Speed] to convert % to rpm.";
CM_ SG_ 2565995262 SpdMax "The inverter keeps the motor speed below this value.  This limit may be set in response to a Limits Request or determined by the inverter based on operating conditions.

Refer to SPN 12058 [Reference Speed] to convert % to rpm.";
CM_ SG_ 2565995262 TrqMin "The inverter keeps the motor torque above this value.  This limit may be set in response to a Limits Request or determined by the inverter based on operating conditions.

Refer to SPN 12057 [Reference Torque] to convert % to Nm.";
CM_ SG_ 2565995262 TrqMax "The inverter keeps the motor torque below this value.  This limit may be set in response to a Limits Request or determined by the inverter based on operating conditions.

Refer to SPN 12057 [Reference Torque] to convert % to Nm.";
CM_ SG_ 2565995262 Counter "The message counter is used to detect situations where the transmitting ECU malfunction repeats the same frame all the time. The receiver of the information may use the counter parameter to detect this situation. The transmitting device will ...";
CM_ SG_ 2565995262 CRC "The CRC is defined as follows:
• Length: 8 bits
• Polynomial: x^8+x^5+x^3+x^2+x+1
• Initial Value: FFh
• Input Data Reflection: Not reflected
• Result Data Reflection: Not reflected
• XOR value: FFh
SAE makes no claim of the functional safety ...";
CM_ BO_ 2565995006 "Motor/Generator 5 Inverter Limits Active Power
The electrical and mechanical power limits the inverter is actually using.  These may differ from the requested limits.";
CM_ SG_ 2565995006 DCSidePwrMin "The inverter keeps the DC side power above this value.   This limit may be set in response to a Limits Request or determined by the inverter based on operating conditions.
Refer to SPN 12059 [Reference Power] to convert % to kW.
For example, in a ...";
CM_ SG_ 2565995006 DCSidePwrMax "The inverter keeps the DC Side power below this value.   This limit may be set in response to a Limits Request or determined by the inverter based on operating conditions.
Refer to SPN 12059 [Reference Power] to convert % to kW.
For example, in a ...";
CM_ SG_ 2565995006 MechPwrMin "The inverter keeps the mechanical motor power above this value.   This limit may be set in response to a Limits Request or determined by the inverter based on operating conditions.
Refer to SPN 12059 [Reference Power] to convert % to kW.
For ...";
CM_ SG_ 2565995006 MechPwrMax "The inverter keeps the mechanical motor power below this value.   This limit may be set in response to a Limits Request or determined by the inverter based on operating conditions.
Refer to SPN 12059 [Reference Power] to convert % to kW.
For ...";
CM_ SG_ 2565995006 Counter "The message counter is used to detect situations where the transmitting ECU malfunction repeats the same frame all the time. The receiver of the information may use the counter parameter to detect this situation. The transmitting device will ...";
CM_ SG_ 2565995006 CRC "The CRC is defined as follows:
• Length: 8 bits
• Polynomial: x^8+x^5+x^3+x^2+x+1
• Initial Value: FFh
• Input Data Reflection: Not reflected
• Result Data Reflection: Not reflected
• XOR value: FFh
SAE makes no claim of the functional safety ...";
CM_ BO_ 2364668158 "Motor/Generator 5 Inverter Mode Feedback 1
The first mode feedback message from the inverter.";
CM_ SG_ 2364668158 HVILStatus "Reports the High Voltage Interlock Loop (HVIL) state.

00b = HVIL Closed
01b = HVIL Open
10b = Error
11b = Not Available";
CM_ SG_ 2364668158 CtrlSetpointMode "Reports the inverter mode (See SPN 12049 [Control Setpoint Mode Request] for requested mode).
Passive modes:
0 = Powered On - the inverter is commanded to be powered on and able to communicate, but the Power Stage is disabled e.g. no switching or ...";
CM_ SG_ 2364668158 CtrlLimitsOvrdMode "During normal operation this will have the same value as SPN 12046 [Control Limits Request Override Mode].
0 = Operating limits are not overridden.  If a limit was previously active, then it has reverted to its normal value as defined by its ...";
CM_ SG_ 2364668158 Counter "The message counter is used to detect situations where the transmitting ECU malfunction repeats the same frame all the time. The receiver of the information may use the counter parameter to detect this situation. The transmitting device will ...";
CM_ SG_ 2364668158 CRC "The CRC is defined as follows:
• Length: 8 bits
• Polynomial: x^8+x^5+x^3+x^2+x+1
• Initial Value: FFh
• Input Data Reflection: Not reflected
• Result Data Reflection: Not reflected
• XOR value: FFh
SAE makes no claim of the functional safety ...";
CM_ BO_ 2565994494 "Motor/Generator 4 Inverter Rate Limits Active 1
Reports the active rate limits for this instance of inverter being controlled. Some examples of use would be for a hybrid or electric vehicle propulsion motor or generator.";
CM_ SG_ 2565994494 AbsTrqRateLmt "The active maximum rate of change for the absolute motor torque (i.e. |d(torque)|/dt) in all control modes of this motor/generator inverter instance.
Refer to SPN 11939 [Reference Torque] to convert %/sec to Nm/sec.
(Torque Rate Limit in Nm/sec) = ...";
CM_ SG_ 2565994494 AbsSpdRateLmt "The active maximum rate of change for the absolute motor speed  (i.e. |d(speed)|/dt) in all control modes of this motor/generator inverter instance.
Refer to SPN 11940 [Reference Speed] to convert %/sec to RPM/sec.
(Speed Rate Limit in rpm/sec) = ...";
CM_ SG_ 2565994494 Counter "The message counter is used to detect situations where the transmitting ECU malfunction repeats the same frame all the time. The receiver of the information may use the counter parameter to detect this situation. The transmitting device will ...";
CM_ SG_ 2565994494 CRC "The CRC is defined as follows:
• Length: 8 bits
• Polynomial: x^8+x^5+x^3+x^2+x+1
• Initial Value: FFh
• Input Data Reflection: Not reflected
• Result Data Reflection: Not reflected
• XOR value: FFh
SAE makes no claim of the functional safety ...";
CM_ BO_ 2565994238 "Motor/Generator 4 Inverter Status 2
Second Status Message from the Inverter.  Some examples of use would be for a hybrid or electric vehicle propulsion motor or generator.";
CM_ SG_ 2565994238 AvailableMinTrq "This is an estimate of the minimum available motor torque including active deratings at the present motor speed.  This refers to the motor rotor output and excludes any gearbox that may be attached to the motor.
Refer to SPN 11939 [Reference ...";
CM_ SG_ 2565994238 AvailableMaxTrq "This is an estimate of the maximum available motor torque including active deratings at the present motor speed.  This refers to the motor rotor output and excludes any gearbox that may be attached to the motor.
Refer to SPN 11939 [Reference ...";
CM_ SG_ 2565994238 Counter "The message counter is used to detect situations where the transmitting ECU malfunction repeats the same frame all the time. The receiver of the information may use the counter parameter to detect this situation. The transmitting device will ...";
CM_ SG_ 2565994238 CRC "The CRC is defined as follows:
• Length: 8 bits
• Polynomial: x^8+x^5+x^3+x^2+x+1
• Initial Value: FFh
• Input Data Reflection: Not reflected
• Result Data Reflection: Not reflected
• XOR value: FFh
SAE makes no claim of the functional safety ...";
CM_ BO_ 2565993982 "Motor/Generator 4 Inverter Low Voltage
Low Voltage data from this Motor/Generator Inverter.";
CM_ SG_ 2565993982 UnswitchedSLIV "Continuously supplied SLI power to this instance of the inverter controller.";
CM_ SG_ 2565993982 SwitchedIgntV "Switched Ignition voltage supplied to this instance of the inverter controller.";
CM_ BO_ 2565993726 "Motor/Generator 4 Inverter Limits Active DC Side
The DC side electrical limits the inverter is actually using.  These may differ from the requested limits.";
CM_ SG_ 2565993726 CurMin "The inverter keeps the DC side current above this value.  This limit may be set in response to a Limits Request or determined by the inverter based on operating conditions.
Refer to SPN 11971 [Reference Current] to convert % to Amps.
While ...";
CM_ SG_ 2565993726 CurMax "The inverter keeps the DC side current below this value.  This limit may be set in response to a Limits Request or determined by the inverter based on operating conditions.
Refer to SPN 11971 [Reference Current] to convert % to Amps.
While ...";
CM_ SG_ 2565993726 VMin "The inverter keeps the DC side voltage above this value.  This limit may be set in response to a Limits Request or determined by the inverter based on operating conditions.
Refer to SPN 11972 [Reference Voltage] to convert % to Volts.
While DC ...";
CM_ SG_ 2565993726 VMax "The inverter keeps the DC side voltage below this value.  This limit may be set in response to a Limits Request or determined by the inverter based on operating conditions.
Refer to SPN 11972 [Reference Voltage] to convert % to Volts.
While DC ...";
CM_ SG_ 2565993726 Counter "The message counter is used to detect situations where the transmitting ECU malfunction repeats the same frame all the time. The receiver of the information may use the counter parameter to detect this situation. The transmitting device will ...";
CM_ SG_ 2565993726 CRC "The CRC is defined as follows:
• Length: 8 bits
• Polynomial: x^8+x^5+x^3+x^2+x+1
• Initial Value: FFh
• Input Data Reflection: Not reflected
• Result Data Reflection: Not reflected
• XOR value: FFh
SAE makes no claim of the functional safety ...";
CM_ BO_ 2565993470 "Motor/Generator 4 Inverter Limits Active Mechanical
The Torque and Speed limits the inverter is actually using.  These may differ from the requested limits.";
CM_ SG_ 2565993470 SpdMin "The inverter keeps the motor Speed above this value.  This limit may be set in response to a Limits Request or determined by the inverter based on operating conditions.

Refer to SPN 11940 [Reference Speed] to convert % to rpm.";
CM_ SG_ 2565993470 SpdMax "The inverter keeps the motor speed below this value.  This limit may be set in response to a Limits Request or determined by the inverter based on operating conditions.

Refer to SPN 11940 [Reference Speed] to convert % to rpm.";
CM_ SG_ 2565993470 TrqMin "The inverter keeps the motor torque above this value.  This limit may be set in response to a Limits Request or determined by the inverter based on operating conditions.

Refer to SPN 11939 [Reference Torque] to convert % to Nm.";
CM_ SG_ 2565993470 TrqMax "The inverter keeps the motor torque below this value.  This limit may be set in response to a Limits Request or determined by the inverter based on operating conditions.

Refer to SPN 11939 [Reference Torque] to convert % to Nm.";
CM_ SG_ 2565993470 Counter "The message counter is used to detect situations where the transmitting ECU malfunction repeats the same frame all the time. The receiver of the information may use the counter parameter to detect this situation. The transmitting device will ...";
CM_ SG_ 2565993470 CRC "The CRC is defined as follows:
• Length: 8 bits
• Polynomial: x^8+x^5+x^3+x^2+x+1
• Initial Value: FFh
• Input Data Reflection: Not reflected
• Result Data Reflection: Not reflected
• XOR value: FFh
SAE makes no claim of the functional safety ...";
CM_ BO_ 2565993214 "Motor/Generator 4 Inverter Limits Active Power
The electrical and mechanical power limits the inverter is actually using.  These may differ from the requested limits.";
CM_ SG_ 2565993214 DCSidePwrMin "The inverter keeps the DC side power above this value.   This limit may be set in response to a Limits Request or determined by the inverter based on operating conditions.
Refer to SPN 11941 [Reference Power] to convert % to kW.
For example, in a ...";
CM_ SG_ 2565993214 DCSidePwrMax "The inverter keeps the DC Side power below this value.   This limit may be set in response to a Limits Request or determined by the inverter based on operating conditions.
Refer to SPN 11941 [Reference Power] to convert % to kW.
For example, in a ...";
CM_ SG_ 2565993214 MechPwrMin "The inverter keeps the mechanical motor power above this value.   This limit may be set in response to a Limits Request or determined by the inverter based on operating conditions.
Refer to SPN 11941 [Reference Power] to convert % to kW.
For ...";
CM_ SG_ 2565993214 MechPwrMax "The inverter keeps the mechanical motor power below this value.   This limit may be set in response to a Limits Request or determined by the inverter based on operating conditions.
Refer to SPN 11941 [Reference Power] to convert % to kW.
For ...";
CM_ SG_ 2565993214 Counter "The message counter is used to detect situations where the transmitting ECU malfunction repeats the same frame all the time. The receiver of the information may use the counter parameter to detect this situation. The transmitting device will ...";
CM_ SG_ 2565993214 CRC "The CRC is defined as follows:
• Length: 8 bits
• Polynomial: x^8+x^5+x^3+x^2+x+1
• Initial Value: FFh
• Input Data Reflection: Not reflected
• Result Data Reflection: Not reflected
• XOR value: FFh
SAE makes no claim of the functional safety ...";
CM_ BO_ 2364666366 "Motor/Generator 4 Inverter Mode Feedback 1
The first mode feedback message from the inverter.";
CM_ SG_ 2364666366 HVILStatus "Reports the High Voltage Interlock Loop (HVIL) state.

00b = HVIL Closed
01b = HVIL Open
10b = Error
11b = Not Available";
CM_ SG_ 2364666366 CtrlSetpointMode "Reports the inverter mode (See SPN 11931 [Control Setpoint Mode Request] for requested mode).
Passive modes:
0 = Powered On - the inverter is commanded to be powered on and able to communicate, but the Power Stage is disabled e.g. no switching or ...";
CM_ SG_ 2364666366 CtrlLimitsOvrdMode "During normal operation this will have the same value as SPN 11928 [Control Limits Request Override Mode].
0 = Operating limits are not overridden.  If a limit was previously active, then it has reverted to its normal value as defined by its ...";
CM_ SG_ 2364666366 Counter "The message counter is used to detect situations where the transmitting ECU malfunction repeats the same frame all the time. The receiver of the information may use the counter parameter to detect this situation. The transmitting device will ...";
CM_ SG_ 2364666366 CRC "The CRC is defined as follows:
• Length: 8 bits
• Polynomial: x^8+x^5+x^3+x^2+x+1
• Initial Value: FFh
• Input Data Reflection: Not reflected
• Result Data Reflection: Not reflected
• XOR value: FFh
SAE makes no claim of the functional safety ...";
CM_ BO_ 2565992702 "Motor/Generator 3 Inverter Rate Limits Active 1
Reports the active rate limits for this instance of inverter being controlled. Some examples of use would be for a hybrid or electric vehicle propulsion motor or generator.";
CM_ SG_ 2565992702 AbsTrqRateLmt "The active maximum rate of change for the absolute motor torque (i.e. |d(torque)|/dt) in all control modes of this motor/generator inverter instance.
Refer to SPN 11821 [Reference Torque] to convert %/sec to Nm/sec.
(Torque Rate Limit in Nm/sec) = ...";
CM_ SG_ 2565992702 AbsSpdRateLmt "The active maximum rate of change for the absolute motor speed  (i.e. |d(speed)|/dt) in all control modes of this motor/generator inverter instance.
Refer to SPN 11822 [Reference Speed] to convert %/sec to RPM/sec.
(Speed Rate Limit in rpm/sec) = ...";
CM_ SG_ 2565992702 Counter "The message counter is used to detect situations where the transmitting ECU malfunction repeats the same frame all the time. The receiver of the information may use the counter parameter to detect this situation. The transmitting device will ...";
CM_ SG_ 2565992702 CRC "The CRC is defined as follows:
• Length: 8 bits
• Polynomial: x^8+x^5+x^3+x^2+x+1
• Initial Value: FFh
• Input Data Reflection: Not reflected
• Result Data Reflection: Not reflected
• XOR value: FFh
SAE makes no claim of the functional safety ...";
CM_ BO_ 2565992446 "Motor/Generator 3 Inverter Status 2
Second Status Message from the Inverter.  Some examples of use would be for a hybrid or electric vehicle propulsion motor or generator.";
CM_ SG_ 2565992446 AvailableMinTrq "This is an estimate of the minimum available motor torque including active deratings at the present motor speed.  This refers to the motor rotor output and excludes any gearbox that may be attached to the motor.
Refer to SPN 11821 [Reference ...";
CM_ SG_ 2565992446 AvailableMaxTrq "This is an estimate of the maximum available motor torque including active deratings at the present motor speed.  This refers to the motor rotor output and excludes any gearbox that may be attached to the motor.
Refer to SPN 11821 [Reference ...";
CM_ SG_ 2565992446 Counter "The message counter is used to detect situations where the transmitting ECU malfunction repeats the same frame all the time. The receiver of the information may use the counter parameter to detect this situation. The transmitting device will ...";
CM_ SG_ 2565992446 CRC "The CRC is defined as follows:
• Length: 8 bits
• Polynomial: x^8+x^5+x^3+x^2+x+1
• Initial Value: FFh
• Input Data Reflection: Not reflected
• Result Data Reflection: Not reflected
• XOR value: FFh
SAE makes no claim of the functional safety ...";
CM_ BO_ 2565992190 "Motor/Generator 3 Inverter Low Voltage
Low Voltage data from this Motor/Generator Inverter.";
CM_ SG_ 2565992190 UnswitchedSLIV "Continuously supplied SLI power to this instance of the inverter controller.";
CM_ SG_ 2565992190 SwitchedIgntV "Switched Ignition voltage supplied to this instance of the inverter controller.";
CM_ BO_ 2565991934 "Motor/Generator 3 Inverter Limits Active DC Side
The DC side electrical limits the inverter is actually using.  These may differ from the requested limits.";
CM_ SG_ 2565991934 CurMin "The inverter keeps the DC side current above this value.  This limit may be set in response to a Limits Request or determined by the inverter based on operating conditions.
Refer to SPN 11853 [Reference Current] to convert % to Amps.
While ...";
CM_ SG_ 2565991934 CurMax "The inverter keeps the DC side current below this value.  This limit may be set in response to a Limits Request or determined by the inverter based on operating conditions.
Refer to SPN 11853 [Reference Current] to convert % to Amps.
While ...";
CM_ SG_ 2565991934 VMin "The inverter keeps the DC side voltage above this value.  This limit may be set in response to a Limits Request or determined by the inverter based on operating conditions.
Refer to SPN 11854 [Reference Voltage] to convert % to Volts.
While DC ...";
CM_ SG_ 2565991934 VMax "The inverter keeps the DC side voltage below this value.  This limit may be set in response to a Limits Request or determined by the inverter based on operating conditions.
Refer to SPN 11854 [Reference Voltage] to convert % to Volts.
While DC ...";
CM_ SG_ 2565991934 Counter "The message counter is used to detect situations where the transmitting ECU malfunction repeats the same frame all the time. The receiver of the information may use the counter parameter to detect this situation. The transmitting device will ...";
CM_ SG_ 2565991934 CRC "The CRC is defined as follows:
• Length: 8 bits
• Polynomial: x^8+x^5+x^3+x^2+x+1
• Initial Value: FFh
• Input Data Reflection: Not reflected
• Result Data Reflection: Not reflected
• XOR value: FFh
SAE makes no claim of the functional safety ...";
CM_ BO_ 2565991678 "Motor/Generator 3 Inverter Limits Active Mechanical
The Torque and Speed limits the inverter is actually using.  These may differ from the requested limits.";
CM_ SG_ 2565991678 SpdMin "The inverter keeps the motor Speed above this value.  This limit may be set in response to a Limits Request or determined by the inverter based on operating conditions.

Refer to SPN 11822 [Reference Speed] to convert % to rpm.";
CM_ SG_ 2565991678 SpdMax "The inverter keeps the motor speed below this value.  This limit may be set in response to a Limits Request or determined by the inverter based on operating conditions.

Refer to SPN 11822 [Reference Speed] to convert % to rpm.";
CM_ SG_ 2565991678 TrqMin "The inverter keeps the motor torque above this value.  This limit may be set in response to a Limits Request or determined by the inverter based on operating conditions.

Refer to SPN 11821 [Reference Torque] to convert % to Nm.";
CM_ SG_ 2565991678 TrqMax "The inverter keeps the motor torque below this value.  This limit may be set in response to a Limits Request or determined by the inverter based on operating conditions.

Refer to SPN 11821 [Reference Torque] to convert % to Nm.";
CM_ SG_ 2565991678 Counter "The message counter is used to detect situations where the transmitting ECU malfunction repeats the same frame all the time. The receiver of the information may use the counter parameter to detect this situation. The transmitting device will ...";
CM_ SG_ 2565991678 CRC "The CRC is defined as follows:
• Length: 8 bits
• Polynomial: x^8+x^5+x^3+x^2+x+1
• Initial Value: FFh
• Input Data Reflection: Not reflected
• Result Data Reflection: Not reflected
• XOR value: FFh
SAE makes no claim of the functional safety ...";
CM_ BO_ 2565991422 "Motor/Generator 3 Inverter Limits Active Power
The electrical and mechanical power limits the inverter is actually using.  These may differ from the requested limits.";
CM_ SG_ 2565991422 DCSidePwrMin "The inverter keeps the DC side power above this value.   This limit may be set in response to a Limits Request or determined by the inverter based on operating conditions.
Refer to SPN 11823 [Reference Power] to convert % to kW.
For example, in a ...";
CM_ SG_ 2565991422 DCSidePwrMax "The inverter keeps the DC Side power below this value.   This limit may be set in response to a Limits Request or determined by the inverter based on operating conditions.
Refer to SPN 11823 [Reference Power] to convert % to kW.
For example, in a ...";
CM_ SG_ 2565991422 MechPwrMin "The inverter keeps the mechanical motor power above this value.   This limit may be set in response to a Limits Request or determined by the inverter based on operating conditions.
Refer to SPN 11823 [Reference Power] to convert % to kW.
For ...";
CM_ SG_ 2565991422 MechPwrMax "The inverter keeps the mechanical motor power below this value.   This limit may be set in response to a Limits Request or determined by the inverter based on operating conditions.
Refer to SPN 11823 [Reference Power] to convert % to kW.
For ...";
CM_ SG_ 2565991422 Counter "The message counter is used to detect situations where the transmitting ECU malfunction repeats the same frame all the time. The receiver of the information may use the counter parameter to detect this situation. The transmitting device will ...";
CM_ SG_ 2565991422 CRC "The CRC is defined as follows:
• Length: 8 bits
• Polynomial: x^8+x^5+x^3+x^2+x+1
• Initial Value: FFh
• Input Data Reflection: Not reflected
• Result Data Reflection: Not reflected
• XOR value: FFh
SAE makes no claim of the functional safety ...";
CM_ BO_ 2364664574 "Motor/Generator 3 Inverter Mode Feedback 1
The first mode feedback message from the inverter.";
CM_ SG_ 2364664574 HVILStatus "Reports the High Voltage Interlock Loop (HVIL) state.

00b = HVIL Closed
01b = HVIL Open
10b = Error
11b = Not Available";
CM_ SG_ 2364664574 CtrlSetpointMode "Reports the inverter mode (See SPN 11813 [Control Setpoint Mode Request] for requested mode).
Passive modes:
0 = Powered On - the inverter is commanded to be powered on and able to communicate, but the Power Stage is disabled e.g. no switching or ...";
CM_ SG_ 2364664574 CtrlLimitsOvrdMode "During normal operation this will have the same value as SPN 11810 [Control Limits Request Override Mode].
0 = Operating limits are not overridden.  If a limit was previously active, then it has reverted to its normal value as defined by its ...";
CM_ SG_ 2364664574 Counter "The message counter is used to detect situations where the transmitting ECU malfunction repeats the same frame all the time. The receiver of the information may use the counter parameter to detect this situation. The transmitting device will ...";
CM_ SG_ 2364664574 CRC "The CRC is defined as follows:
• Length: 8 bits
• Polynomial: x^8+x^5+x^3+x^2+x+1
• Initial Value: FFh
• Input Data Reflection: Not reflected
• Result Data Reflection: Not reflected
• XOR value: FFh
SAE makes no claim of the functional safety ...";
CM_ BO_ 2364664318 "High Voltage Energy Storage Pack 6 Data 11
Data set 11 (electrical data) for High Voltage Energy Storage Pack 6.";
CM_ SG_ 2364664318 ActualChargeRate "This signal represents the actual present charge rate of this High Voltage Energy Storage Pack instance.
This parameter is for one of multiple packs in an HVESS. If there is only one pack in the system, the HVESS parameters should be used. If there ...";
CM_ SG_ 2364664318 LvlNegToChassisGroundV "Voltage difference between the most negative terminal of the HVES battery and chassis measured at the battery side of any HVES contained output contactor.  This voltage may be used for system level monitoring of battery shorts to chassis within the ...";
CM_ SG_ 2364664318 BusVNegToChassisGroundV "Voltage difference between the most negative terminal of the HVES battery and chassis measured on the hybrid system bus side (not the battery side) of any HVES contained output contactor.  This voltage may be used for system level monitoring of ...";
CM_ BO_ 2364664062 "High Voltage Energy Storage Pack 6 Data 10
Data set 10 (electrical) for High Voltage Energy Storage Pack 6.";
CM_ SG_ 2364664062 HVBusPassiveIsolTestResults "The isolation resistance expressed in Ohms per Volt that resulted from the High-Voltage Bus Passive Isolation Test.
See SPN 11661 (HVESP6 High-Voltage Bus Passive Isolation Test Status) for test status and SPN 11612 (HVESP6 High-Voltage Bus Passive ...";
CM_ SG_ 2364664062 HVBusActiveIsolTestResults "The isolation resistance expressed in Ohms per Volt that resulted from the High-Voltage Bus Active Isolation Test.
See SPN 11660 (HVESP6 High-Voltage Bus Active Isolation Test Status) for test status and SPN 11611 (HVESP6 High-Voltage Bus Active ...";
CM_ SG_ 2364664062 LowestCellStOfChargeCellNum "Identifies the location of SPN 11647 (HVESP6 Lowest Cell State of Charge) within SPN 11706 (HVESP6 Lowest Cell State of Charge Module Number).
This parameter is for one of multiple packs in an HVESS.  If there is only one pack in the system, the ...";
CM_ SG_ 2364664062 LowestCellStOfChargeModuleNum "Identifies the location of the module containing SPN 11647 (HVESP6 Lowest Cell State of Charge).
This parameter is for one of multiple packs in an HVESS.  If there is only one pack in the system, the HVESS parameters should be used. If there are ...";
CM_ SG_ 2364664062 HighestCellStOfChargeCellNum "Identifies the location of SPN 11648 (HVESP6 Highest Cell State of Charge) within SPN 11704 (HVESP6 Highest Cell State of Charge Module Number).
This parameter is for one of multiple packs in an HVESS.  If there is only one pack in the system, the ...";
CM_ SG_ 2364664062 HighestCellStOfChargeModuleNum "Identifies the location of the module containing SPN 11648 (HVESP6 Highest Cell State of Charge).
This parameter is for one of multiple packs in an HVESS.  If there is only one pack in the system, the HVESS parameters should be used. If there are ...";
BA_DEF_ SG_  "GenSigInactiveValue" INT 0 0;
BA_DEF_ SG_  "SigType" ENUM  "Default","Range","RangeSigned","ASCII","Discrete","Control","ReferencePGN","DTC","StringDelimiter","StringLength","StringLengthControl","MessageCounter","MessageChecksum";
BA_DEF_ SG_  "GenSigStartValue" INT 0 2147483647;
BA_DEF_ SG_  "GenSigSendType" ENUM  "Cyclic","OnWrite","OnWriteWithRepetition","OnChange","OnChangeWithRepetition","IfActive","IfActiveWithRepetition","NoSigSendType";
BA_DEF_ SG_  "GenSigILSupport" ENUM  "No","Yes";
BA_DEF_ SG_  "SPN" INT 0 524287;
BA_DEF_ BO_  "J1939CPgSendTimeout" INT -1 3600000;
BA_DEF_ BO_  "J1939CPgTOS" INT 0 7;
BA_DEF_ BO_  "J1939PgAppearanceOnBus" ENUM  "Default","CAN_Extended","CANFD_Extended";
BA_DEF_ BO_  "FsJ1939UseCrcAndCounter" STRING ;
BA_DEF_ BO_  "TpJ1939VarDlc" ENUM  "No","Yes";
BA_DEF_ BO_  "GenMsgNrOfRepetition" INT 0 1000000;
BA_DEF_ BO_  "GenMsgCycleTimeFast" INT 0 3600000;
BA_DEF_ BO_  "GenMsgFastOnStart" INT 0 100000;
BA_DEF_ BO_  "GenMsgStartDelayTime" INT 0 100000;
BA_DEF_ BO_  "GenMsgILSupport" ENUM  "No","Yes";
BA_DEF_ BO_  "GenMsgDelayTime" INT 0 1000;
BA_DEF_ BO_  "GenMsgRequestable" INT 0 1;
BA_DEF_ BO_  "GenMsgSendType" ENUM  "cyclic","NotUsed","NotUsed","NotUsed","NotUsed","NotUsed","NotUsed","IfActive","noMsgSendType";
BA_DEF_ BO_  "VFrameFormat" ENUM  "StandardCAN","ExtendedCAN","reserved","J1939PG","reserved","reserved","reserved","reserved","reserved","reserved","reserved","reserved","reserved","reserved","StandardCAN_FD","ExtendedCAN_FD";
BA_DEF_ BO_  "SingleFrame" INT 0 1;
BA_DEF_ BO_  "GenMsgCycleTime" INT 0 3600000;
BA_DEF_ SG_  "SystemSignalLongSymbol" STRING ;
BA_DEF_DEF_  "GenSigInactiveValue" 0;
BA_DEF_DEF_  "SigType" "Default";
BA_DEF_DEF_  "GenSigStartValue" 0;
BA_DEF_DEF_  "GenSigSendType" "NoSigSendType";
BA_DEF_DEF_  "GenSigILSupport" "Yes";
BA_DEF_DEF_  "SPN" 0;
BA_DEF_DEF_  "J1939CPgSendTimeout" -1;
BA_DEF_DEF_  "J1939CPgTOS" 2;
BA_DEF_DEF_  "J1939PgAppearanceOnBus" "Default";
BA_DEF_DEF_  "FsJ1939UseCrcAndCounter" "";
BA_DEF_DEF_  "TpJ1939VarDlc" "No";
BA_DEF_DEF_  "GenMsgNrOfRepetition" 0;
BA_DEF_DEF_  "GenMsgCycleTimeFast" 0;
BA_DEF_DEF_  "GenMsgFastOnStart" 0;
BA_DEF_DEF_  "GenMsgStartDelayTime" 0;
BA_DEF_DEF_  "GenMsgILSupport" "Yes";
BA_DEF_DEF_  "GenMsgDelayTime" 0;
BA_DEF_DEF_  "GenMsgRequestable" 1;
BA_DEF_DEF_  "GenMsgSendType" "noMsgSendType";
BA_DEF_DEF_  "VFrameFormat" "J1939PG";
BA_DEF_DEF_  "SingleFrame" 1;
BA_DEF_DEF_  "GenMsgCycleTime" 0;
BA_DEF_DEF_  "SystemSignalLongSymbol" "";
BA_ "TpJ1939VarDlc" BO_ 2566586878 1;
BA_ "TpJ1939VarDlc" BO_ 2566586622 1;
BA_ "TpJ1939VarDlc" BO_ 2566586366 1;
BA_ "GenMsgSendType" BO_ 2566582014 0;
BA_ "GenMsgCycleTime" BO_ 2566582014 1000;
BA_ "GenMsgSendType" BO_ 2566581758 0;
BA_ "GenMsgCycleTime" BO_ 2566581758 1000;
BA_ "FsJ1939UseCrcAndCounter" BO_ 2566000638 "Bc";
BA_ "GenMsgSendType" BO_ 2566000638 0;
BA_ "GenMsgCycleTime" BO_ 2566000638 100;
BA_ "FsJ1939UseCrcAndCounter" BO_ 2364673790 "Bc";
BA_ "GenMsgSendType" BO_ 2364673790 0;
BA_ "GenMsgCycleTime" BO_ 2364673790 10;
BA_ "FsJ1939UseCrcAndCounter" BO_ 2566000126 "Bc";
BA_ "GenMsgSendType" BO_ 2566000126 0;
BA_ "GenMsgCycleTime" BO_ 2566000126 100;
BA_ "FsJ1939UseCrcAndCounter" BO_ 2364673278 "Bc";
BA_ "GenMsgSendType" BO_ 2364673278 0;
BA_ "GenMsgCycleTime" BO_ 2364673278 10;
BA_ "FsJ1939UseCrcAndCounter" BO_ 2565999614 "Bc";
BA_ "GenMsgSendType" BO_ 2565999614 0;
BA_ "GenMsgCycleTime" BO_ 2565999614 100;
BA_ "FsJ1939UseCrcAndCounter" BO_ 2364672766 "Bc";
BA_ "GenMsgSendType" BO_ 2364672766 0;
BA_ "GenMsgCycleTime" BO_ 2364672766 10;
BA_ "FsJ1939UseCrcAndCounter" BO_ 2565999102 "Bc";
BA_ "GenMsgSendType" BO_ 2565999102 0;
BA_ "GenMsgCycleTime" BO_ 2565999102 100;
BA_ "FsJ1939UseCrcAndCounter" BO_ 2364672254 "Bc";
BA_ "GenMsgSendType" BO_ 2364672254 0;
BA_ "GenMsgCycleTime" BO_ 2364672254 10;
BA_ "GenMsgSendType" BO_ 2364671998 0;
BA_ "GenMsgCycleTime" BO_ 2364671998 20;
BA_ "GenMsgDelayTime" BO_ 2364671742 10;
BA_ "GenMsgSendType" BO_ 2364671742 0;
BA_ "GenMsgCycleTime" BO_ 2364671742 50;
BA_ "FsJ1939UseCrcAndCounter" BO_ 2565998078 "Bc";
BA_ "GenMsgSendType" BO_ 2565998078 0;
BA_ "GenMsgCycleTime" BO_ 2565998078 100;
BA_ "FsJ1939UseCrcAndCounter" BO_ 2565997822 "Bc";
BA_ "GenMsgSendType" BO_ 2565997822 0;
BA_ "GenMsgCycleTime" BO_ 2565997822 100;
BA_ "GenMsgSendType" BO_ 2565997566 0;
BA_ "GenMsgCycleTime" BO_ 2565997566 100;
BA_ "FsJ1939UseCrcAndCounter" BO_ 2565997310 "Bc";
BA_ "GenMsgSendType" BO_ 2565997310 0;
BA_ "GenMsgCycleTime" BO_ 2565997310 100;
BA_ "FsJ1939UseCrcAndCounter" BO_ 2565997054 "Bc";
BA_ "GenMsgSendType" BO_ 2565997054 0;
BA_ "GenMsgCycleTime" BO_ 2565997054 100;
BA_ "FsJ1939UseCrcAndCounter" BO_ 2565996798 "Bc";
BA_ "GenMsgSendType" BO_ 2565996798 0;
BA_ "GenMsgCycleTime" BO_ 2565996798 100;
BA_ "FsJ1939UseCrcAndCounter" BO_ 2364669950 "Bc";
BA_ "GenMsgSendType" BO_ 2364669950 0;
BA_ "GenMsgCycleTime" BO_ 2364669950 100;
BA_ "FsJ1939UseCrcAndCounter" BO_ 2565996286 "Bc";
BA_ "GenMsgSendType" BO_ 2565996286 0;
BA_ "GenMsgCycleTime" BO_ 2565996286 100;
BA_ "FsJ1939UseCrcAndCounter" BO_ 2565996030 "Bc";
BA_ "GenMsgSendType" BO_ 2565996030 0;
BA_ "GenMsgCycleTime" BO_ 2565996030 100;
BA_ "GenMsgSendType" BO_ 2565995774 0;
BA_ "GenMsgCycleTime" BO_ 2565995774 100;
BA_ "FsJ1939UseCrcAndCounter" BO_ 2565995518 "Bc";
BA_ "GenMsgSendType" BO_ 2565995518 0;
BA_ "GenMsgCycleTime" BO_ 2565995518 100;
BA_ "FsJ1939UseCrcAndCounter" BO_ 2565995262 "Bc";
BA_ "GenMsgSendType" BO_ 2565995262 0;
BA_ "GenMsgCycleTime" BO_ 2565995262 100;
BA_ "FsJ1939UseCrcAndCounter" BO_ 2565995006 "Bc";
BA_ "GenMsgSendType" BO_ 2565995006 0;
BA_ "GenMsgCycleTime" BO_ 2565995006 100;
BA_ "FsJ1939UseCrcAndCounter" BO_ 2364668158 "Bc";
BA_ "GenMsgSendType" BO_ 2364668158 0;
BA_ "GenMsgCycleTime" BO_ 2364668158 100;
BA_ "FsJ1939UseCrcAndCounter" BO_ 2565994494 "Bc";
BA_ "GenMsgSendType" BO_ 2565994494 0;
BA_ "GenMsgCycleTime" BO_ 2565994494 100;
BA_ "FsJ1939UseCrcAndCounter" BO_ 2565994238 "Bc";
BA_ "GenMsgSendType" BO_ 2565994238 0;
BA_ "GenMsgCycleTime" BO_ 2565994238 100;
BA_ "GenMsgSendType" BO_ 2565993982 0;
BA_ "GenMsgCycleTime" BO_ 2565993982 100;
BA_ "FsJ1939UseCrcAndCounter" BO_ 2565993726 "Bc";
BA_ "GenMsgSendType" BO_ 2565993726 0;
BA_ "GenMsgCycleTime" BO_ 2565993726 100;
BA_ "FsJ1939UseCrcAndCounter" BO_ 2565993470 "Bc";
BA_ "GenMsgSendType" BO_ 2565993470 0;
BA_ "GenMsgCycleTime" BO_ 2565993470 100;
BA_ "FsJ1939UseCrcAndCounter" BO_ 2565993214 "Bc";
BA_ "GenMsgSendType" BO_ 2565993214 0;
BA_ "GenMsgCycleTime" BO_ 2565993214 100;
BA_ "FsJ1939UseCrcAndCounter" BO_ 2364666366 "Bc";
BA_ "GenMsgSendType" BO_ 2364666366 0;
BA_ "GenMsgCycleTime" BO_ 2364666366 100;
BA_ "FsJ1939UseCrcAndCounter" BO_ 2565992702 "Bc";
BA_ "GenMsgSendType" BO_ 2565992702 0;
BA_ "GenMsgCycleTime" BO_ 2565992702 100;
BA_ "FsJ1939UseCrcAndCounter" BO_ 2565992446 "Bc";
BA_ "GenMsgSendType" BO_ 2565992446 0;
BA_ "GenMsgCycleTime" BO_ 2565992446 100;
BA_ "GenMsgSendType" BO_ 2565992190 0;
BA_ "GenMsgCycleTime" BO_ 2565992190 100;
BA_ "FsJ1939UseCrcAndCounter" BO_ 2565991934 "Bc";
BA_ "GenMsgSendType" BO_ 2565991934 0;
BA_ "GenMsgCycleTime" BO_ 2565991934 100;
BA_ "FsJ1939UseCrcAndCounter" BO_ 2565991678 "Bc";
BA_ "GenMsgSendType" BO_ 2565991678 0;
BA_ "GenMsgCycleTime" BO_ 2565991678 100;
BA_ "FsJ1939UseCrcAndCounter" BO_ 2565991422 "Bc";
BA_ "GenMsgSendType" BO_ 2565991422 0;
BA_ "GenMsgCycleTime" BO_ 2565991422 100;
BA_ "FsJ1939UseCrcAndCounter" BO_ 2364664574 "Bc";
BA_ "GenMsgSendType" BO_ 2364664574 0;
BA_ "GenMsgCycleTime" BO_ 2364664574 100;
BA_ "GenMsgSendType" BO_ 2364664318 0;
BA_ "GenMsgCycleTime" BO_ 2364664318 100;
BA_ "GenMsgSendType" BO_ 2364664062 0;
BA_ "GenMsgCycleTime" BO_ 2364664062 100;
BA_ "SigType" SG_ 2566588926 Bin17 1;
BA_ "SPN" SG_ 2566588926 Bin17 12575;
BA_ "SigType" SG_ 2566588926 Bin16 1;
BA_ "SPN" SG_ 2566588926 Bin16 12574;
BA_ "SigType" SG_ 2566588926 Bin15 1;
BA_ "SPN" SG_ 2566588926 Bin15 12573;
BA_ "SigType" SG_ 2566588926 Bin14 1;
BA_ "SPN" SG_ 2566588926 Bin14 12572;
BA_ "SigType" SG_ 2566588926 Bin13 1;
BA_ "SPN" SG_ 2566588926 Bin13 12571;
BA_ "SigType" SG_ 2566588926 Bin12 1;
BA_ "SPN" SG_ 2566588926 Bin12 12570;
BA_ "SigType" SG_ 2566588926 Bin11 1;
BA_ "SPN" SG_ 2566588926 Bin11 12569;
BA_ "SigType" SG_ 2566588926 Bin10 1;
BA_ "SPN" SG_ 2566588926 Bin10 12568;
BA_ "SigType" SG_ 2566588926 Bin9 1;
BA_ "SPN" SG_ 2566588926 Bin9 12567;
BA_ "SigType" SG_ 2566588926 Bin8 1;
BA_ "SPN" SG_ 2566588926 Bin8 12566;
BA_ "SigType" SG_ 2566588926 Bin7 1;
BA_ "SPN" SG_ 2566588926 Bin7 12565;
BA_ "SigType" SG_ 2566588926 Bin6 1;
BA_ "SPN" SG_ 2566588926 Bin6 12564;
BA_ "SigType" SG_ 2566588926 Bin5 1;
BA_ "SPN" SG_ 2566588926 Bin5 12563;
BA_ "SigType" SG_ 2566588926 Bin4 1;
BA_ "SPN" SG_ 2566588926 Bin4 12562;
BA_ "SigType" SG_ 2566588926 Bin3 1;
BA_ "SPN" SG_ 2566588926 Bin3 12561;
BA_ "SigType" SG_ 2566588926 Bin2 1;
BA_ "SPN" SG_ 2566588926 Bin2 12560;
BA_ "SigType" SG_ 2566588926 Bin1 1;
BA_ "SPN" SG_ 2566588926 Bin1 12559;
BA_ "SigType" SG_ 2566588670 Bin17 1;
BA_ "SPN" SG_ 2566588670 Bin17 12592;
BA_ "SigType" SG_ 2566588670 Bin16 1;
BA_ "SPN" SG_ 2566588670 Bin16 12591;
BA_ "SigType" SG_ 2566588670 Bin15 1;
BA_ "SPN" SG_ 2566588670 Bin15 12590;
BA_ "SigType" SG_ 2566588670 Bin14 1;
BA_ "SPN" SG_ 2566588670 Bin14 12589;
BA_ "SigType" SG_ 2566588670 Bin13 1;
BA_ "SPN" SG_ 2566588670 Bin13 12588;
BA_ "SigType" SG_ 2566588670 Bin12 1;
BA_ "SPN" SG_ 2566588670 Bin12 12587;
BA_ "SigType" SG_ 2566588670 Bin11 1;
BA_ "SPN" SG_ 2566588670 Bin11 12586;
BA_ "SigType" SG_ 2566588670 Bin10 1;
BA_ "SPN" SG_ 2566588670 Bin10 12585;
BA_ "SigType" SG_ 2566588670 Bin9 1;
BA_ "SPN" SG_ 2566588670 Bin9 12584;
BA_ "SigType" SG_ 2566588670 Bin8 1;
BA_ "SPN" SG_ 2566588670 Bin8 12583;
BA_ "SigType" SG_ 2566588670 Bin7 1;
BA_ "SPN" SG_ 2566588670 Bin7 12582;
BA_ "SigType" SG_ 2566588670 Bin6 1;
BA_ "SPN" SG_ 2566588670 Bin6 12581;
BA_ "SigType" SG_ 2566588670 Bin5 1;
BA_ "SPN" SG_ 2566588670 Bin5 12580;
BA_ "SigType" SG_ 2566588670 Bin4 1;
BA_ "SPN" SG_ 2566588670 Bin4 12579;
BA_ "SigType" SG_ 2566588670 Bin3 1;
BA_ "SPN" SG_ 2566588670 Bin3 12578;
BA_ "SigType" SG_ 2566588670 Bin2 1;
BA_ "SPN" SG_ 2566588670 Bin2 12577;
BA_ "SigType" SG_ 2566588670 Bin1 1;
BA_ "SPN" SG_ 2566588670 Bin1 12576;
BA_ "SigType" SG_ 2566588414 Bin17 1;
BA_ "SPN" SG_ 2566588414 Bin17 12609;
BA_ "SigType" SG_ 2566588414 Bin16 1;
BA_ "SPN" SG_ 2566588414 Bin16 12608;
BA_ "SigType" SG_ 2566588414 Bin15 1;
BA_ "SPN" SG_ 2566588414 Bin15 12607;
BA_ "SigType" SG_ 2566588414 Bin14 1;
BA_ "SPN" SG_ 2566588414 Bin14 12606;
BA_ "SigType" SG_ 2566588414 Bin13 1;
BA_ "SPN" SG_ 2566588414 Bin13 12605;
BA_ "SigType" SG_ 2566588414 Bin12 1;
BA_ "SPN" SG_ 2566588414 Bin12 12604;
BA_ "SigType" SG_ 2566588414 Bin11 1;
BA_ "SPN" SG_ 2566588414 Bin11 12603;
BA_ "SigType" SG_ 2566588414 Bin10 1;
BA_ "SPN" SG_ 2566588414 Bin10 12602;
BA_ "SigType" SG_ 2566588414 Bin9 1;
BA_ "SPN" SG_ 2566588414 Bin9 12601;
BA_ "SigType" SG_ 2566588414 Bin8 1;
BA_ "SPN" SG_ 2566588414 Bin8 12600;
BA_ "SigType" SG_ 2566588414 Bin7 1;
BA_ "SPN" SG_ 2566588414 Bin7 12599;
BA_ "SigType" SG_ 2566588414 Bin6 1;
BA_ "SPN" SG_ 2566588414 Bin6 12598;
BA_ "SigType" SG_ 2566588414 Bin5 1;
BA_ "SPN" SG_ 2566588414 Bin5 12597;
BA_ "SigType" SG_ 2566588414 Bin4 1;
BA_ "SPN" SG_ 2566588414 Bin4 12596;
BA_ "SigType" SG_ 2566588414 Bin3 1;
BA_ "SPN" SG_ 2566588414 Bin3 12595;
BA_ "SigType" SG_ 2566588414 Bin2 1;
BA_ "SPN" SG_ 2566588414 Bin2 12594;
BA_ "SigType" SG_ 2566588414 Bin1 1;
BA_ "SPN" SG_ 2566588414 Bin1 12593;
BA_ "SigType" SG_ 2566588158 Bin17 1;
BA_ "SPN" SG_ 2566588158 Bin17 12626;
BA_ "SigType" SG_ 2566588158 Bin16 1;
BA_ "SPN" SG_ 2566588158 Bin16 12625;
BA_ "SigType" SG_ 2566588158 Bin15 1;
BA_ "SPN" SG_ 2566588158 Bin15 12624;
BA_ "SigType" SG_ 2566588158 Bin14 1;
BA_ "SPN" SG_ 2566588158 Bin14 12623;
BA_ "SigType" SG_ 2566588158 Bin13 1;
BA_ "SPN" SG_ 2566588158 Bin13 12622;
BA_ "SigType" SG_ 2566588158 Bin12 1;
BA_ "SPN" SG_ 2566588158 Bin12 12621;
BA_ "SigType" SG_ 2566588158 Bin11 1;
BA_ "SPN" SG_ 2566588158 Bin11 12620;
BA_ "SigType" SG_ 2566588158 Bin10 1;
BA_ "SPN" SG_ 2566588158 Bin10 12619;
BA_ "SigType" SG_ 2566588158 Bin9 1;
BA_ "SPN" SG_ 2566588158 Bin9 12618;
BA_ "SigType" SG_ 2566588158 Bin8 1;
BA_ "SPN" SG_ 2566588158 Bin8 12617;
BA_ "SigType" SG_ 2566588158 Bin7 1;
BA_ "SPN" SG_ 2566588158 Bin7 12616;
BA_ "SigType" SG_ 2566588158 Bin6 1;
BA_ "SPN" SG_ 2566588158 Bin6 12615;
BA_ "SigType" SG_ 2566588158 Bin5 1;
BA_ "SPN" SG_ 2566588158 Bin5 12614;
BA_ "SigType" SG_ 2566588158 Bin4 1;
BA_ "SPN" SG_ 2566588158 Bin4 12613;
BA_ "SigType" SG_ 2566588158 Bin3 1;
BA_ "SPN" SG_ 2566588158 Bin3 12612;
BA_ "SigType" SG_ 2566588158 Bin2 1;
BA_ "SPN" SG_ 2566588158 Bin2 12611;
BA_ "SigType" SG_ 2566588158 Bin1 1;
BA_ "SPN" SG_ 2566588158 Bin1 12610;
BA_ "SigType" SG_ 2566587902 Bin17 1;
BA_ "SPN" SG_ 2566587902 Bin17 12729;
BA_ "SigType" SG_ 2566587902 Bin16 1;
BA_ "SPN" SG_ 2566587902 Bin16 12642;
BA_ "SigType" SG_ 2566587902 Bin15 1;
BA_ "SPN" SG_ 2566587902 Bin15 12641;
BA_ "SigType" SG_ 2566587902 Bin14 1;
BA_ "SPN" SG_ 2566587902 Bin14 12640;
BA_ "SigType" SG_ 2566587902 Bin13 1;
BA_ "SPN" SG_ 2566587902 Bin13 12639;
BA_ "SigType" SG_ 2566587902 Bin12 1;
BA_ "SPN" SG_ 2566587902 Bin12 12638;
BA_ "SigType" SG_ 2566587902 Bin11 1;
BA_ "SPN" SG_ 2566587902 Bin11 12637;
BA_ "SigType" SG_ 2566587902 Bin10 1;
BA_ "SPN" SG_ 2566587902 Bin10 12636;
BA_ "SigType" SG_ 2566587902 Bin9 1;
BA_ "SPN" SG_ 2566587902 Bin9 12635;
BA_ "SigType" SG_ 2566587902 Bin8 1;
BA_ "SPN" SG_ 2566587902 Bin8 12634;
BA_ "SigType" SG_ 2566587902 Bin7 1;
BA_ "SPN" SG_ 2566587902 Bin7 12633;
BA_ "SigType" SG_ 2566587902 Bin6 1;
BA_ "SPN" SG_ 2566587902 Bin6 12632;
BA_ "SigType" SG_ 2566587902 Bin5 1;
BA_ "SPN" SG_ 2566587902 Bin5 12631;
BA_ "SigType" SG_ 2566587902 Bin4 1;
BA_ "SPN" SG_ 2566587902 Bin4 12630;
BA_ "SigType" SG_ 2566587902 Bin3 1;
BA_ "SPN" SG_ 2566587902 Bin3 12629;
BA_ "SigType" SG_ 2566587902 Bin2 1;
BA_ "SPN" SG_ 2566587902 Bin2 12628;
BA_ "SigType" SG_ 2566587902 Bin1 1;
BA_ "SPN" SG_ 2566587902 Bin1 12627;
BA_ "SigType" SG_ 2566587646 Bin17 1;
BA_ "SPN" SG_ 2566587646 Bin17 12728;
BA_ "SigType" SG_ 2566587646 Bin16 1;
BA_ "SPN" SG_ 2566587646 Bin16 12658;
BA_ "SigType" SG_ 2566587646 Bin15 1;
BA_ "SPN" SG_ 2566587646 Bin15 12657;
BA_ "SigType" SG_ 2566587646 Bin14 1;
BA_ "SPN" SG_ 2566587646 Bin14 12656;
BA_ "SigType" SG_ 2566587646 Bin13 1;
BA_ "SPN" SG_ 2566587646 Bin13 12655;
BA_ "SigType" SG_ 2566587646 Bin12 1;
BA_ "SPN" SG_ 2566587646 Bin12 12654;
BA_ "SigType" SG_ 2566587646 Bin11 1;
BA_ "SPN" SG_ 2566587646 Bin11 12653;
BA_ "SigType" SG_ 2566587646 Bin10 1;
BA_ "SPN" SG_ 2566587646 Bin10 12652;
BA_ "SigType" SG_ 2566587646 Bin9 1;
BA_ "SPN" SG_ 2566587646 Bin9 12651;
BA_ "SigType" SG_ 2566587646 Bin8 1;
BA_ "SPN" SG_ 2566587646 Bin8 12650;
BA_ "SigType" SG_ 2566587646 Bin7 1;
BA_ "SPN" SG_ 2566587646 Bin7 12649;
BA_ "SigType" SG_ 2566587646 Bin6 1;
BA_ "SPN" SG_ 2566587646 Bin6 12648;
BA_ "SigType" SG_ 2566587646 Bin5 1;
BA_ "SPN" SG_ 2566587646 Bin5 12647;
BA_ "SigType" SG_ 2566587646 Bin4 1;
BA_ "SPN" SG_ 2566587646 Bin4 12646;
BA_ "SigType" SG_ 2566587646 Bin3 1;
BA_ "SPN" SG_ 2566587646 Bin3 12645;
BA_ "SigType" SG_ 2566587646 Bin2 1;
BA_ "SPN" SG_ 2566587646 Bin2 12644;
BA_ "SigType" SG_ 2566587646 Bin1 1;
BA_ "SPN" SG_ 2566587646 Bin1 12643;
BA_ "SigType" SG_ 2566587390 Bin17 1;
BA_ "SPN" SG_ 2566587390 Bin17 12714;
BA_ "SigType" SG_ 2566587390 Bin16 1;
BA_ "SPN" SG_ 2566587390 Bin16 12674;
BA_ "SigType" SG_ 2566587390 Bin15 1;
BA_ "SPN" SG_ 2566587390 Bin15 12673;
BA_ "SigType" SG_ 2566587390 Bin14 1;
BA_ "SPN" SG_ 2566587390 Bin14 12672;
BA_ "SigType" SG_ 2566587390 Bin13 1;
BA_ "SPN" SG_ 2566587390 Bin13 12671;
BA_ "SigType" SG_ 2566587390 Bin12 1;
BA_ "SPN" SG_ 2566587390 Bin12 12670;
BA_ "SigType" SG_ 2566587390 Bin11 1;
BA_ "SPN" SG_ 2566587390 Bin11 12669;
BA_ "SigType" SG_ 2566587390 Bin10 1;
BA_ "SPN" SG_ 2566587390 Bin10 12668;
BA_ "SigType" SG_ 2566587390 Bin9 1;
BA_ "SPN" SG_ 2566587390 Bin9 12667;
BA_ "SigType" SG_ 2566587390 Bin8 1;
BA_ "SPN" SG_ 2566587390 Bin8 12666;
BA_ "SigType" SG_ 2566587390 Bin7 1;
BA_ "SPN" SG_ 2566587390 Bin7 12665;
BA_ "SigType" SG_ 2566587390 Bin6 1;
BA_ "SPN" SG_ 2566587390 Bin6 12664;
BA_ "SigType" SG_ 2566587390 Bin5 1;
BA_ "SPN" SG_ 2566587390 Bin5 12663;
BA_ "SigType" SG_ 2566587390 Bin4 1;
BA_ "SPN" SG_ 2566587390 Bin4 12662;
BA_ "SigType" SG_ 2566587390 Bin3 1;
BA_ "SPN" SG_ 2566587390 Bin3 12661;
BA_ "SigType" SG_ 2566587390 Bin2 1;
BA_ "SPN" SG_ 2566587390 Bin2 12660;
BA_ "SigType" SG_ 2566587390 Bin1 1;
BA_ "SPN" SG_ 2566587390 Bin1 12659;
BA_ "SigType" SG_ 2566587134 Bin17 1;
BA_ "SPN" SG_ 2566587134 Bin17 12713;
BA_ "SigType" SG_ 2566587134 Bin16 1;
BA_ "SPN" SG_ 2566587134 Bin16 12690;
BA_ "SigType" SG_ 2566587134 Bin15 1;
BA_ "SPN" SG_ 2566587134 Bin15 12689;
BA_ "SigType" SG_ 2566587134 Bin14 1;
BA_ "SPN" SG_ 2566587134 Bin14 12688;
BA_ "SigType" SG_ 2566587134 Bin13 1;
BA_ "SPN" SG_ 2566587134 Bin13 12687;
BA_ "SigType" SG_ 2566587134 Bin12 1;
BA_ "SPN" SG_ 2566587134 Bin12 12686;
BA_ "SigType" SG_ 2566587134 Bin11 1;
BA_ "SPN" SG_ 2566587134 Bin11 12685;
BA_ "SigType" SG_ 2566587134 Bin10 1;
BA_ "SPN" SG_ 2566587134 Bin10 12684;
BA_ "SigType" SG_ 2566587134 Bin9 1;
BA_ "SPN" SG_ 2566587134 Bin9 12683;
BA_ "SigType" SG_ 2566587134 Bin8 1;
BA_ "SPN" SG_ 2566587134 Bin8 12682;
BA_ "SigType" SG_ 2566587134 Bin7 1;
BA_ "SPN" SG_ 2566587134 Bin7 12681;
BA_ "SigType" SG_ 2566587134 Bin6 1;
BA_ "SPN" SG_ 2566587134 Bin6 12680;
BA_ "SigType" SG_ 2566587134 Bin5 1;
BA_ "SPN" SG_ 2566587134 Bin5 12679;
BA_ "SigType" SG_ 2566587134 Bin4 1;
BA_ "SPN" SG_ 2566587134 Bin4 12678;
BA_ "SigType" SG_ 2566587134 Bin3 1;
BA_ "SPN" SG_ 2566587134 Bin3 12677;
BA_ "SigType" SG_ 2566587134 Bin2 1;
BA_ "SPN" SG_ 2566587134 Bin2 12676;
BA_ "SigType" SG_ 2566587134 Bin1 1;
BA_ "SPN" SG_ 2566587134 Bin1 12675;
BA_ "SigType" SG_ 2566586878 GHGTrackingActiveTechVehDist 1;
BA_ "SPN" SG_ 2566586878 GHGTrackingActiveTechVehDist 12693;
BA_ "SigType" SG_ 2566586878 GHGTrackingActiveTechTime 1;
BA_ "SPN" SG_ 2566586878 GHGTrackingActiveTechTime 12692;
BA_ "SPN" SG_ 2566586878 GHGTrackingActiveTechIndex 12691;
BA_ "SigType" SG_ 2566586622 GHGTrackingActiveTechVehDist 1;
BA_ "SPN" SG_ 2566586622 GHGTrackingActiveTechVehDist 12696;
BA_ "SigType" SG_ 2566586622 GHGTrackingActiveTechTime 1;
BA_ "SPN" SG_ 2566586622 GHGTrackingActiveTechTime 12695;
BA_ "SPN" SG_ 2566586622 GHGTrackingActiveTechIndex 12694;
BA_ "SigType" SG_ 2566586366 GHGTrackingActiveTechVehDist 1;
BA_ "SPN" SG_ 2566586366 GHGTrackingActiveTechVehDist 12699;
BA_ "SigType" SG_ 2566586366 GHGTrackingActiveTechTime 1;
BA_ "SPN" SG_ 2566586366 GHGTrackingActiveTechTime 12698;
BA_ "SPN" SG_ 2566586366 GHGTrackingActiveTechIndex 12697;
BA_ "SigType" SG_ 2566586110 StopStartTechRunTime 1;
BA_ "SPN" SG_ 2566586110 StopStartTechRunTime 12712;
BA_ "SigType" SG_ 2566586110 AutoEngShutdownTechActCount 1;
BA_ "SPN" SG_ 2566586110 AutoEngShutdownTechActCount 12711;
BA_ "SigType" SG_ 2566586110 EngPwrTakeOffFuelConsumption 1;
BA_ "SPN" SG_ 2566586110 EngPwrTakeOffFuelConsumption 12710;
BA_ "SigType" SG_ 2566586110 EngPwrTakeOffRunTime 1;
BA_ "SPN" SG_ 2566586110 EngPwrTakeOffRunTime 12709;
BA_ "SigType" SG_ 2566586110 EngIdleFuelConsumption 1;
BA_ "SPN" SG_ 2566586110 EngIdleFuelConsumption 12708;
BA_ "SigType" SG_ 2566586110 IdleRunTime 1;
BA_ "SPN" SG_ 2566586110 IdleRunTime 12707;
BA_ "SigType" SG_ 2566586110 UrbanSpdRunTime 1;
BA_ "SPN" SG_ 2566586110 UrbanSpdRunTime 12706;
BA_ "SigType" SG_ 2566586110 PosKineticEnergyNumerator 1;
BA_ "SPN" SG_ 2566586110 PosKineticEnergyNumerator 12705;
BA_ "SigType" SG_ 2566586110 EngOutEnergy 1;
BA_ "SPN" SG_ 2566586110 EngOutEnergy 12704;
BA_ "SigType" SG_ 2566586110 EngFuelConsumption 1;
BA_ "SPN" SG_ 2566586110 EngFuelConsumption 12703;
BA_ "SigType" SG_ 2566586110 VehFuelConsumption 1;
BA_ "SPN" SG_ 2566586110 VehFuelConsumption 12702;
BA_ "SigType" SG_ 2566586110 VehDist 1;
BA_ "SPN" SG_ 2566586110 VehDist 12701;
BA_ "SigType" SG_ 2566586110 EngRunTime 1;
BA_ "SPN" SG_ 2566586110 EngRunTime 12700;
BA_ "SigType" SG_ 2566585854 StopStartTechRunTime 1;
BA_ "SPN" SG_ 2566585854 StopStartTechRunTime 12727;
BA_ "SigType" SG_ 2566585854 AutoEngShutdownTechActCount 1;
BA_ "SPN" SG_ 2566585854 AutoEngShutdownTechActCount 12726;
BA_ "SigType" SG_ 2566585854 EngPwrTakeOffFuelConsumption 1;
BA_ "SPN" SG_ 2566585854 EngPwrTakeOffFuelConsumption 12725;
BA_ "SigType" SG_ 2566585854 EngPwrTakeOffRunTime 1;
BA_ "SPN" SG_ 2566585854 EngPwrTakeOffRunTime 12724;
BA_ "SigType" SG_ 2566585854 EngIdleFuelConsumption 1;
BA_ "SPN" SG_ 2566585854 EngIdleFuelConsumption 12723;
BA_ "SigType" SG_ 2566585854 IdleRunTime 1;
BA_ "SPN" SG_ 2566585854 IdleRunTime 12722;
BA_ "SigType" SG_ 2566585854 UrbanSpdRunTime 1;
BA_ "SPN" SG_ 2566585854 UrbanSpdRunTime 12721;
BA_ "SigType" SG_ 2566585854 PosKineticEnergyNumerator 1;
BA_ "SPN" SG_ 2566585854 PosKineticEnergyNumerator 12720;
BA_ "SigType" SG_ 2566585854 EngOutEnergy 1;
BA_ "SPN" SG_ 2566585854 EngOutEnergy 12719;
BA_ "SigType" SG_ 2566585854 EngFuelConsumption 1;
BA_ "SPN" SG_ 2566585854 EngFuelConsumption 12718;
BA_ "SigType" SG_ 2566585854 VehFuelConsumption 1;
BA_ "SPN" SG_ 2566585854 VehFuelConsumption 12717;
BA_ "SigType" SG_ 2566585854 VehDist 1;
BA_ "SPN" SG_ 2566585854 VehDist 12716;
BA_ "SigType" SG_ 2566585854 EngRunTime 1;
BA_ "SPN" SG_ 2566585854 EngRunTime 12715;
BA_ "SigType" SG_ 2566585598 StopStartTechRunTime 1;
BA_ "SPN" SG_ 2566585598 StopStartTechRunTime 12742;
BA_ "SPN" SG_ 2566585598 AutoEngShutdownTechActCount 12741;
BA_ "SigType" SG_ 2566585598 EngPwrTakeOffFuelConsumption 1;
BA_ "SPN" SG_ 2566585598 EngPwrTakeOffFuelConsumption 12740;
BA_ "SigType" SG_ 2566585598 EngPwrTakeOffRunTime 1;
BA_ "SPN" SG_ 2566585598 EngPwrTakeOffRunTime 12739;
BA_ "SigType" SG_ 2566585598 EngIdleFuelConsumption 1;
BA_ "SPN" SG_ 2566585598 EngIdleFuelConsumption 12738;
BA_ "SigType" SG_ 2566585598 IdleRunTime 1;
BA_ "SPN" SG_ 2566585598 IdleRunTime 12737;
BA_ "SigType" SG_ 2566585598 UrbanSpdRunTime 1;
BA_ "SPN" SG_ 2566585598 UrbanSpdRunTime 12736;
BA_ "SigType" SG_ 2566585598 PosKineticEnergyNumerator 1;
BA_ "SPN" SG_ 2566585598 PosKineticEnergyNumerator 12735;
BA_ "SigType" SG_ 2566585598 EngOutEnergy 1;
BA_ "SPN" SG_ 2566585598 EngOutEnergy 12734;
BA_ "SigType" SG_ 2566585598 EngFuelConsumption 1;
BA_ "SPN" SG_ 2566585598 EngFuelConsumption 12733;
BA_ "SigType" SG_ 2566585598 VehFuelConsumption 1;
BA_ "SPN" SG_ 2566585598 VehFuelConsumption 12732;
BA_ "SigType" SG_ 2566585598 VehDist 1;
BA_ "SPN" SG_ 2566585598 VehDist 12731;
BA_ "SigType" SG_ 2566585598 EngRunTime 1;
BA_ "SPN" SG_ 2566585598 EngRunTime 12730;
BA_ "SigType" SG_ 2566585342 EVAPSysPurgeVlvPos 1;
BA_ "SPN" SG_ 2566585342 EVAPSysPurgeVlvPos 12747;
BA_ "SigType" SG_ 2566585342 EVAPSysPurgeVlvCmd 1;
BA_ "SPN" SG_ 2566585342 EVAPSysPurgeVlvCmd 12746;
BA_ "SigType" SG_ 2566585342 EVAPSysVaporPress 1;
BA_ "SPN" SG_ 2566585342 EVAPSysVaporPress 12745;
BA_ "SigType" SG_ 2566585342 EVAPSysPurgePress 1;
BA_ "SPN" SG_ 2566585342 EVAPSysPurgePress 12744;
BA_ "SigType" SG_ 2566585086 TargetNH3StorageLvl 1;
BA_ "SPN" SG_ 2566585086 TargetNH3StorageLvl 12753;
BA_ "SigType" SG_ 2566585086 Modeled_ActualStorageLvl 1;
BA_ "SPN" SG_ 2566585086 Modeled_ActualStorageLvl 12752;
BA_ "SigType" SG_ 2566585086 TailpipeNOxMassFlow 1;
BA_ "SPN" SG_ 2566585086 TailpipeNOxMassFlow 12751;
BA_ "SigType" SG_ 2566585086 EngExhNOxMassFlow 1;
BA_ "SPN" SG_ 2566585086 EngExhNOxMassFlow 12750;
BA_ "SigType" SG_ 2566584830 TargetNH3StorageLvl 1;
BA_ "SPN" SG_ 2566584830 TargetNH3StorageLvl 12757;
BA_ "SigType" SG_ 2566584830 ModeledNH3StorageLvl 1;
BA_ "SPN" SG_ 2566584830 ModeledNH3StorageLvl 12756;
BA_ "SigType" SG_ 2566584830 OutNOxMassFlow 1;
BA_ "SPN" SG_ 2566584830 OutNOxMassFlow 12755;
BA_ "SigType" SG_ 2566584830 InletNOxMassFlow 1;
BA_ "SPN" SG_ 2566584830 InletNOxMassFlow 12754;
BA_ "SigType" SG_ 2566584318 TotalTimeSCRInletTempBelow200Cel 1;
BA_ "SPN" SG_ 2566584318 TotalTimeSCRInletTempBelow200Cel 12766;
BA_ "SystemSignalLongSymbol" SG_ 2566584318 TotalTimeSCRInletTempBelow200Cel "TotalTimeSCRInletTempBelow200Celsius";
BA_ "SigType" SG_ 2566584318 TotalEngRuntimeWithNoDEFDel 1;
BA_ "SPN" SG_ 2566584318 TotalEngRuntimeWithNoDEFDel 12765;
BA_ "SigType" SG_ 2566584318 EndingEngVehDist3 1;
BA_ "SPN" SG_ 2566584318 EndingEngVehDist3 12764;
BA_ "SigType" SG_ 2566584318 StartingEngVehDist3 1;
BA_ "SPN" SG_ 2566584318 StartingEngVehDist3 12763;
BA_ "SigType" SG_ 2566584318 EndingEngVehDist2 1;
BA_ "SPN" SG_ 2566584318 EndingEngVehDist2 12762;
BA_ "SigType" SG_ 2566584318 StartingEngVehDist2 1;
BA_ "SPN" SG_ 2566584318 StartingEngVehDist2 12761;
BA_ "SigType" SG_ 2566584318 EndingEngVehDist1 1;
BA_ "SPN" SG_ 2566584318 EndingEngVehDist1 12760;
BA_ "SigType" SG_ 2566584318 StartingEngVehDist1 1;
BA_ "SPN" SG_ 2566584318 StartingEngVehDist1 12759;
BA_ "SigType" SG_ 2566584062 GridEnergyIntoTheBat 1;
BA_ "SPN" SG_ 2566584062 GridEnergyIntoTheBat 12774;
BA_ "SigType" SG_ 2566584062 GridEnergyChargeDepletingEngRun 1;
BA_ "SPN" SG_ 2566584062 GridEnergyChargeDepletingEngRun 12773;
BA_ "SigType" SG_ 2566584062 GridEnergyChargeDepletingEngOff 1;
BA_ "SPN" SG_ 2566584062 GridEnergyChargeDepletingEngOff 12772;
BA_ "SigType" SG_ 2566584062 FuelInDriverSelChargeIncOp 1;
BA_ "SPN" SG_ 2566584062 FuelInDriverSelChargeIncOp 12771;
BA_ "SigType" SG_ 2566584062 FuelInChargeDepletingOp 1;
BA_ "SPN" SG_ 2566584062 FuelInChargeDepletingOp 12770;
BA_ "SigType" SG_ 2566584062 DistInDriverSelChargeIncOp 1;
BA_ "SPN" SG_ 2566584062 DistInDriverSelChargeIncOp 12769;
BA_ "SigType" SG_ 2566584062 DistInChargeDepletingEngRun 1;
BA_ "SPN" SG_ 2566584062 DistInChargeDepletingEngRun 12768;
BA_ "SigType" SG_ 2566584062 DistInChargeDepletingEngOff 1;
BA_ "SPN" SG_ 2566584062 DistInChargeDepletingEngOff 12767;
BA_ "SigType" SG_ 2566583806 GridEnergyIntoTheBat 1;
BA_ "SPN" SG_ 2566583806 GridEnergyIntoTheBat 12782;
BA_ "SigType" SG_ 2566583806 GridEnergyChargeDepletingEngRun 1;
BA_ "SPN" SG_ 2566583806 GridEnergyChargeDepletingEngRun 12781;
BA_ "SigType" SG_ 2566583806 GridEnergyChargeDepletingEngOff 1;
BA_ "SPN" SG_ 2566583806 GridEnergyChargeDepletingEngOff 12780;
BA_ "SigType" SG_ 2566583806 FuelInDriverSelChargeIncOp 1;
BA_ "SPN" SG_ 2566583806 FuelInDriverSelChargeIncOp 12779;
BA_ "SigType" SG_ 2566583806 FuelInChargeDepletingOp 1;
BA_ "SPN" SG_ 2566583806 FuelInChargeDepletingOp 12778;
BA_ "SigType" SG_ 2566583806 DistInDriverSelChargeIncOp 1;
BA_ "SPN" SG_ 2566583806 DistInDriverSelChargeIncOp 12777;
BA_ "SigType" SG_ 2566583806 DistInChargeDepletingEngRun 1;
BA_ "SPN" SG_ 2566583806 DistInChargeDepletingEngRun 12776;
BA_ "SigType" SG_ 2566583806 DistInChargeDepletingEngOff 1;
BA_ "SPN" SG_ 2566583806 DistInChargeDepletingEngOff 12775;
BA_ "SigType" SG_ 2566583550 GridEnergyIntoTheBat 1;
BA_ "SPN" SG_ 2566583550 GridEnergyIntoTheBat 12790;
BA_ "SigType" SG_ 2566583550 GridEnergyChargeDepletingEngRun 1;
BA_ "SPN" SG_ 2566583550 GridEnergyChargeDepletingEngRun 12789;
BA_ "SigType" SG_ 2566583550 GridEnergyChargeDepletingEngOff 1;
BA_ "SPN" SG_ 2566583550 GridEnergyChargeDepletingEngOff 12788;
BA_ "SigType" SG_ 2566583550 FuelInDriverSelChargeIncOp 1;
BA_ "SPN" SG_ 2566583550 FuelInDriverSelChargeIncOp 12787;
BA_ "SigType" SG_ 2566583550 FuelInChargeDepletingOp 1;
BA_ "SPN" SG_ 2566583550 FuelInChargeDepletingOp 12786;
BA_ "SigType" SG_ 2566583550 DistInDriverSelChargeIncOp 1;
BA_ "SPN" SG_ 2566583550 DistInDriverSelChargeIncOp 12785;
BA_ "SigType" SG_ 2566583550 DistInChargeDepletingEngRun 1;
BA_ "SPN" SG_ 2566583550 DistInChargeDepletingEngRun 12784;
BA_ "SigType" SG_ 2566583550 DistInChargeDepletingEngOff 1;
BA_ "SPN" SG_ 2566583550 DistInChargeDepletingEngOff 12783;
BA_ "SigType" SG_ 2566583294 UrbanPropulsionSysActiveTime 1;
BA_ "SPN" SG_ 2566583294 UrbanPropulsionSysActiveTime 12793;
BA_ "SigType" SG_ 2566583294 IdlePropulsionSysActiveTime 1;
BA_ "SPN" SG_ 2566583294 IdlePropulsionSysActiveTime 12792;
BA_ "SigType" SG_ 2566583294 PropulsionSysActiveTime 1;
BA_ "SPN" SG_ 2566583294 PropulsionSysActiveTime 12791;
BA_ "SigType" SG_ 2566583038 UrbanPropulsionSysActiveTime 1;
BA_ "SPN" SG_ 2566583038 UrbanPropulsionSysActiveTime 12796;
BA_ "SigType" SG_ 2566583038 IdlePropulsionSysActiveTime 1;
BA_ "SPN" SG_ 2566583038 IdlePropulsionSysActiveTime 12795;
BA_ "SigType" SG_ 2566583038 RecentPropulsionSysActiveTime 1;
BA_ "SPN" SG_ 2566583038 RecentPropulsionSysActiveTime 12794;
BA_ "SigType" SG_ 2566582782 UrbanPropulsionSysActiveTime 1;
BA_ "SPN" SG_ 2566582782 UrbanPropulsionSysActiveTime 12799;
BA_ "SigType" SG_ 2566582782 IdlePropulsionSysActiveTime 1;
BA_ "SPN" SG_ 2566582782 IdlePropulsionSysActiveTime 12798;
BA_ "SigType" SG_ 2566582782 PropulsionSysActiveTime 1;
BA_ "SPN" SG_ 2566582782 PropulsionSysActiveTime 12797;
BA_ "SigType" SG_ 2566582526 DEFUsedThisOperatingCycle 1;
BA_ "SPN" SG_ 2566582526 DEFUsedThisOperatingCycle 21225;
BA_ "SigType" SG_ 2566582526 NormalizedConversionEfficiency 1;
BA_ "SPN" SG_ 2566582526 NormalizedConversionEfficiency 12859;
BA_ "SigType" SG_ 2566582270 NormalizedConversionEfficiency 1;
BA_ "SPN" SG_ 2566582270 NormalizedConversionEfficiency 12860;
BA_ "SPN" SG_ 2566582014 One6PreliminaryFMI 12835;
BA_ "SPN" SG_ 2566582014 One5PreliminaryFMI 12834;
BA_ "SPN" SG_ 2566582014 One4PreliminaryFMI 12833;
BA_ "SPN" SG_ 2566582014 One3PreliminaryFMI 12832;
BA_ "SPN" SG_ 2566582014 One2PreliminaryFMI 12831;
BA_ "SPN" SG_ 2566582014 One1PreliminaryFMI 12830;
BA_ "SPN" SG_ 2566582014 One0PreliminaryFMI 12829;
BA_ "SPN" SG_ 2566582014 NinePreliminaryFMI 12828;
BA_ "SPN" SG_ 2566581758 EightPreliminaryFMI 12827;
BA_ "SPN" SG_ 2566581758 SevenPreliminaryFMI 12826;
BA_ "SPN" SG_ 2566581758 SixPreliminaryFMI 12825;
BA_ "SPN" SG_ 2566581758 FivePreliminaryFMI 12824;
BA_ "SPN" SG_ 2566581758 FourPreliminaryFMI 12823;
BA_ "SPN" SG_ 2566581758 ThreePreliminaryFMI 12822;
BA_ "SPN" SG_ 2566581758 TwoPreliminaryFMI 12821;
BA_ "SPN" SG_ 2566581758 PreliminaryFMI 12820;
BA_ "SPN" SG_ 2566000638 AbsTrqRateLmt 12261;
BA_ "SPN" SG_ 2566000638 AbsSpdRateLmt 12260;
BA_ "SigType" SG_ 2566000638 Counter 11;
BA_ "SPN" SG_ 2566000638 Counter 12259;
BA_ "SigType" SG_ 2566000638 CRC 12;
BA_ "SPN" SG_ 2566000638 CRC 12258;
BA_ "SigType" SG_ 2364673790 SetpointReq 1;
BA_ "SPN" SG_ 2364673790 SetpointReq 12168;
BA_ "SPN" SG_ 2364673790 SetpointModeReq 12167;
BA_ "SPN" SG_ 2364673790 LimitsReqOvrdMin 12166;
BA_ "SPN" SG_ 2364673790 LimitsReqOvrdMax 12165;
BA_ "SPN" SG_ 2364673790 LimitsReqOvrdMode 12164;
BA_ "SigType" SG_ 2364673790 Counter 11;
BA_ "SPN" SG_ 2364673790 Counter 12163;
BA_ "SigType" SG_ 2364673790 CRC 12;
BA_ "SPN" SG_ 2364673790 CRC 12162;
BA_ "SPN" SG_ 2566000126 AbsTrqRateLmt 12143;
BA_ "SPN" SG_ 2566000126 AbsSpdRateLmt 12142;
BA_ "SigType" SG_ 2566000126 Counter 11;
BA_ "SPN" SG_ 2566000126 Counter 12141;
BA_ "SigType" SG_ 2566000126 CRC 12;
BA_ "SPN" SG_ 2566000126 CRC 12140;
BA_ "SigType" SG_ 2364673278 SetpointReq 1;
BA_ "SPN" SG_ 2364673278 SetpointReq 12050;
BA_ "SPN" SG_ 2364673278 SetpointModeReq 12049;
BA_ "SPN" SG_ 2364673278 LimitsReqOvrdMin 12048;
BA_ "SPN" SG_ 2364673278 LimitsReqOvrdMax 12047;
BA_ "SPN" SG_ 2364673278 LimitsReqOvrdMode 12046;
BA_ "SigType" SG_ 2364673278 Counter 11;
BA_ "SPN" SG_ 2364673278 Counter 12045;
BA_ "SigType" SG_ 2364673278 CRC 12;
BA_ "SPN" SG_ 2364673278 CRC 12044;
BA_ "SPN" SG_ 2565999614 AbsTrqRateLmt 12025;
BA_ "SPN" SG_ 2565999614 AbsSpdRateLmt 12024;
BA_ "SigType" SG_ 2565999614 Counter 11;
BA_ "SPN" SG_ 2565999614 Counter 12023;
BA_ "SigType" SG_ 2565999614 CRC 12;
BA_ "SPN" SG_ 2565999614 CRC 12022;
BA_ "SigType" SG_ 2364672766 SetpointReq 1;
BA_ "SPN" SG_ 2364672766 SetpointReq 11932;
BA_ "SPN" SG_ 2364672766 SetpointModeReq 11931;
BA_ "SPN" SG_ 2364672766 LimitsReqOvrdMin 11930;
BA_ "SPN" SG_ 2364672766 LimitsReqOvrdMax 11929;
BA_ "SPN" SG_ 2364672766 LimitsReqOvrdMode 11928;
BA_ "SigType" SG_ 2364672766 Counter 11;
BA_ "SPN" SG_ 2364672766 Counter 11927;
BA_ "SigType" SG_ 2364672766 CRC 12;
BA_ "SPN" SG_ 2364672766 CRC 11926;
BA_ "SPN" SG_ 2565999102 AbsTrqRateLmt 11907;
BA_ "SPN" SG_ 2565999102 AbsSpdRateLmt 11906;
BA_ "SigType" SG_ 2565999102 Counter 11;
BA_ "SPN" SG_ 2565999102 Counter 11905;
BA_ "SigType" SG_ 2565999102 CRC 12;
BA_ "SPN" SG_ 2565999102 CRC 11904;
BA_ "SigType" SG_ 2364672254 SetpointReq 1;
BA_ "SPN" SG_ 2364672254 SetpointReq 11814;
BA_ "SPN" SG_ 2364672254 SetpointModeReq 11813;
BA_ "SPN" SG_ 2364672254 LimitsReqOvrdMin 11812;
BA_ "SPN" SG_ 2364672254 LimitsReqOvrdMax 11811;
BA_ "SPN" SG_ 2364672254 LimitsReqOvrdMode 11810;
BA_ "SigType" SG_ 2364672254 Counter 11;
BA_ "SPN" SG_ 2364672254 Counter 11809;
BA_ "SigType" SG_ 2364672254 CRC 12;
BA_ "SPN" SG_ 2364672254 CRC 11808;
BA_ "SigType" SG_ 2364671998 MotorOverspeed 4;
BA_ "SPN" SG_ 2364671998 MotorOverspeed 15267;
BA_ "SigType" SG_ 2364671998 MotorDir 4;
BA_ "SPN" SG_ 2364671998 MotorDir 15266;
BA_ "SigType" SG_ 2364671998 MotorSpd 1;
BA_ "SPN" SG_ 2364671998 MotorSpd 15265;
BA_ "SigType" SG_ 2364671998 RevolutionCounter 1;
BA_ "SPN" SG_ 2364671998 RevolutionCounter 12310;
BA_ "SigType" SG_ 2364671998 MotorEncoderPos 1;
BA_ "SPN" SG_ 2364671998 MotorEncoderPos 12309;
BA_ "SigType" SG_ 2364671742 RearMonitored 5;
BA_ "SPN" SG_ 2364671742 RearMonitored 12293;
BA_ "SigType" SG_ 2364671742 FrontMonitored 5;
BA_ "SPN" SG_ 2364671742 FrontMonitored 12292;
BA_ "SigType" SG_ 2364671742 RightSideMonitored 5;
BA_ "SPN" SG_ 2364671742 RightSideMonitored 12291;
BA_ "SigType" SG_ 2364671742 LeftSideMonitored 5;
BA_ "SPN" SG_ 2364671742 LeftSideMonitored 12290;
BA_ "SPN" SG_ 2364671742 BendOffProbOfMostImportantObj 12289;
BA_ "SPN" SG_ 2364671742 WarnRelevantObjDetected 12288;
BA_ "SPN" SG_ 2364671742 CollisionWarnLvl 12287;
BA_ "SPN" SG_ 2364671742 St 12286;
BA_ "SPN" SG_ 2565998078 AbsTrqRateLmt 12265;
BA_ "SPN" SG_ 2565998078 AbsSpdRateLmt 12264;
BA_ "SigType" SG_ 2565998078 Counter 11;
BA_ "SPN" SG_ 2565998078 Counter 12263;
BA_ "SigType" SG_ 2565998078 CRC 12;
BA_ "SPN" SG_ 2565998078 CRC 12262;
BA_ "SPN" SG_ 2565997822 AvailableMinTrq 12231;
BA_ "SPN" SG_ 2565997822 AvailableMaxTrq 12230;
BA_ "SigType" SG_ 2565997822 Counter 11;
BA_ "SPN" SG_ 2565997822 Counter 12229;
BA_ "SigType" SG_ 2565997822 CRC 12;
BA_ "SPN" SG_ 2565997822 CRC 12228;
BA_ "SigType" SG_ 2565997566 UnswitchedSLIV 1;
BA_ "SPN" SG_ 2565997566 UnswitchedSLIV 12161;
BA_ "SigType" SG_ 2565997566 SwitchedIgntV 1;
BA_ "SPN" SG_ 2565997566 SwitchedIgntV 12160;
BA_ "SPN" SG_ 2565997310 CurMin 12220;
BA_ "SPN" SG_ 2565997310 CurMax 12219;
BA_ "SPN" SG_ 2565997310 VMin 12218;
BA_ "SPN" SG_ 2565997310 VMax 12217;
BA_ "SigType" SG_ 2565997310 Counter 11;
BA_ "SPN" SG_ 2565997310 Counter 12216;
BA_ "SigType" SG_ 2565997310 CRC 12;
BA_ "SPN" SG_ 2565997310 CRC 12215;
BA_ "SPN" SG_ 2565997054 SpdMin 12204;
BA_ "SPN" SG_ 2565997054 SpdMax 12203;
BA_ "SPN" SG_ 2565997054 TrqMin 12202;
BA_ "SPN" SG_ 2565997054 TrqMax 12201;
BA_ "SigType" SG_ 2565997054 Counter 11;
BA_ "SPN" SG_ 2565997054 Counter 12200;
BA_ "SigType" SG_ 2565997054 CRC 12;
BA_ "SPN" SG_ 2565997054 CRC 12199;
BA_ "SPN" SG_ 2565996798 DCSidePwrMin 12192;
BA_ "SPN" SG_ 2565996798 DCSidePwrMax 12191;
BA_ "SPN" SG_ 2565996798 MechPwrMin 12190;
BA_ "SPN" SG_ 2565996798 MechPwrMax 12189;
BA_ "SigType" SG_ 2565996798 Counter 11;
BA_ "SPN" SG_ 2565996798 Counter 12188;
BA_ "SigType" SG_ 2565996798 CRC 12;
BA_ "SPN" SG_ 2565996798 CRC 12187;
BA_ "SigType" SG_ 2364669950 HVILStatus 4;
BA_ "SPN" SG_ 2364669950 HVILStatus 12159;
BA_ "SPN" SG_ 2364669950 CtrlSetpointMode 12172;
BA_ "SPN" SG_ 2364669950 CtrlLimitsOvrdMode 12171;
BA_ "SigType" SG_ 2364669950 Counter 11;
BA_ "SPN" SG_ 2364669950 Counter 12170;
BA_ "SigType" SG_ 2364669950 CRC 12;
BA_ "SPN" SG_ 2364669950 CRC 12169;
BA_ "SPN" SG_ 2565996286 AbsTrqRateLmt 12147;
BA_ "SPN" SG_ 2565996286 AbsSpdRateLmt 12146;
BA_ "SigType" SG_ 2565996286 Counter 11;
BA_ "SPN" SG_ 2565996286 Counter 12145;
BA_ "SigType" SG_ 2565996286 CRC 12;
BA_ "SPN" SG_ 2565996286 CRC 12144;
BA_ "SPN" SG_ 2565996030 AvailableMinTrq 12113;
BA_ "SPN" SG_ 2565996030 AvailableMaxTrq 12112;
BA_ "SigType" SG_ 2565996030 Counter 11;
BA_ "SPN" SG_ 2565996030 Counter 12111;
BA_ "SigType" SG_ 2565996030 CRC 12;
BA_ "SPN" SG_ 2565996030 CRC 12110;
BA_ "SigType" SG_ 2565995774 UnswitchedSLIV 1;
BA_ "SPN" SG_ 2565995774 UnswitchedSLIV 12043;
BA_ "SigType" SG_ 2565995774 SwitchedIgntV 1;
BA_ "SPN" SG_ 2565995774 SwitchedIgntV 12042;
BA_ "SPN" SG_ 2565995518 CurMin 12102;
BA_ "SPN" SG_ 2565995518 CurMax 12101;
BA_ "SPN" SG_ 2565995518 VMin 12100;
BA_ "SPN" SG_ 2565995518 VMax 12099;
BA_ "SigType" SG_ 2565995518 Counter 11;
BA_ "SPN" SG_ 2565995518 Counter 12098;
BA_ "SigType" SG_ 2565995518 CRC 12;
BA_ "SPN" SG_ 2565995518 CRC 12097;
BA_ "SPN" SG_ 2565995262 SpdMin 12086;
BA_ "SPN" SG_ 2565995262 SpdMax 12085;
BA_ "SPN" SG_ 2565995262 TrqMin 12084;
BA_ "SPN" SG_ 2565995262 TrqMax 12083;
BA_ "SigType" SG_ 2565995262 Counter 11;
BA_ "SPN" SG_ 2565995262 Counter 12082;
BA_ "SigType" SG_ 2565995262 CRC 12;
BA_ "SPN" SG_ 2565995262 CRC 12081;
BA_ "SPN" SG_ 2565995006 DCSidePwrMin 12074;
BA_ "SPN" SG_ 2565995006 DCSidePwrMax 12073;
BA_ "SPN" SG_ 2565995006 MechPwrMin 12072;
BA_ "SPN" SG_ 2565995006 MechPwrMax 12071;
BA_ "SigType" SG_ 2565995006 Counter 11;
BA_ "SPN" SG_ 2565995006 Counter 12070;
BA_ "SigType" SG_ 2565995006 CRC 12;
BA_ "SPN" SG_ 2565995006 CRC 12069;
BA_ "SigType" SG_ 2364668158 HVILStatus 4;
BA_ "SPN" SG_ 2364668158 HVILStatus 12041;
BA_ "SPN" SG_ 2364668158 CtrlSetpointMode 12054;
BA_ "SPN" SG_ 2364668158 CtrlLimitsOvrdMode 12053;
BA_ "SigType" SG_ 2364668158 Counter 11;
BA_ "SPN" SG_ 2364668158 Counter 12052;
BA_ "SigType" SG_ 2364668158 CRC 12;
BA_ "SPN" SG_ 2364668158 CRC 12051;
BA_ "SPN" SG_ 2565994494 AbsTrqRateLmt 12029;
BA_ "SPN" SG_ 2565994494 AbsSpdRateLmt 12028;
BA_ "SigType" SG_ 2565994494 Counter 11;
BA_ "SPN" SG_ 2565994494 Counter 12027;
BA_ "SigType" SG_ 2565994494 CRC 12;
BA_ "SPN" SG_ 2565994494 CRC 12026;
BA_ "SPN" SG_ 2565994238 AvailableMinTrq 11995;
BA_ "SPN" SG_ 2565994238 AvailableMaxTrq 11994;
BA_ "SigType" SG_ 2565994238 Counter 11;
BA_ "SPN" SG_ 2565994238 Counter 11993;
BA_ "SigType" SG_ 2565994238 CRC 12;
BA_ "SPN" SG_ 2565994238 CRC 11992;
BA_ "SigType" SG_ 2565993982 UnswitchedSLIV 1;
BA_ "SPN" SG_ 2565993982 UnswitchedSLIV 11925;
BA_ "SigType" SG_ 2565993982 SwitchedIgntV 1;
BA_ "SPN" SG_ 2565993982 SwitchedIgntV 11924;
BA_ "SPN" SG_ 2565993726 CurMin 11984;
BA_ "SPN" SG_ 2565993726 CurMax 11983;
BA_ "SPN" SG_ 2565993726 VMin 11982;
BA_ "SPN" SG_ 2565993726 VMax 11981;
BA_ "SigType" SG_ 2565993726 Counter 11;
BA_ "SPN" SG_ 2565993726 Counter 11980;
BA_ "SigType" SG_ 2565993726 CRC 12;
BA_ "SPN" SG_ 2565993726 CRC 11979;
BA_ "SPN" SG_ 2565993470 SpdMin 11968;
BA_ "SPN" SG_ 2565993470 SpdMax 11967;
BA_ "SPN" SG_ 2565993470 TrqMin 11966;
BA_ "SPN" SG_ 2565993470 TrqMax 11965;
BA_ "SigType" SG_ 2565993470 Counter 11;
BA_ "SPN" SG_ 2565993470 Counter 11964;
BA_ "SigType" SG_ 2565993470 CRC 12;
BA_ "SPN" SG_ 2565993470 CRC 11963;
BA_ "SPN" SG_ 2565993214 DCSidePwrMin 11956;
BA_ "SPN" SG_ 2565993214 DCSidePwrMax 11955;
BA_ "SPN" SG_ 2565993214 MechPwrMin 11954;
BA_ "SPN" SG_ 2565993214 MechPwrMax 11953;
BA_ "SigType" SG_ 2565993214 Counter 11;
BA_ "SPN" SG_ 2565993214 Counter 11952;
BA_ "SigType" SG_ 2565993214 CRC 12;
BA_ "SPN" SG_ 2565993214 CRC 11951;
BA_ "SigType" SG_ 2364666366 HVILStatus 4;
BA_ "SPN" SG_ 2364666366 HVILStatus 11923;
BA_ "SPN" SG_ 2364666366 CtrlSetpointMode 11936;
BA_ "SPN" SG_ 2364666366 CtrlLimitsOvrdMode 11935;
BA_ "SigType" SG_ 2364666366 Counter 11;
BA_ "SPN" SG_ 2364666366 Counter 11934;
BA_ "SigType" SG_ 2364666366 CRC 12;
BA_ "SPN" SG_ 2364666366 CRC 11933;
BA_ "SPN" SG_ 2565992702 AbsTrqRateLmt 11911;
BA_ "SPN" SG_ 2565992702 AbsSpdRateLmt 11910;
BA_ "SigType" SG_ 2565992702 Counter 11;
BA_ "SPN" SG_ 2565992702 Counter 11909;
BA_ "SigType" SG_ 2565992702 CRC 12;
BA_ "SPN" SG_ 2565992702 CRC 11908;
BA_ "SPN" SG_ 2565992446 AvailableMinTrq 11877;
BA_ "SPN" SG_ 2565992446 AvailableMaxTrq 11876;
BA_ "SigType" SG_ 2565992446 Counter 11;
BA_ "SPN" SG_ 2565992446 Counter 11875;
BA_ "SigType" SG_ 2565992446 CRC 12;
BA_ "SPN" SG_ 2565992446 CRC 11874;
BA_ "SigType" SG_ 2565992190 UnswitchedSLIV 1;
BA_ "SPN" SG_ 2565992190 UnswitchedSLIV 11807;
BA_ "SigType" SG_ 2565992190 SwitchedIgntV 1;
BA_ "SPN" SG_ 2565992190 SwitchedIgntV 11806;
BA_ "SPN" SG_ 2565991934 CurMin 11866;
BA_ "SPN" SG_ 2565991934 CurMax 11865;
BA_ "SPN" SG_ 2565991934 VMin 11864;
BA_ "SPN" SG_ 2565991934 VMax 11863;
BA_ "SigType" SG_ 2565991934 Counter 11;
BA_ "SPN" SG_ 2565991934 Counter 11862;
BA_ "SigType" SG_ 2565991934 CRC 12;
BA_ "SPN" SG_ 2565991934 CRC 11861;
BA_ "SPN" SG_ 2565991678 SpdMin 11850;
BA_ "SPN" SG_ 2565991678 SpdMax 11849;
BA_ "SPN" SG_ 2565991678 TrqMin 11848;
BA_ "SPN" SG_ 2565991678 TrqMax 11847;
BA_ "SigType" SG_ 2565991678 Counter 11;
BA_ "SPN" SG_ 2565991678 Counter 11846;
BA_ "SigType" SG_ 2565991678 CRC 12;
BA_ "SPN" SG_ 2565991678 CRC 11845;
BA_ "SPN" SG_ 2565991422 DCSidePwrMin 11838;
BA_ "SPN" SG_ 2565991422 DCSidePwrMax 11837;
BA_ "SPN" SG_ 2565991422 MechPwrMin 11836;
BA_ "SPN" SG_ 2565991422 MechPwrMax 11835;
BA_ "SigType" SG_ 2565991422 Counter 11;
BA_ "SPN" SG_ 2565991422 Counter 11834;
BA_ "SigType" SG_ 2565991422 CRC 12;
BA_ "SPN" SG_ 2565991422 CRC 11833;
BA_ "SigType" SG_ 2364664574 HVILStatus 4;
BA_ "SPN" SG_ 2364664574 HVILStatus 11805;
BA_ "SPN" SG_ 2364664574 CtrlSetpointMode 11818;
BA_ "SPN" SG_ 2364664574 CtrlLimitsOvrdMode 11817;
BA_ "SigType" SG_ 2364664574 Counter 11;
BA_ "SPN" SG_ 2364664574 Counter 11816;
BA_ "SigType" SG_ 2364664574 CRC 12;
BA_ "SPN" SG_ 2364664574 CRC 11815;
BA_ "SigType" SG_ 2364664318 ActualChargeRate 1;
BA_ "SPN" SG_ 2364664318 ActualChargeRate 13070;
BA_ "SigType" SG_ 2364664318 LvlNegToChassisGroundV 1;
BA_ "SPN" SG_ 2364664318 LvlNegToChassisGroundV 11711;
BA_ "SigType" SG_ 2364664318 BusVNegToChassisGroundV 1;
BA_ "SPN" SG_ 2364664318 BusVNegToChassisGroundV 11710;
BA_ "SigType" SG_ 2364664062 HVBusPassiveIsolTestResults 1;
BA_ "SPN" SG_ 2364664062 HVBusPassiveIsolTestResults 11709;
BA_ "SigType" SG_ 2364664062 HVBusActiveIsolTestResults 1;
BA_ "SPN" SG_ 2364664062 HVBusActiveIsolTestResults 11708;
BA_ "SigType" SG_ 2364664062 LowestCellStOfChargeCellNum 1;
BA_ "SPN" SG_ 2364664062 LowestCellStOfChargeCellNum 11707;
BA_ "SigType" SG_ 2364664062 LowestCellStOfChargeModuleNum 1;
BA_ "SPN" SG_ 2364664062 LowestCellStOfChargeModuleNum 11706;
BA_ "SigType" SG_ 2364664062 HighestCellStOfChargeCellNum 1;
BA_ "SPN" SG_ 2364664062 HighestCellStOfChargeCellNum 11705;
BA_ "SigType" SG_ 2364664062 HighestCellStOfChargeModuleNum 1;
BA_ "SPN" SG_ 2364664062 HighestCellStOfChargeModuleNum 11704;
VAL_ 2364673790 SetpointModeReq 31 "Don't Care/Take No Action" 30 "SAE Reserved" 29 "Manufacturer specific special mode 2" 28 "Manufacturer specific special mode 1" 27 "Manufacturer specific special mode 4" 26 "Manufacturer specific special mode 3" 25 "SAE Reserved" 24 "SAE Reserved" 23 "SAE Reserved" 22 "SAE Reserved" 21 "Inverter power down command mode" 20 "Inverter active discharge mode e.g" 19 "Manufacturer specific active mode 2" 18 "Manufacturer specific active mode 1" 17 "SAE Reserved" 16 "SAE Reserved" 15 "SAE Reserved" 14 "SAE Reserved" 13 "SAE Reserved" 12 "Enable Mechanical Power Control Mode" 11 "Enable DC Power Control Mode" 10 "Enable DC Side Current Mode" 9 "Enable DC Side Voltage Mode" 8 "Enable Speed Control Mode" 7 "Enable Torque Control Mode" 6 "Manufacturer specific passive mode 2" 5 "Manufacturer specific passive mode 1" 4 "SAE Reserved" 3 "SAE Reserved" 2 "Standby" 1 "SAE Reserved" 0 "Power On" ;
VAL_ 2364673278 SetpointModeReq 31 "Don't Care/Take No Action" 30 "SAE Reserved" 29 "Manufacturer specific special mode 2" 28 "Manufacturer specific special mode 1" 27 "Manufacturer specific special mode 4" 26 "Manufacturer specific special mode 3" 25 "SAE Reserved" 24 "SAE Reserved" 23 "SAE Reserved" 22 "SAE Reserved" 21 "Inverter power down command mode" 20 "Inverter active discharge mode e.g" 19 "Manufacturer specific active mode 2" 18 "Manufacturer specific active mode 1" 17 "SAE Reserved" 16 "SAE Reserved" 15 "SAE Reserved" 14 "SAE Reserved" 13 "SAE Reserved" 12 "Enable Mechanical Power Control Mode" 11 "Enable DC Power Control Mode" 10 "Enable DC Side Current Mode" 9 "Enable DC Side Voltage Mode" 8 "Enable Speed Control Mode" 7 "Enable Torque Control Mode" 6 "Manufacturer specific passive mode 2" 5 "Manufacturer specific passive mode 1" 4 "SAE Reserved" 3 "SAE Reserved" 2 "Standby" 1 "SAE Reserved" 0 "Power On" ;
VAL_ 2364672766 SetpointModeReq 31 "Don't Care/Take No Action" 30 "SAE Reserved" 29 "Manufacturer specific special mode 2" 28 "Manufacturer specific special mode 1" 27 "Manufacturer specific special mode 4" 26 "Manufacturer specific special mode 3" 25 "SAE Reserved" 24 "SAE Reserved" 23 "SAE Reserved" 22 "SAE Reserved" 21 "Inverter power down command mode" 20 "Inverter active discharge mode e.g" 19 "Manufacturer specific active mode 2" 18 "Manufacturer specific active mode 1" 17 "SAE Reserved" 16 "SAE Reserved" 15 "SAE Reserved" 14 "SAE Reserved" 13 "SAE Reserved" 12 "Enable Mechanical Power Control Mode" 11 "Enable DC Power Control Mode" 10 "Enable DC Side Current Mode" 9 "Enable DC Side Voltage Mode" 8 "Enable Speed Control Mode" 7 "Enable Torque Control Mode" 6 "Manufacturer specific passive mode 2" 5 "Manufacturer specific passive mode 1" 4 "SAE Reserved" 3 "SAE Reserved" 2 "Standby" 1 "SAE Reserved" 0 "Power On" ;
VAL_ 2364672254 SetpointModeReq 31 "Don't Care/Take No Action" 30 "SAE Reserved" 29 "Manufacturer specific special mode 2" 28 "Manufacturer specific special mode 1" 27 "Manufacturer specific special mode 4" 26 "Manufacturer specific special mode 3" 25 "SAE Reserved" 24 "SAE Reserved" 23 "SAE Reserved" 22 "SAE Reserved" 21 "Inverter power down command mode" 20 "Inverter active discharge mode e.g" 19 "Manufacturer specific active mode 2" 18 "Manufacturer specific active mode 1" 17 "SAE Reserved" 16 "SAE Reserved" 15 "SAE Reserved" 14 "SAE Reserved" 13 "SAE Reserved" 12 "Enable Mechanical Power Control Mode" 11 "Enable DC Power Control Mode" 10 "Enable DC Side Current Mode" 9 "Enable DC Side Voltage Mode" 8 "Enable Speed Control Mode" 7 "Enable Torque Control Mode" 6 "Manufacturer specific passive mode 2" 5 "Manufacturer specific passive mode 1" 4 "SAE Reserved" 3 "SAE Reserved" 2 "Standby" 1 "SAE Reserved" 0 "Power On" ;
VAL_ 2364671998 MotorOverspeed 3 "Not available" 2 "Error" 1 "Overspeed" 0 "No overspeed" ;
VAL_ 2364671998 MotorDir 3 "Not Available" 2 "Unknown" 1 "ClockWise" 0 "CounterClockWise" ;
VAL_ 2364671742 RearMonitored 3 "Not available" 2 "Error indication" 1 "Monitored" 0 "Not being monitored" ;
VAL_ 2364671742 FrontMonitored 3 "Not available" 2 "Error indication" 1 "Monitored" 0 "Not being monitored" ;
VAL_ 2364671742 RightSideMonitored 3 "Not available" 2 "Error indication" 1 "Monitored" 0 "Not being monitored" ;
VAL_ 2364671742 LeftSideMonitored 3 "Not available" 2 "Error indication" 1 "Monitored" 0 "Not being monitored" ;
VAL_ 2364671742 BendOffProbOfMostImportantObj 7 "signal not available / not installed" 6 "error indication" 5 "monitored object is already in a bend-off maneuver" 4 "highest probability for a bend-off maneuver of the object" 3 "high probability for a bend-off maneuver of the object" 2 "medium probability for a bend-off maneuver of the object" 1 "low probability for a bend-off maneuver of the object" 0 "no indication for a bend-off maneuver of the object" ;
VAL_ 2364671742 WarnRelevantObjDetected 7 "Not available / not installed" 6 "Error" 5 "Relevant object(s) is not being detected reliably" 2 "Multiple relevant objects are being monitored" 1 "Single relevant object is being monitored" 0 "No relevant object monitored" ;
VAL_ 2364671742 CollisionWarnLvl 15 "don't care / take no action" 7 "warning level 7" 6 "warning level 6" 5 "warning level 5" 4 "warning level 4" 3 "warning level 3" 2 "warning level 2" 1 "warning level 1" 0 "no warning" ;
VAL_ 2364671742 St 15 "not available / not installed" 14 "error indication" 8 "system performance and/or sensitivity limited" 7 "reserved" 6 "collision warning with additional system response" 5 "collision warning active with visual/audio cues" 4 "driver overrides system" 3 "system is ready and activated" 2 "system is deactivated by driver / Inform only mode" 1 "system is temporarily not available" 0 "system is not ready" ;
VAL_ 2364669950 HVILStatus 3 "Not Available" 2 "Error" 1 "HVIL Open" 0 "HVIL Closed" ;
VAL_ 2364669950 CtrlSetpointMode 31 "Not Available" 30 "Error" 29 "Manufacturer specific special mode 2" 28 "Manufacturer specific special mode 1" 27 "Manufacturer specific special mode 4" 26 "Manufacturer specific special mode 3" 25 "SAE Reserved" 24 "SAE Reserved" 23 "SAE Reserved" 22 "SAE Reserved" 21 "Inverter power down command" 20 "Inverter active discharge mode e.g" 19 "Manufacturer specific active mode 2" 18 "Manufacturer specific active mode 1" 17 "SAE Reserved" 16 "SAE Reserved" 15 "SAE Reserved" 14 "SAE Reserved" 13 "SAE Reserved" 12 "DC Power Control Mode" 11 "Mechanical Power Control Mode" 10 "DC Side Current Mode" 9 "DC Side Voltage Mode" 8 "Speed Control Mode" 7 "Torque Control Mode" 6 "Manufacturer specific passive mode 2" 5 "Manufacturer specific passive mode 1" 4 "SAE Reserved" 3 "SAE Reserved" 2 "Standby" 1 "Waiting for Operational conditions" 0 "Powered On" ;
VAL_ 2364669950 CtrlLimitsOvrdMode 15 "Not Available" 14 "Error" 13 "SAE Reserved" 12 "SAE Reserved" 11 "SAE Reserved" 10 "SAE Reserved" 9 "SAE Reserved" 8 "SAE Reserved" 7 "SAE Reserved" 6 "Mechanical Power Limits Mode" 5 "DC Side Power Limits Mode" 4 "DC Side Current Limits Mode" 3 "DC Side Voltage Limits Mode" 2 "Speed Limits Mode" 1 "Torque Limits Mode" 0 "Operating limits are not overridden" ;
VAL_ 2364668158 HVILStatus 3 "Not Available" 2 "Error" 1 "HVIL Open" 0 "HVIL Closed" ;
VAL_ 2364668158 CtrlSetpointMode 31 "Not Available" 30 "Error" 29 "Manufacturer specific special mode 2" 28 "Manufacturer specific special mode 1" 27 "Manufacturer specific special mode 4" 26 "Manufacturer specific special mode 3" 25 "SAE Reserved" 24 "SAE Reserved" 23 "SAE Reserved" 22 "SAE Reserved" 21 "Inverter power down command" 20 "Inverter active discharge mode e.g" 19 "Manufacturer specific active mode 2" 18 "Manufacturer specific active mode 1" 17 "SAE Reserved" 16 "SAE Reserved" 15 "SAE Reserved" 14 "SAE Reserved" 13 "SAE Reserved" 12 "DC Power Control Mode" 11 "Mechanical Power Control Mode" 10 "DC Side Current Mode" 9 "DC Side Voltage Mode" 8 "Speed Control Mode" 7 "Torque Control Mode" 6 "Manufacturer specific passive mode 2" 5 "Manufacturer specific passive mode 1" 4 "SAE Reserved" 3 "SAE Reserved" 2 "Standby" 1 "Waiting for Operational conditions" 0 "Powered On" ;
VAL_ 2364668158 CtrlLimitsOvrdMode 15 "Not Available" 14 "Error" 13 "SAE Reserved" 12 "SAE Reserved" 11 "SAE Reserved" 10 "SAE Reserved" 9 "SAE Reserved" 8 "SAE Reserved" 7 "SAE Reserved" 6 "Mechanical Power Limits Mode" 5 "DC Side Power Limits Mode" 4 "DC Side Current Limits Mode" 3 "DC Side Voltage Limits Mode" 2 "Speed Limits Mode" 1 "Torque Limits Mode" 0 "Operating limits are not overridden" ;
VAL_ 2364666366 HVILStatus 3 "Not Available" 2 "Error" 1 "HVIL Open" 0 "HVIL Closed" ;
VAL_ 2364666366 CtrlSetpointMode 31 "Not Available" 30 "Error" 29 "Manufacturer specific special mode 2" 28 "Manufacturer specific special mode 1" 27 "Manufacturer specific special mode 4" 26 "Manufacturer specific special mode 3" 25 "SAE Reserved" 24 "SAE Reserved" 23 "SAE Reserved" 22 "SAE Reserved" 21 "Inverter power down command" 20 "Inverter active discharge mode e.g" 19 "Manufacturer specific active mode 2" 18 "Manufacturer specific active mode 1" 17 "SAE Reserved" 16 "SAE Reserved" 15 "SAE Reserved" 14 "SAE Reserved" 13 "SAE Reserved" 12 "DC Power Control Mode" 11 "Mechanical Power Control Mode" 10 "DC Side Current Mode" 9 "DC Side Voltage Mode" 8 "Speed Control Mode" 7 "Torque Control Mode" 6 "Manufacturer specific passive mode 2" 5 "Manufacturer specific passive mode 1" 4 "SAE Reserved" 3 "SAE Reserved" 2 "Standby" 1 "Waiting for Operational conditions" 0 "Powered On" ;
VAL_ 2364666366 CtrlLimitsOvrdMode 15 "Not Available" 14 "Error" 13 "SAE Reserved" 12 "SAE Reserved" 11 "SAE Reserved" 10 "SAE Reserved" 9 "SAE Reserved" 8 "SAE Reserved" 7 "SAE Reserved" 6 "Mechanical Power Limits Mode" 5 "DC Side Power Limits Mode" 4 "DC Side Current Limits Mode" 3 "DC Side Voltage Limits Mode" 2 "Speed Limits Mode" 1 "Torque Limits Mode" 0 "Operating limits are not overridden" ;
VAL_ 2364664574 HVILStatus 3 "Not Available" 2 "Error" 1 "HVIL Open" 0 "HVIL Closed" ;
VAL_ 2364664574 CtrlSetpointMode 31 "Not Available" 30 "Error" 29 "Manufacturer specific special mode 2" 28 "Manufacturer specific special mode 1" 27 "Manufacturer specific special mode 4" 26 "Manufacturer specific special mode 3" 25 "SAE Reserved" 24 "SAE Reserved" 23 "SAE Reserved" 22 "SAE Reserved" 21 "Inverter power down command" 20 "Inverter active discharge mode e.g" 19 "Manufacturer specific active mode 2" 18 "Manufacturer specific active mode 1" 17 "SAE Reserved" 16 "SAE Reserved" 15 "SAE Reserved" 14 "SAE Reserved" 13 "SAE Reserved" 12 "DC Power Control Mode" 11 "Mechanical Power Control Mode" 10 "DC Side Current Mode" 9 "DC Side Voltage Mode" 8 "Speed Control Mode" 7 "Torque Control Mode" 6 "Manufacturer specific passive mode 2" 5 "Manufacturer specific passive mode 1" 4 "SAE Reserved" 3 "SAE Reserved" 2 "Standby" 1 "Waiting for Operational conditions" 0 "Powered On" ;
VAL_ 2364664574 CtrlLimitsOvrdMode 15 "Not Available" 14 "Error" 13 "SAE Reserved" 12 "SAE Reserved" 11 "SAE Reserved" 10 "SAE Reserved" 9 "SAE Reserved" 8 "SAE Reserved" 7 "SAE Reserved" 6 "Mechanical Power Limits Mode" 5 "DC Side Power Limits Mode" 4 "DC Side Current Limits Mode" 3 "DC Side Voltage Limits Mode" 2 "Speed Limits Mode" 1 "Torque Limits Mode" 0 "Operating limits are not overridden" ;
